VERSION "DNNBNNNYNNNNNNNNNNNNNNNNNNNNNNNNNNNNNNNNNN/4/%%%/4/'%**4NNN///"

NS_ :

BS_:

BU_: Vector__XXX SODX PC

BO_ 271 MB79_TARGET_DETECTION_4B: 8 SODX
 SG_ StdAzimuth_4 : 63|8@0+ (0.0009766,0) [0|14.31] "°"  PC
 SG_ PowerDB_4 : 7|8@0+ (1,0) [0|255] "db"  PC
 SG_ CoGRange_4 : 15|16@0- (0.01,0) [0|96] "m"  PC
 SG_ CoGDoppler_4 : 31|16@0- (0.01,0) [-140|14] "m/s"  PC
 SG_ Azimuth_4 : 47|16@0- (0.1,0) [-180|180] "°"  PC

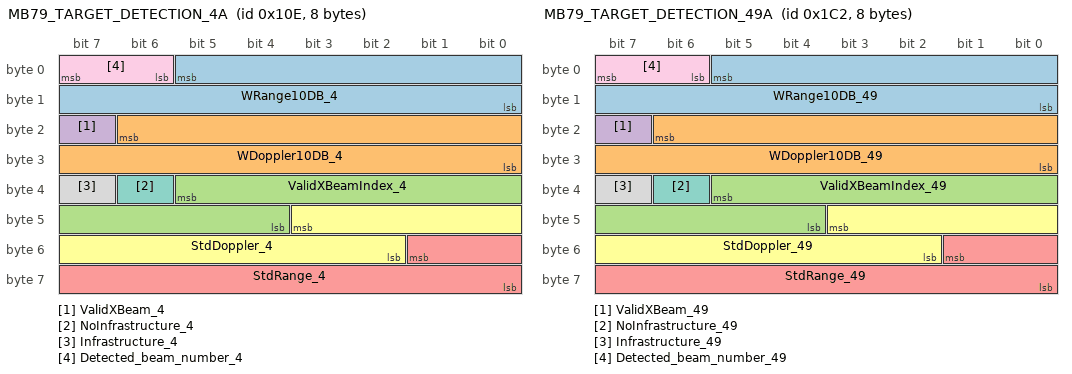
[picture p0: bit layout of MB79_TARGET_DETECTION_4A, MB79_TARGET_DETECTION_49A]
BO_ 270 MB79_TARGET_DETECTION_4A: 8 SODX
 SG_ WRange10DB_4 : 5|14@0+ (0.01,0) [0|96] "m"  PC
 SG_ WDoppler10DB_4 : 22|15@0+ (0.01,0) [0|280] "m/s"  PC
 SG_ ValidXBeamIndex_4 : 37|10@0+ (1,0) [0|0] "n/a"  PC
 SG_ ValidXBeam_4 : 23|1@0+ (1,0) [0|0] "n/a"  PC
 SG_ StdRange_4 : 49|10@0+ (0.01,0) [0|10] "m"  PC
 SG_ StdDoppler_4 : 43|10@0+ (0.01,0) [0|10] "m/s"  PC
 SG_ NoInfrastructure_4 : 38|1@0+ (1,0) [0|0] "n/a"  PC
 SG_ Infrastructure_4 : 39|1@0+ (1,0) [0|0] "n/a"  PC
 SG_ Detected_beam_number_4 : 7|2@0+ (1,0) [0|0] "n/a"  PC

BO_ 453 MB79_TARGET_DETECTION_49D: 8 SODX
 SG_ Complex4_Re_49 : 39|16@0- (1,0) [-32768|32767] "n/a"  PC
 SG_ Complex4_Im_49 : 55|16@0- (1,0) [-32768|32767] "n/a"  PC
 SG_ Complex3_Re_49 : 7|16@0- (1,0) [-32768|32767] "n/a"  PC
 SG_ Complex3_Im_49 : 23|16@0- (1,0) [-32768|32767] "n/a"  PC

BO_ 452 MB79_TARGET_DETECTION_49C: 8 SODX
 SG_ Complex2_Re_49 : 39|16@0- (1,0) [-32768|32767] "n/a"  PC
 SG_ Complex2_Im_49 : 55|16@0- (1,0) [-32768|32767] "n/a"  PC
 SG_ Complex1_Re_49 : 7|16@0- (1,0) [-32768|32767] "n/a"  PC
 SG_ Complex1_Im_49 : 23|16@0- (1,0) [-32768|32767] "n/a"  PC

BO_ 451 MB79_TARGET_DETECTION_49B: 8 SODX
 SG_ StdAzimuth_49 : 63|8@0+ (0.0009766,0) [0|14.31] "°"  PC
 SG_ PowerDB_49 : 7|8@0+ (1,0) [0|255] "db"  PC
 SG_ CoGRange_49 : 15|16@0- (0.01,0) [0|96] "m"  PC
 SG_ CoGDoppler_49 : 31|16@0- (0.01,0) [-140|14] "m/s"  PC
 SG_ Azimuth_49 : 47|16@0- (0.1,0) [-180|180] "°"  PC

BO_ 450 MB79_TARGET_DETECTION_49A: 8 SODX
 SG_ WRange10DB_49 : 5|14@0+ (0.01,0) [0|96] "m"  PC
 SG_ WDoppler10DB_49 : 22|15@0+ (0.01,0) [0|280] "m/s"  PC
 SG_ ValidXBeamIndex_49 : 37|10@0+ (1,0) [0|0] "n/a"  PC
 SG_ ValidXBeam_49 : 23|1@0+ (1,0) [0|0] "n/a"  PC
 SG_ StdRange_49 : 49|10@0+ (0.01,0) [0|10] "m"  PC
 SG_ StdDoppler_49 : 43|10@0+ (0.01,0) [0|10] "m/s"  PC
 SG_ NoInfrastructure_49 : 38|1@0+ (1,0) [0|0] "n/a"  PC
 SG_ Infrastructure_49 : 39|1@0+ (1,0) [0|0] "n/a"  PC
 SG_ Detected_beam_number_49 : 7|2@0+ (1,0) [0|0] "n/a"  PC

BO_ 449 MB79_TARGET_DETECTION_48D: 8 SODX
 SG_ Complex4_Re_48 : 39|16@0- (1,0) [-32768|32767] "n/a"  PC
 SG_ Complex4_Im_48 : 55|16@0- (1,0) [-32768|32767] "n/a"  PC
 SG_ Complex3_Re_48 : 7|16@0- (1,0) [-32768|32767] "n/a"  PC
 SG_ Complex3_Im_48 : 23|16@0- (1,0) [-32768|32767] "n/a"  PC

BO_ 448 MB79_TARGET_DETECTION_48C: 8 SODX
 SG_ Complex2_Re_48 : 39|16@0- (1,0) [-32768|32767] "n/a"  PC
 SG_ Complex2_Im_48 : 55|16@0- (1,0) [-32768|32767] "n/a"  PC
 SG_ Complex1_Re_48 : 7|16@0- (1,0) [-32768|32767] "n/a"  PC
 SG_ Complex1_Im_48 : 23|16@0- (1,0) [-32768|32767] "n/a"  PC

BO_ 447 MB79_TARGET_DETECTION_48B: 8 SODX
 SG_ StdAzimuth_48 : 63|8@0+ (0.0009766,0) [0|14.31] "°"  PC
 SG_ PowerDB_48 : 7|8@0+ (1,0) [0|255] "db"  PC
 SG_ CoGRange_48 : 15|16@0- (0.01,0) [0|96] "m"  PC
 SG_ CoGDoppler_48 : 31|16@0- (0.01,0) [-140|14] "m/s"  PC
 SG_ Azimuth_48 : 47|16@0- (0.1,0) [-180|180] "°"  PC

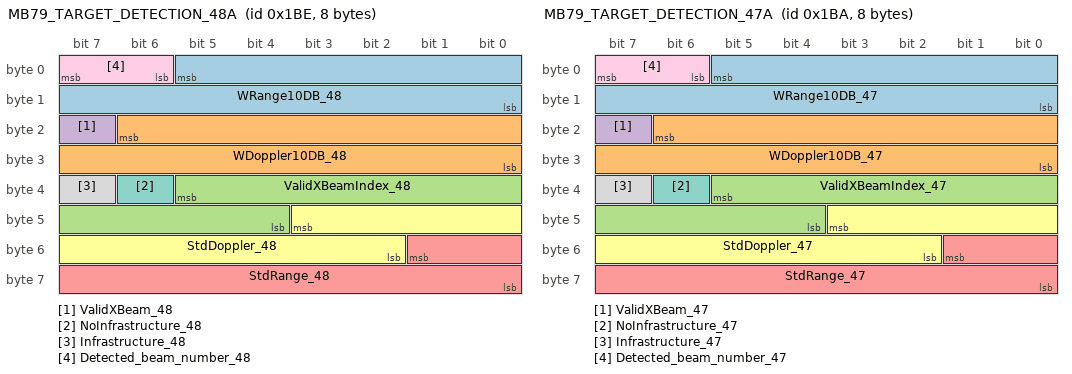
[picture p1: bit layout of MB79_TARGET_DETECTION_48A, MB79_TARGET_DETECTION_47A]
BO_ 446 MB79_TARGET_DETECTION_48A: 8 SODX
 SG_ WRange10DB_48 : 5|14@0+ (0.01,0) [0|96] "m"  PC
 SG_ WDoppler10DB_48 : 22|15@0+ (0.01,0) [0|280] "m/s"  PC
 SG_ ValidXBeamIndex_48 : 37|10@0+ (1,0) [0|0] "n/a"  PC
 SG_ ValidXBeam_48 : 23|1@0+ (1,0) [0|0] "n/a"  PC
 SG_ StdRange_48 : 49|10@0+ (0.01,0) [0|10] "m"  PC
 SG_ StdDoppler_48 : 43|10@0+ (0.01,0) [0|10] "m/s"  PC
 SG_ NoInfrastructure_48 : 38|1@0+ (1,0) [0|0] "n/a"  PC
 SG_ Infrastructure_48 : 39|1@0+ (1,0) [0|0] "n/a"  PC
 SG_ Detected_beam_number_48 : 7|2@0+ (1,0) [0|0] "n/a"  PC

BO_ 445 MB79_TARGET_DETECTION_47D: 8 SODX
 SG_ Complex4_Re_47 : 39|16@0- (1,0) [-32768|32767] "n/a"  PC
 SG_ Complex4_Im_47 : 55|16@0- (1,0) [-32768|32767] "n/a"  PC
 SG_ Complex3_Re_47 : 7|16@0- (1,0) [-32768|32767] "n/a"  PC
 SG_ Complex3_Im_47 : 23|16@0- (1,0) [-32768|32767] "n/a"  PC

BO_ 444 MB79_TARGET_DETECTION_47C: 8 SODX
 SG_ Complex2_Re_47 : 39|16@0- (1,0) [-32768|32767] "n/a"  PC
 SG_ Complex2_Im_47 : 55|16@0- (1,0) [-32768|32767] "n/a"  PC
 SG_ Complex1_Re_47 : 7|16@0- (1,0) [-32768|32767] "n/a"  PC
 SG_ Complex1_Im_47 : 23|16@0- (1,0) [-32768|32767] "n/a"  PC

BO_ 443 MB79_TARGET_DETECTION_47B: 8 SODX
 SG_ StdAzimuth_47 : 63|8@0+ (0.0009766,0) [0|14.31] "°"  PC
 SG_ PowerDB_47 : 7|8@0+ (1,0) [0|255] "db"  PC
 SG_ CoGRange_47 : 15|16@0- (0.01,0) [0|96] "m"  PC
 SG_ CoGDoppler_47 : 31|16@0- (0.01,0) [-140|14] "m/s"  PC
 SG_ Azimuth_47 : 47|16@0- (0.1,0) [-180|180] "°"  PC

BO_ 442 MB79_TARGET_DETECTION_47A: 8 SODX
 SG_ WRange10DB_47 : 5|14@0+ (0.01,0) [0|96] "m"  PC
 SG_ WDoppler10DB_47 : 22|15@0+ (0.01,0) [0|280] "m/s"  PC
 SG_ ValidXBeamIndex_47 : 37|10@0+ (1,0) [0|0] "n/a"  PC
 SG_ ValidXBeam_47 : 23|1@0+ (1,0) [0|0] "n/a"  PC
 SG_ StdRange_47 : 49|10@0+ (0.01,0) [0|10] "m"  PC
 SG_ StdDoppler_47 : 43|10@0+ (0.01,0) [0|10] "m/s"  PC
 SG_ NoInfrastructure_47 : 38|1@0+ (1,0) [0|0] "n/a"  PC
 SG_ Infrastructure_47 : 39|1@0+ (1,0) [0|0] "n/a"  PC
 SG_ Detected_beam_number_47 : 7|2@0+ (1,0) [0|0] "n/a"  PC

BO_ 441 MB79_TARGET_DETECTION_46D: 8 SODX
 SG_ Complex4_Re_46 : 39|16@0- (1,0) [-32768|32767] "n/a"  PC
 SG_ Complex4_Im_46 : 55|16@0- (1,0) [-32768|32767] "n/a"  PC
 SG_ Complex3_Re_46 : 7|16@0- (1,0) [-32768|32767] "n/a"  PC
 SG_ Complex3_Im_46 : 23|16@0- (1,0) [-32768|32767] "n/a"  PC

BO_ 440 MB79_TARGET_DETECTION_46C: 8 SODX
 SG_ Complex2_Re_46 : 39|16@0- (1,0) [-32768|32767] "n/a"  PC
 SG_ Complex2_Im_46 : 55|16@0- (1,0) [-32768|32767] "n/a"  PC
 SG_ Complex1_Re_46 : 7|16@0- (1,0) [-32768|32767] "n/a"  PC
 SG_ Complex1_Im_46 : 23|16@0- (1,0) [-32768|32767] "n/a"  PC

BO_ 439 MB79_TARGET_DETECTION_46B: 8 SODX
 SG_ StdAzimuth_46 : 63|8@0+ (0.0009766,0) [0|14.31] "°"  PC
 SG_ PowerDB_46 : 7|8@0+ (1,0) [0|255] "db"  PC
 SG_ CoGRange_46 : 15|16@0- (0.01,0) [0|96] "m"  PC
 SG_ CoGDoppler_46 : 31|16@0- (0.01,0) [-140|14] "m/s"  PC
 SG_ Azimuth_46 : 47|16@0- (0.1,0) [-180|180] "°"  PC

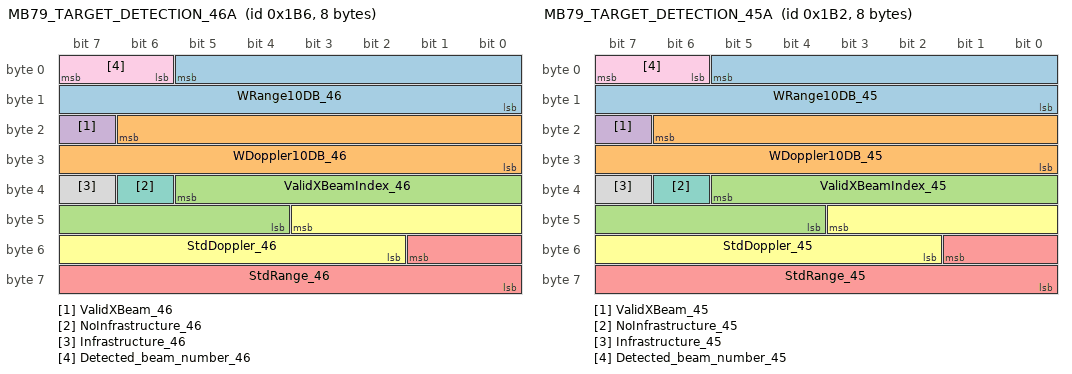
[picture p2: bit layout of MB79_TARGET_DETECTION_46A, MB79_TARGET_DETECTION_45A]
BO_ 438 MB79_TARGET_DETECTION_46A: 8 SODX
 SG_ WRange10DB_46 : 5|14@0+ (0.01,0) [0|96] "m"  PC
 SG_ WDoppler10DB_46 : 22|15@0+ (0.01,0) [0|280] "m/s"  PC
 SG_ ValidXBeamIndex_46 : 37|10@0+ (1,0) [0|0] "n/a"  PC
 SG_ ValidXBeam_46 : 23|1@0+ (1,0) [0|0] "n/a"  PC
 SG_ StdRange_46 : 49|10@0+ (0.01,0) [0|10] "m"  PC
 SG_ StdDoppler_46 : 43|10@0+ (0.01,0) [0|10] "m/s"  PC
 SG_ NoInfrastructure_46 : 38|1@0+ (1,0) [0|0] "n/a"  PC
 SG_ Infrastructure_46 : 39|1@0+ (1,0) [0|0] "n/a"  PC
 SG_ Detected_beam_number_46 : 7|2@0+ (1,0) [0|0] "n/a"  PC

BO_ 437 MB79_TARGET_DETECTION_45D: 8 SODX
 SG_ Complex4_Re_45 : 39|16@0- (1,0) [-32768|32767] "n/a"  PC
 SG_ Complex4_Im_45 : 55|16@0- (1,0) [-32768|32767] "n/a"  PC
 SG_ Complex3_Re_45 : 7|16@0- (1,0) [-32768|32767] "n/a"  PC
 SG_ Complex3_Im_45 : 23|16@0- (1,0) [-32768|32767] "n/a"  PC

BO_ 436 MB79_TARGET_DETECTION_45C: 8 SODX
 SG_ Complex2_Re_45 : 39|16@0- (1,0) [-32768|32767] "n/a"  PC
 SG_ Complex2_Im_45 : 55|16@0- (1,0) [-32768|32767] "n/a"  PC
 SG_ Complex1_Re_45 : 7|16@0- (1,0) [-32768|32767] "n/a"  PC
 SG_ Complex1_Im_45 : 23|16@0- (1,0) [-32768|32767] "n/a"  PC

BO_ 435 MB79_TARGET_DETECTION_45B: 8 SODX
 SG_ StdAzimuth_45 : 63|8@0+ (0.0009766,0) [0|14.31] "°"  PC
 SG_ PowerDB_45 : 7|8@0+ (1,0) [0|255] "db"  PC
 SG_ CoGRange_45 : 15|16@0- (0.01,0) [0|96] "m"  PC
 SG_ CoGDoppler_45 : 31|16@0- (0.01,0) [-140|14] "m/s"  PC
 SG_ Azimuth_45 : 47|16@0- (0.1,0) [-180|180] "°"  PC

BO_ 434 MB79_TARGET_DETECTION_45A: 8 SODX
 SG_ WRange10DB_45 : 5|14@0+ (0.01,0) [0|96] "m"  PC
 SG_ WDoppler10DB_45 : 22|15@0+ (0.01,0) [0|280] "m/s"  PC
 SG_ ValidXBeamIndex_45 : 37|10@0+ (1,0) [0|0] "n/a"  PC
 SG_ ValidXBeam_45 : 23|1@0+ (1,0) [0|0] "n/a"  PC
 SG_ StdRange_45 : 49|10@0+ (0.01,0) [0|10] "m"  PC
 SG_ StdDoppler_45 : 43|10@0+ (0.01,0) [0|10] "m/s"  PC
 SG_ NoInfrastructure_45 : 38|1@0+ (1,0) [0|0] "n/a"  PC
 SG_ Infrastructure_45 : 39|1@0+ (1,0) [0|0] "n/a"  PC
 SG_ Detected_beam_number_45 : 7|2@0+ (1,0) [0|0] "n/a"  PC

BO_ 433 MB79_TARGET_DETECTION_44D: 8 SODX
 SG_ Complex4_Re_44 : 39|16@0- (1,0) [-32768|32767] "n/a"  PC
 SG_ Complex4_Im_44 : 55|16@0- (1,0) [-32768|32767] "n/a"  PC
 SG_ Complex3_Re_44 : 7|16@0- (1,0) [-32768|32767] "n/a"  PC
 SG_ Complex3_Im_44 : 23|16@0- (1,0) [-32768|32767] "n/a"  PC

BO_ 432 MB79_TARGET_DETECTION_44C: 8 SODX
 SG_ Complex2_Re_44 : 39|16@0- (1,0) [-32768|32767] "n/a"  PC
 SG_ Complex2_Im_44 : 55|16@0- (1,0) [-32768|32767] "n/a"  PC
 SG_ Complex1_Re_44 : 7|16@0- (1,0) [-32768|32767] "n/a"  PC
 SG_ Complex1_Im_44 : 23|16@0- (1,0) [-32768|32767] "n/a"  PC

BO_ 431 MB79_TARGET_DETECTION_44B: 8 SODX
 SG_ StdAzimuth_44 : 63|8@0+ (0.0009766,0) [0|14.31] "°"  PC
 SG_ PowerDB_44 : 7|8@0+ (1,0) [0|255] "db"  PC
 SG_ CoGRange_44 : 15|16@0- (0.01,0) [0|96] "m"  PC
 SG_ CoGDoppler_44 : 31|16@0- (0.01,0) [-140|14] "m/s"  PC
 SG_ Azimuth_44 : 47|16@0- (0.1,0) [-180|180] "°"  PC

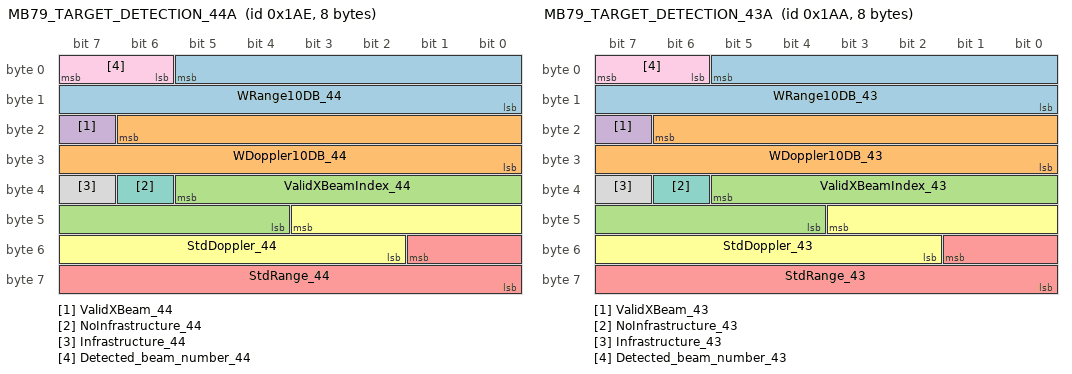
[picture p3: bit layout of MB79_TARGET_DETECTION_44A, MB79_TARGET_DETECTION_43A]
BO_ 430 MB79_TARGET_DETECTION_44A: 8 SODX
 SG_ WRange10DB_44 : 5|14@0+ (0.01,0) [0|96] "m"  PC
 SG_ WDoppler10DB_44 : 22|15@0+ (0.01,0) [0|280] "m/s"  PC
 SG_ ValidXBeamIndex_44 : 37|10@0+ (1,0) [0|0] "n/a"  PC
 SG_ ValidXBeam_44 : 23|1@0+ (1,0) [0|0] "n/a"  PC
 SG_ StdRange_44 : 49|10@0+ (0.01,0) [0|10] "m"  PC
 SG_ StdDoppler_44 : 43|10@0+ (0.01,0) [0|10] "m/s"  PC
 SG_ NoInfrastructure_44 : 38|1@0+ (1,0) [0|0] "n/a"  PC
 SG_ Infrastructure_44 : 39|1@0+ (1,0) [0|0] "n/a"  PC
 SG_ Detected_beam_number_44 : 7|2@0+ (1,0) [0|0] "n/a"  PC

BO_ 429 MB79_TARGET_DETECTION_43D: 8 SODX
 SG_ Complex4_Re_43 : 39|16@0- (1,0) [-32768|32767] "n/a"  PC
 SG_ Complex4_Im_43 : 55|16@0- (1,0) [-32768|32767] "n/a"  PC
 SG_ Complex3_Re_43 : 7|16@0- (1,0) [-32768|32767] "n/a"  PC
 SG_ Complex3_Im_43 : 23|16@0- (1,0) [-32768|32767] "n/a"  PC

BO_ 428 MB79_TARGET_DETECTION_43C: 8 SODX
 SG_ Complex2_Re_43 : 39|16@0- (1,0) [-32768|32767] "n/a"  PC
 SG_ Complex2_Im_43 : 55|16@0- (1,0) [-32768|32767] "n/a"  PC
 SG_ Complex1_Re_43 : 7|16@0- (1,0) [-32768|32767] "n/a"  PC
 SG_ Complex1_Im_43 : 23|16@0- (1,0) [-32768|32767] "n/a"  PC

BO_ 427 MB79_TARGET_DETECTION_43B: 8 SODX
 SG_ StdAzimuth_43 : 63|8@0+ (0.0009766,0) [0|14.31] "°"  PC
 SG_ PowerDB_43 : 7|8@0+ (1,0) [0|255] "db"  PC
 SG_ CoGRange_43 : 15|16@0- (0.01,0) [0|96] "m"  PC
 SG_ CoGDoppler_43 : 31|16@0- (0.01,0) [-140|14] "m/s"  PC
 SG_ Azimuth_43 : 47|16@0- (0.1,0) [-180|180] "°"  PC

BO_ 426 MB79_TARGET_DETECTION_43A: 8 SODX
 SG_ WRange10DB_43 : 5|14@0+ (0.01,0) [0|96] "m"  PC
 SG_ WDoppler10DB_43 : 22|15@0+ (0.01,0) [0|280] "m/s"  PC
 SG_ ValidXBeamIndex_43 : 37|10@0+ (1,0) [0|0] "n/a"  PC
 SG_ ValidXBeam_43 : 23|1@0+ (1,0) [0|0] "n/a"  PC
 SG_ StdRange_43 : 49|10@0+ (0.01,0) [0|10] "m"  PC
 SG_ StdDoppler_43 : 43|10@0+ (0.01,0) [0|10] "m/s"  PC
 SG_ NoInfrastructure_43 : 38|1@0+ (1,0) [0|0] "n/a"  PC
 SG_ Infrastructure_43 : 39|1@0+ (1,0) [0|0] "n/a"  PC
 SG_ Detected_beam_number_43 : 7|2@0+ (1,0) [0|0] "n/a"  PC

BO_ 425 MB79_TARGET_DETECTION_42D: 8 SODX
 SG_ Complex4_Re_42 : 39|16@0- (1,0) [-32768|32767] "n/a"  PC
 SG_ Complex4_Im_42 : 55|16@0- (1,0) [-32768|32767] "n/a"  PC
 SG_ Complex3_Re_42 : 7|16@0- (1,0) [-32768|32767] "n/a"  PC
 SG_ Complex3_Im_42 : 23|16@0- (1,0) [-32768|32767] "n/a"  PC

BO_ 424 MB79_TARGET_DETECTION_42C: 8 SODX
 SG_ Complex2_Re_42 : 39|16@0- (1,0) [-32768|32767] "n/a"  PC
 SG_ Complex2_Im_42 : 55|16@0- (1,0) [-32768|32767] "n/a"  PC
 SG_ Complex1_Re_42 : 7|16@0- (1,0) [-32768|32767] "n/a"  PC
 SG_ Complex1_Im_42 : 23|16@0- (1,0) [-32768|32767] "n/a"  PC

BO_ 423 MB79_TARGET_DETECTION_42B: 8 SODX
 SG_ StdAzimuth_42 : 63|8@0+ (0.0009766,0) [0|14.31] "°"  PC
 SG_ PowerDB_42 : 7|8@0+ (1,0) [0|255] "db"  PC
 SG_ CoGRange_42 : 15|16@0- (0.01,0) [0|96] "m"  PC
 SG_ CoGDoppler_42 : 31|16@0- (0.01,0) [-140|14] "m/s"  PC
 SG_ Azimuth_42 : 47|16@0- (0.1,0) [-180|180] "°"  PC

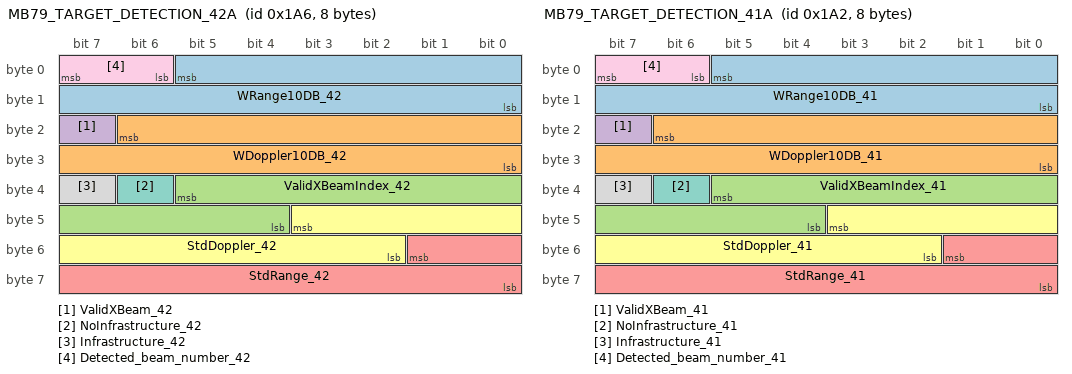
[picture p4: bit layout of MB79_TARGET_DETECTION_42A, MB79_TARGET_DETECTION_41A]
BO_ 422 MB79_TARGET_DETECTION_42A: 8 SODX
 SG_ WRange10DB_42 : 5|14@0+ (0.01,0) [0|96] "m"  PC
 SG_ WDoppler10DB_42 : 22|15@0+ (0.01,0) [0|280] "m/s"  PC
 SG_ ValidXBeamIndex_42 : 37|10@0+ (1,0) [0|0] "n/a"  PC
 SG_ ValidXBeam_42 : 23|1@0+ (1,0) [0|0] "n/a"  PC
 SG_ StdRange_42 : 49|10@0+ (0.01,0) [0|10] "m"  PC
 SG_ StdDoppler_42 : 43|10@0+ (0.01,0) [0|10] "m/s"  PC
 SG_ NoInfrastructure_42 : 38|1@0+ (1,0) [0|0] "n/a"  PC
 SG_ Infrastructure_42 : 39|1@0+ (1,0) [0|0] "n/a"  PC
 SG_ Detected_beam_number_42 : 7|2@0+ (1,0) [0|0] "n/a"  PC

BO_ 421 MB79_TARGET_DETECTION_41D: 8 SODX
 SG_ Complex4_Re_41 : 39|16@0- (1,0) [-32768|32767] "n/a"  PC
 SG_ Complex4_Im_41 : 55|16@0- (1,0) [-32768|32767] "n/a"  PC
 SG_ Complex3_Re_41 : 7|16@0- (1,0) [-32768|32767] "n/a"  PC
 SG_ Complex3_Im_41 : 23|16@0- (1,0) [-32768|32767] "n/a"  PC

BO_ 420 MB79_TARGET_DETECTION_41C: 8 SODX
 SG_ Complex2_Re_41 : 39|16@0- (1,0) [-32768|32767] "n/a"  PC
 SG_ Complex2_Im_41 : 55|16@0- (1,0) [-32768|32767] "n/a"  PC
 SG_ Complex1_Re_41 : 7|16@0- (1,0) [-32768|32767] "n/a"  PC
 SG_ Complex1_Im_41 : 23|16@0- (1,0) [-32768|32767] "n/a"  PC

BO_ 419 MB79_TARGET_DETECTION_41B: 8 SODX
 SG_ StdAzimuth_41 : 63|8@0+ (0.0009766,0) [0|14.31] "°"  PC
 SG_ PowerDB_41 : 7|8@0+ (1,0) [0|255] "db"  PC
 SG_ CoGRange_41 : 15|16@0- (0.01,0) [0|96] "m"  PC
 SG_ CoGDoppler_41 : 31|16@0- (0.01,0) [-140|14] "m/s"  PC
 SG_ Azimuth_41 : 47|16@0- (0.1,0) [-180|180] "°"  PC

BO_ 418 MB79_TARGET_DETECTION_41A: 8 SODX
 SG_ WRange10DB_41 : 5|14@0+ (0.01,0) [0|96] "m"  PC
 SG_ WDoppler10DB_41 : 22|15@0+ (0.01,0) [0|280] "m/s"  PC
 SG_ ValidXBeamIndex_41 : 37|10@0+ (1,0) [0|0] "n/a"  PC
 SG_ ValidXBeam_41 : 23|1@0+ (1,0) [0|0] "n/a"  PC
 SG_ StdRange_41 : 49|10@0+ (0.01,0) [0|10] "m"  PC
 SG_ StdDoppler_41 : 43|10@0+ (0.01,0) [0|10] "m/s"  PC
 SG_ NoInfrastructure_41 : 38|1@0+ (1,0) [0|0] "n/a"  PC
 SG_ Infrastructure_41 : 39|1@0+ (1,0) [0|0] "n/a"  PC
 SG_ Detected_beam_number_41 : 7|2@0+ (1,0) [0|0] "n/a"  PC

BO_ 417 MB79_TARGET_DETECTION_40D: 8 SODX
 SG_ Complex4_Re_40 : 39|16@0- (1,0) [-32768|32767] "n/a"  PC
 SG_ Complex4_Im_40 : 55|16@0- (1,0) [-32768|32767] "n/a"  PC
 SG_ Complex3_Re_40 : 7|16@0- (1,0) [-32768|32767] "n/a"  PC
 SG_ Complex3_Im_40 : 23|16@0- (1,0) [-32768|32767] "n/a"  PC

BO_ 416 MB79_TARGET_DETECTION_40C: 8 SODX
 SG_ Complex2_Re_40 : 39|16@0- (1,0) [-32768|32767] "n/a"  PC
 SG_ Complex2_Im_40 : 55|16@0- (1,0) [-32768|32767] "n/a"  PC
 SG_ Complex1_Re_40 : 7|16@0- (1,0) [-32768|32767] "n/a"  PC
 SG_ Complex1_Im_40 : 23|16@0- (1,0) [-32768|32767] "n/a"  PC

BO_ 415 MB79_TARGET_DETECTION_40B: 8 SODX
 SG_ StdAzimuth_40 : 63|8@0+ (0.0009766,0) [0|14.31] "°"  PC
 SG_ PowerDB_40 : 7|8@0+ (1,0) [0|255] "db"  PC
 SG_ CoGRange_40 : 15|16@0- (0.01,0) [0|96] "m"  PC
 SG_ CoGDoppler_40 : 31|16@0- (0.01,0) [-140|14] "m/s"  PC
 SG_ Azimuth_40 : 47|16@0- (0.1,0) [-180|180] "°"  PC

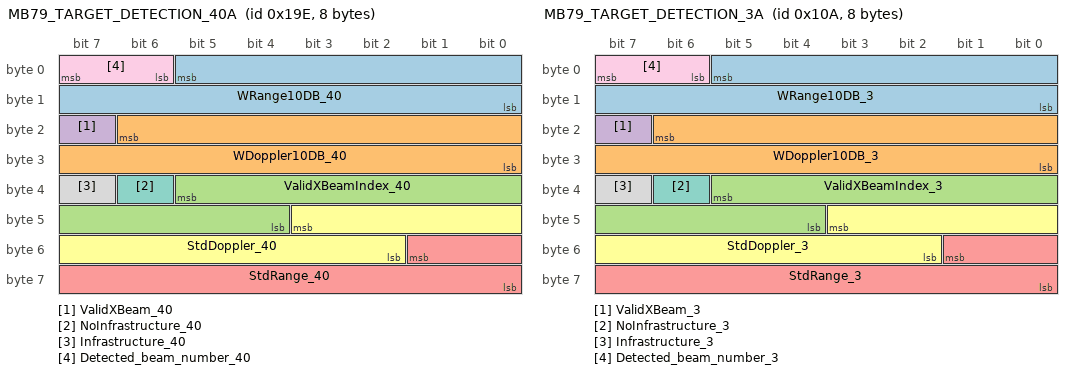
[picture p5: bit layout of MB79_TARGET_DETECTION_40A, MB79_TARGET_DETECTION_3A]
BO_ 414 MB79_TARGET_DETECTION_40A: 8 SODX
 SG_ WRange10DB_40 : 5|14@0+ (0.01,0) [0|96] "m"  PC
 SG_ WDoppler10DB_40 : 22|15@0+ (0.01,0) [0|280] "m/s"  PC
 SG_ ValidXBeamIndex_40 : 37|10@0+ (1,0) [0|0] "n/a"  PC
 SG_ ValidXBeam_40 : 23|1@0+ (1,0) [0|0] "n/a"  PC
 SG_ StdRange_40 : 49|10@0+ (0.01,0) [0|10] "m"  PC
 SG_ StdDoppler_40 : 43|10@0+ (0.01,0) [0|10] "m/s"  PC
 SG_ NoInfrastructure_40 : 38|1@0+ (1,0) [0|0] "n/a"  PC
 SG_ Infrastructure_40 : 39|1@0+ (1,0) [0|0] "n/a"  PC
 SG_ Detected_beam_number_40 : 7|2@0+ (1,0) [0|0] "n/a"  PC

BO_ 269 MB79_TARGET_DETECTION_3D: 8 SODX
 SG_ Complex4_Re_3 : 39|16@0- (1,0) [-32768|32767] "n/a"  PC
 SG_ Complex4_Im_3 : 55|16@0- (1,0) [-32768|32767] "n/a"  PC
 SG_ Complex3_Re_3 : 7|16@0- (1,0) [-32768|32767] "n/a"  PC
 SG_ Complex3_Im_3 : 23|16@0- (1,0) [-32768|32767] "n/a"  PC

BO_ 268 MB79_TARGET_DETECTION_3C: 8 SODX
 SG_ Complex2_Re_3 : 39|16@0- (1,0) [-32768|32767] "n/a"  PC
 SG_ Complex2_Im_3 : 55|16@0- (1,0) [-32768|32767] "n/a"  PC
 SG_ Complex1_Re_3 : 7|16@0- (1,0) [-32768|32767] "n/a"  PC
 SG_ Complex1_Im_3 : 23|16@0- (1,0) [-32768|32767] "n/a"  PC

BO_ 267 MB79_TARGET_DETECTION_3B: 8 SODX
 SG_ StdAzimuth_3 : 63|8@0+ (0.0009766,0) [0|14.31] "°"  PC
 SG_ PowerDB_3 : 7|8@0+ (1,0) [0|255] "db"  PC
 SG_ CoGRange_3 : 15|16@0- (0.01,0) [0|96] "m"  PC
 SG_ CoGDoppler_3 : 31|16@0- (0.01,0) [-140|14] "m/s"  PC
 SG_ Azimuth_3 : 47|16@0- (0.1,0) [-180|180] "°"  PC

BO_ 266 MB79_TARGET_DETECTION_3A: 8 SODX
 SG_ WRange10DB_3 : 5|14@0+ (0.01,0) [0|96] "m"  PC
 SG_ WDoppler10DB_3 : 22|15@0+ (0.01,0) [0|280] "m/s"  PC
 SG_ ValidXBeamIndex_3 : 37|10@0+ (1,0) [0|0] "n/a"  PC
 SG_ ValidXBeam_3 : 23|1@0+ (1,0) [0|0] "n/a"  PC
 SG_ StdRange_3 : 49|10@0+ (0.01,0) [0|10] "m"  PC
 SG_ StdDoppler_3 : 43|10@0+ (0.01,0) [0|10] "m/s"  PC
 SG_ NoInfrastructure_3 : 38|1@0+ (1,0) [0|0] "n/a"  PC
 SG_ Infrastructure_3 : 39|1@0+ (1,0) [0|0] "n/a"  PC
 SG_ Detected_beam_number_3 : 7|2@0+ (1,0) [0|0] "n/a"  PC

BO_ 413 MB79_TARGET_DETECTION_39D: 8 SODX
 SG_ Complex4_Re_39 : 39|16@0- (1,0) [-32768|32767] "n/a"  PC
 SG_ Complex4_Im_39 : 55|16@0- (1,0) [-32768|32767] "n/a"  PC
 SG_ Complex3_Re_39 : 7|16@0- (1,0) [-32768|32767] "n/a"  PC
 SG_ Complex3_Im_39 : 23|16@0- (1,0) [-32768|32767] "n/a"  PC

BO_ 412 MB79_TARGET_DETECTION_39C: 8 SODX
 SG_ Complex2_Re_39 : 39|16@0- (1,0) [-32768|32767] "n/a"  PC
 SG_ Complex2_Im_39 : 55|16@0- (1,0) [-32768|32767] "n/a"  PC
 SG_ Complex1_Re_39 : 7|16@0- (1,0) [-32768|32767] "n/a"  PC
 SG_ Complex1_Im_39 : 23|16@0- (1,0) [-32768|32767] "n/a"  PC

BO_ 411 MB79_TARGET_DETECTION_39B: 8 SODX
 SG_ StdAzimuth_39 : 63|8@0+ (0.0009766,0) [0|14.31] "°"  PC
 SG_ PowerDB_39 : 7|8@0+ (1,0) [0|255] "db"  PC
 SG_ CoGRange_39 : 15|16@0- (0.01,0) [0|96] "m"  PC
 SG_ CoGDoppler_39 : 31|16@0- (0.01,0) [-140|14] "m/s"  PC
 SG_ Azimuth_39 : 47|16@0- (0.1,0) [-180|180] "°"  PC

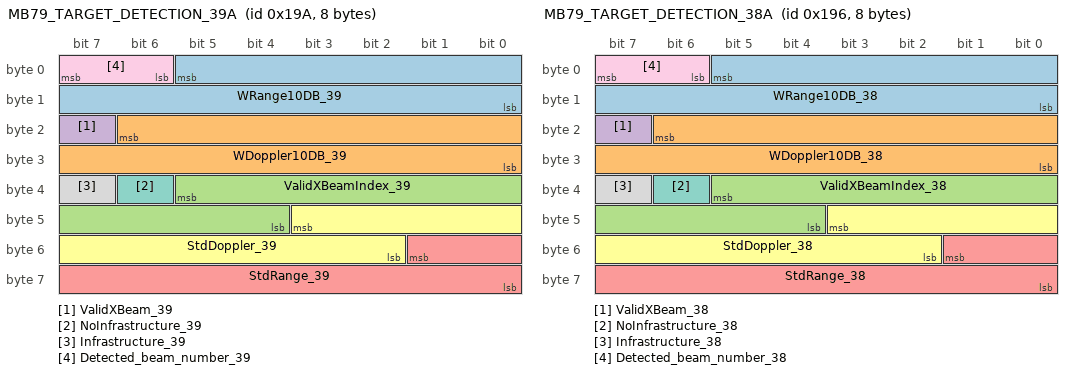
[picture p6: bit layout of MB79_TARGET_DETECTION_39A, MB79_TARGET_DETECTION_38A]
BO_ 410 MB79_TARGET_DETECTION_39A: 8 SODX
 SG_ WRange10DB_39 : 5|14@0+ (0.01,0) [0|96] "m"  PC
 SG_ WDoppler10DB_39 : 22|15@0+ (0.01,0) [0|280] "m/s"  PC
 SG_ ValidXBeamIndex_39 : 37|10@0+ (1,0) [0|0] "n/a"  PC
 SG_ ValidXBeam_39 : 23|1@0+ (1,0) [0|0] "n/a"  PC
 SG_ StdRange_39 : 49|10@0+ (0.01,0) [0|10] "m"  PC
 SG_ StdDoppler_39 : 43|10@0+ (0.01,0) [0|10] "m/s"  PC
 SG_ NoInfrastructure_39 : 38|1@0+ (1,0) [0|0] "n/a"  PC
 SG_ Infrastructure_39 : 39|1@0+ (1,0) [0|0] "n/a"  PC
 SG_ Detected_beam_number_39 : 7|2@0+ (1,0) [0|0] "n/a"  PC

BO_ 409 MB79_TARGET_DETECTION_38D: 8 SODX
 SG_ Complex4_Re_38 : 39|16@0- (1,0) [-32768|32767] "n/a"  PC
 SG_ Complex4_Im_38 : 55|16@0- (1,0) [-32768|32767] "n/a"  PC
 SG_ Complex3_Re_38 : 7|16@0- (1,0) [-32768|32767] "n/a"  PC
 SG_ Complex3_Im_38 : 23|16@0- (1,0) [-32768|32767] "n/a"  PC

BO_ 408 MB79_TARGET_DETECTION_38C: 8 SODX
 SG_ Complex2_Re_38 : 39|16@0- (1,0) [-32768|32767] "n/a"  PC
 SG_ Complex2_Im_38 : 55|16@0- (1,0) [-32768|32767] "n/a"  PC
 SG_ Complex1_Re_38 : 7|16@0- (1,0) [-32768|32767] "n/a"  PC
 SG_ Complex1_Im_38 : 23|16@0- (1,0) [-32768|32767] "n/a"  PC

BO_ 407 MB79_TARGET_DETECTION_38B: 8 SODX
 SG_ StdAzimuth_38 : 63|8@0+ (0.0009766,0) [0|14.31] "°"  PC
 SG_ PowerDB_38 : 7|8@0+ (1,0) [0|255] "db"  PC
 SG_ CoGRange_38 : 15|16@0- (0.01,0) [0|96] "m"  PC
 SG_ CoGDoppler_38 : 31|16@0- (0.01,0) [-140|14] "m/s"  PC
 SG_ Azimuth_38 : 47|16@0- (0.1,0) [-180|180] "°"  PC

BO_ 406 MB79_TARGET_DETECTION_38A: 8 SODX
 SG_ WRange10DB_38 : 5|14@0+ (0.01,0) [0|96] "m"  PC
 SG_ WDoppler10DB_38 : 22|15@0+ (0.01,0) [0|280] "m/s"  PC
 SG_ ValidXBeamIndex_38 : 37|10@0+ (1,0) [0|0] "n/a"  PC
 SG_ ValidXBeam_38 : 23|1@0+ (1,0) [0|0] "n/a"  PC
 SG_ StdRange_38 : 49|10@0+ (0.01,0) [0|10] "m"  PC
 SG_ StdDoppler_38 : 43|10@0+ (0.01,0) [0|10] "m/s"  PC
 SG_ NoInfrastructure_38 : 38|1@0+ (1,0) [0|0] "n/a"  PC
 SG_ Infrastructure_38 : 39|1@0+ (1,0) [0|0] "n/a"  PC
 SG_ Detected_beam_number_38 : 7|2@0+ (1,0) [0|0] "n/a"  PC

BO_ 405 MB79_TARGET_DETECTION_37D: 8 SODX
 SG_ Complex4_Re_37 : 39|16@0- (1,0) [-32768|32767] "n/a"  PC
 SG_ Complex4_Im_37 : 55|16@0- (1,0) [-32768|32767] "n/a"  PC
 SG_ Complex3_Re_37 : 7|16@0- (1,0) [-32768|32767] "n/a"  PC
 SG_ Complex3_Im_37 : 23|16@0- (1,0) [-32768|32767] "n/a"  PC

BO_ 404 MB79_TARGET_DETECTION_37C: 8 SODX
 SG_ Complex2_Re_37 : 39|16@0- (1,0) [-32768|32767] "n/a"  PC
 SG_ Complex2_Im_37 : 55|16@0- (1,0) [-32768|32767] "n/a"  PC
 SG_ Complex1_Re_37 : 7|16@0- (1,0) [-32768|32767] "n/a"  PC
 SG_ Complex1_Im_37 : 23|16@0- (1,0) [-32768|32767] "n/a"  PC

BO_ 403 MB79_TARGET_DETECTION_37B: 8 SODX
 SG_ StdAzimuth_37 : 63|8@0+ (0.0009766,0) [0|14.31] "°"  PC
 SG_ PowerDB_37 : 7|8@0+ (1,0) [0|255] "db"  PC
 SG_ CoGRange_37 : 15|16@0- (0.01,0) [0|96] "m"  PC
 SG_ CoGDoppler_37 : 31|16@0- (0.01,0) [-140|14] "m/s"  PC
 SG_ Azimuth_37 : 47|16@0- (0.1,0) [-180|180] "°"  PC

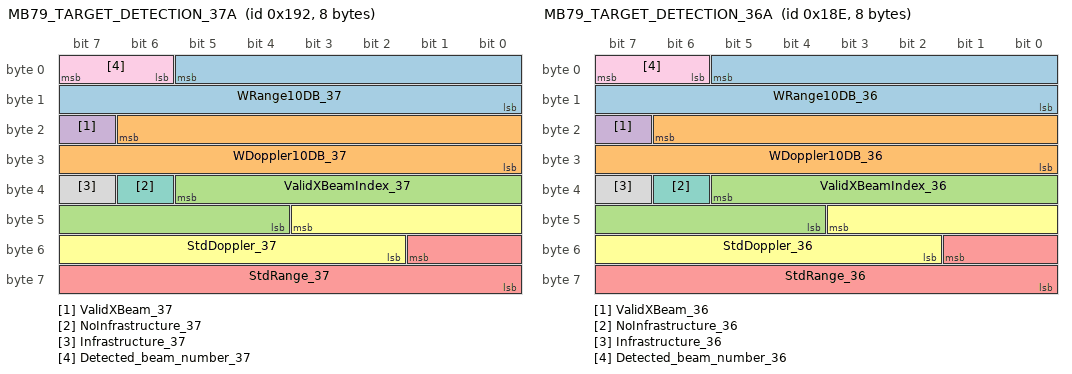
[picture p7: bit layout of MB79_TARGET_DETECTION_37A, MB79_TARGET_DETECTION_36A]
BO_ 402 MB79_TARGET_DETECTION_37A: 8 SODX
 SG_ WRange10DB_37 : 5|14@0+ (0.01,0) [0|96] "m"  PC
 SG_ WDoppler10DB_37 : 22|15@0+ (0.01,0) [0|280] "m/s"  PC
 SG_ ValidXBeamIndex_37 : 37|10@0+ (1,0) [0|0] "n/a"  PC
 SG_ ValidXBeam_37 : 23|1@0+ (1,0) [0|0] "n/a"  PC
 SG_ StdRange_37 : 49|10@0+ (0.01,0) [0|10] "m"  PC
 SG_ StdDoppler_37 : 43|10@0+ (0.01,0) [0|10] "m/s"  PC
 SG_ NoInfrastructure_37 : 38|1@0+ (1,0) [0|0] "n/a"  PC
 SG_ Infrastructure_37 : 39|1@0+ (1,0) [0|0] "n/a"  PC
 SG_ Detected_beam_number_37 : 7|2@0+ (1,0) [0|0] "n/a"  PC

BO_ 401 MB79_TARGET_DETECTION_36D: 8 SODX
 SG_ Complex4_Re_36 : 39|16@0- (1,0) [-32768|32767] "n/a"  PC
 SG_ Complex4_Im_36 : 55|16@0- (1,0) [-32768|32767] "n/a"  PC
 SG_ Complex3_Re_36 : 7|16@0- (1,0) [-32768|32767] "n/a"  PC
 SG_ Complex3_Im_36 : 23|16@0- (1,0) [-32768|32767] "n/a"  PC

BO_ 400 MB79_TARGET_DETECTION_36C: 8 SODX
 SG_ Complex2_Re_36 : 39|16@0- (1,0) [-32768|32767] "n/a"  PC
 SG_ Complex2_Im_36 : 55|16@0- (1,0) [-32768|32767] "n/a"  PC
 SG_ Complex1_Re_36 : 7|16@0- (1,0) [-32768|32767] "n/a"  PC
 SG_ Complex1_Im_36 : 23|16@0- (1,0) [-32768|32767] "n/a"  PC

BO_ 399 MB79_TARGET_DETECTION_36B: 8 SODX
 SG_ StdAzimuth_36 : 63|8@0+ (0.0009766,0) [0|14.31] "°"  PC
 SG_ PowerDB_36 : 7|8@0+ (1,0) [0|255] "db"  PC
 SG_ CoGRange_36 : 15|16@0- (0.01,0) [0|96] "m"  PC
 SG_ CoGDoppler_36 : 31|16@0- (0.01,0) [-140|14] "m/s"  PC
 SG_ Azimuth_36 : 47|16@0- (0.1,0) [-180|180] "°"  PC

BO_ 398 MB79_TARGET_DETECTION_36A: 8 SODX
 SG_ WRange10DB_36 : 5|14@0+ (0.01,0) [0|96] "m"  PC
 SG_ WDoppler10DB_36 : 22|15@0+ (0.01,0) [0|280] "m/s"  PC
 SG_ ValidXBeamIndex_36 : 37|10@0+ (1,0) [0|0] "n/a"  PC
 SG_ ValidXBeam_36 : 23|1@0+ (1,0) [0|0] "n/a"  PC
 SG_ StdRange_36 : 49|10@0+ (0.01,0) [0|10] "m"  PC
 SG_ StdDoppler_36 : 43|10@0+ (0.01,0) [0|10] "m/s"  PC
 SG_ NoInfrastructure_36 : 38|1@0+ (1,0) [0|0] "n/a"  PC
 SG_ Infrastructure_36 : 39|1@0+ (1,0) [0|0] "n/a"  PC
 SG_ Detected_beam_number_36 : 7|2@0+ (1,0) [0|0] "n/a"  PC

BO_ 397 MB79_TARGET_DETECTION_35D: 8 SODX
 SG_ Complex4_Re_35 : 39|16@0- (1,0) [-32768|32767] "n/a"  PC
 SG_ Complex4_Im_35 : 55|16@0- (1,0) [-32768|32767] "n/a"  PC
 SG_ Complex3_Re_35 : 7|16@0- (1,0) [-32768|32767] "n/a"  PC
 SG_ Complex3_Im_35 : 23|16@0- (1,0) [-32768|32767] "n/a"  PC

BO_ 396 MB79_TARGET_DETECTION_35C: 8 SODX
 SG_ Complex2_Re_35 : 39|16@0- (1,0) [-32768|32767] "n/a"  PC
 SG_ Complex2_Im_35 : 55|16@0- (1,0) [-32768|32767] "n/a"  PC
 SG_ Complex1_Re_35 : 7|16@0- (1,0) [-32768|32767] "n/a"  PC
 SG_ Complex1_Im_35 : 23|16@0- (1,0) [-32768|32767] "n/a"  PC

BO_ 395 MB79_TARGET_DETECTION_35B: 8 SODX
 SG_ StdAzimuth_35 : 63|8@0+ (0.0009766,0) [0|14.31] "°"  PC
 SG_ PowerDB_35 : 7|8@0+ (1,0) [0|255] "db"  PC
 SG_ CoGRange_35 : 15|16@0- (0.01,0) [0|96] "m"  PC
 SG_ CoGDoppler_35 : 31|16@0- (0.01,0) [-140|14] "m/s"  PC
 SG_ Azimuth_35 : 47|16@0- (0.1,0) [-180|180] "°"  PC

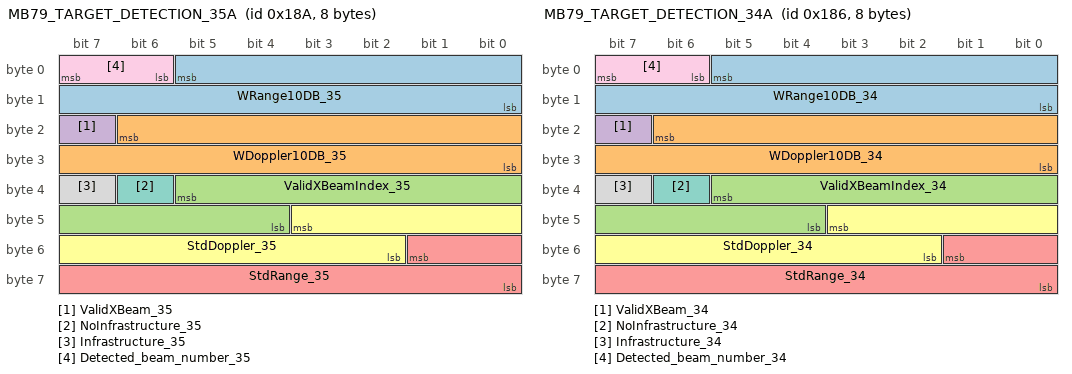
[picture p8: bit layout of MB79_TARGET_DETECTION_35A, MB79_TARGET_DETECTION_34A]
BO_ 394 MB79_TARGET_DETECTION_35A: 8 SODX
 SG_ WRange10DB_35 : 5|14@0+ (0.01,0) [0|96] "m"  PC
 SG_ WDoppler10DB_35 : 22|15@0+ (0.01,0) [0|280] "m/s"  PC
 SG_ ValidXBeamIndex_35 : 37|10@0+ (1,0) [0|0] "n/a"  PC
 SG_ ValidXBeam_35 : 23|1@0+ (1,0) [0|0] "n/a"  PC
 SG_ StdRange_35 : 49|10@0+ (0.01,0) [0|10] "m"  PC
 SG_ StdDoppler_35 : 43|10@0+ (0.01,0) [0|10] "m/s"  PC
 SG_ NoInfrastructure_35 : 38|1@0+ (1,0) [0|0] "n/a"  PC
 SG_ Infrastructure_35 : 39|1@0+ (1,0) [0|0] "n/a"  PC
 SG_ Detected_beam_number_35 : 7|2@0+ (1,0) [0|0] "n/a"  PC

BO_ 393 MB79_TARGET_DETECTION_34D: 8 SODX
 SG_ Complex4_Re_34 : 39|16@0- (1,0) [-32768|32767] "n/a"  PC
 SG_ Complex4_Im_34 : 55|16@0- (1,0) [-32768|32767] "n/a"  PC
 SG_ Complex3_Re_34 : 7|16@0- (1,0) [-32768|32767] "n/a"  PC
 SG_ Complex3_Im_34 : 23|16@0- (1,0) [-32768|32767] "n/a"  PC

BO_ 392 MB79_TARGET_DETECTION_34C: 8 SODX
 SG_ Complex2_Re_34 : 39|16@0- (1,0) [-32768|32767] "n/a"  PC
 SG_ Complex2_Im_34 : 55|16@0- (1,0) [-32768|32767] "n/a"  PC
 SG_ Complex1_Re_34 : 7|16@0- (1,0) [-32768|32767] "n/a"  PC
 SG_ Complex1_Im_34 : 23|16@0- (1,0) [-32768|32767] "n/a"  PC

BO_ 391 MB79_TARGET_DETECTION_34B: 8 SODX
 SG_ StdAzimuth_34 : 63|8@0+ (0.0009766,0) [0|14.31] "°"  PC
 SG_ PowerDB_34 : 7|8@0+ (1,0) [0|255] "db"  PC
 SG_ CoGRange_34 : 15|16@0- (0.01,0) [0|96] "m"  PC
 SG_ CoGDoppler_34 : 31|16@0- (0.01,0) [-140|14] "m/s"  PC
 SG_ Azimuth_34 : 47|16@0- (0.1,0) [-180|180] "°"  PC

BO_ 390 MB79_TARGET_DETECTION_34A: 8 SODX
 SG_ WRange10DB_34 : 5|14@0+ (0.01,0) [0|96] "m"  PC
 SG_ WDoppler10DB_34 : 22|15@0+ (0.01,0) [0|280] "m/s"  PC
 SG_ ValidXBeamIndex_34 : 37|10@0+ (1,0) [0|0] "n/a"  PC
 SG_ ValidXBeam_34 : 23|1@0+ (1,0) [0|0] "n/a"  PC
 SG_ StdRange_34 : 49|10@0+ (0.01,0) [0|10] "m"  PC
 SG_ StdDoppler_34 : 43|10@0+ (0.01,0) [0|10] "m/s"  PC
 SG_ NoInfrastructure_34 : 38|1@0+ (1,0) [0|0] "n/a"  PC
 SG_ Infrastructure_34 : 39|1@0+ (1,0) [0|0] "n/a"  PC
 SG_ Detected_beam_number_34 : 7|2@0+ (1,0) [0|0] "n/a"  PC

BO_ 389 MB79_TARGET_DETECTION_33D: 8 SODX
 SG_ Complex4_Re_33 : 39|16@0- (1,0) [-32768|32767] "n/a"  PC
 SG_ Complex4_Im_33 : 55|16@0- (1,0) [-32768|32767] "n/a"  PC
 SG_ Complex3_Re_33 : 7|16@0- (1,0) [-32768|32767] "n/a"  PC
 SG_ Complex3_Im_33 : 23|16@0- (1,0) [-32768|32767] "n/a"  PC

BO_ 388 MB79_TARGET_DETECTION_33C: 8 SODX
 SG_ Complex2_Re_33 : 39|16@0- (1,0) [-32768|32767] "n/a"  PC
 SG_ Complex2_Im_33 : 55|16@0- (1,0) [-32768|32767] "n/a"  PC
 SG_ Complex1_Re_33 : 7|16@0- (1,0) [-32768|32767] "n/a"  PC
 SG_ Complex1_Im_33 : 23|16@0- (1,0) [-32768|32767] "n/a"  PC

BO_ 387 MB79_TARGET_DETECTION_33B: 8 SODX
 SG_ StdAzimuth_33 : 63|8@0+ (0.0009766,0) [0|14.31] "°"  PC
 SG_ PowerDB_33 : 7|8@0+ (1,0) [0|255] "db"  PC
 SG_ CoGRange_33 : 15|16@0- (0.01,0) [0|96] "m"  PC
 SG_ CoGDoppler_33 : 31|16@0- (0.01,0) [-140|14] "m/s"  PC
 SG_ Azimuth_33 : 47|16@0- (0.1,0) [-180|180] "°"  PC

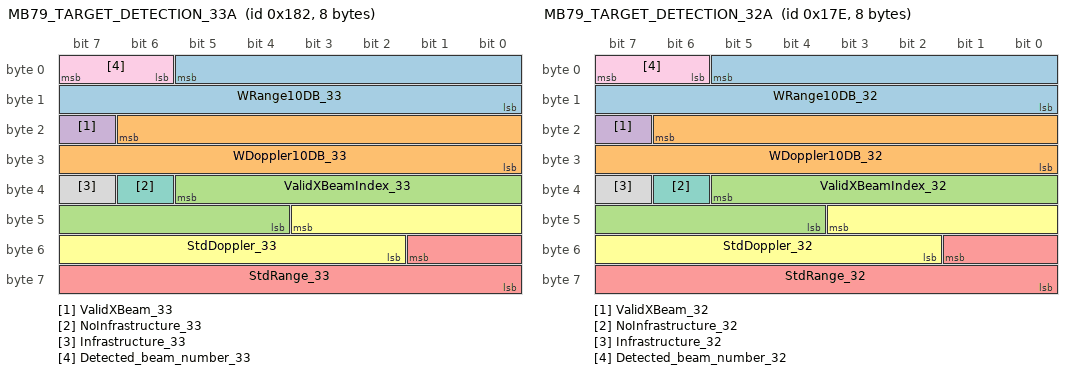
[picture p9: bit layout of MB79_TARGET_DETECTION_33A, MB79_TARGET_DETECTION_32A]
BO_ 386 MB79_TARGET_DETECTION_33A: 8 SODX
 SG_ WRange10DB_33 : 5|14@0+ (0.01,0) [0|96] "m"  PC
 SG_ WDoppler10DB_33 : 22|15@0+ (0.01,0) [0|280] "m/s"  PC
 SG_ ValidXBeamIndex_33 : 37|10@0+ (1,0) [0|0] "n/a"  PC
 SG_ ValidXBeam_33 : 23|1@0+ (1,0) [0|0] "n/a"  PC
 SG_ StdRange_33 : 49|10@0+ (0.01,0) [0|10] "m"  PC
 SG_ StdDoppler_33 : 43|10@0+ (0.01,0) [0|10] "m/s"  PC
 SG_ NoInfrastructure_33 : 38|1@0+ (1,0) [0|0] "n/a"  PC
 SG_ Infrastructure_33 : 39|1@0+ (1,0) [0|0] "n/a"  PC
 SG_ Detected_beam_number_33 : 7|2@0+ (1,0) [0|0] "n/a"  PC

BO_ 385 MB79_TARGET_DETECTION_32D: 8 SODX
 SG_ Complex4_Re_32 : 39|16@0- (1,0) [-32768|32767] "n/a"  PC
 SG_ Complex4_Im_32 : 55|16@0- (1,0) [-32768|32767] "n/a"  PC
 SG_ Complex3_Re_32 : 7|16@0- (1,0) [-32768|32767] "n/a"  PC
 SG_ Complex3_Im_32 : 23|16@0- (1,0) [-32768|32767] "n/a"  PC

BO_ 384 MB79_TARGET_DETECTION_32C: 8 SODX
 SG_ Complex2_Re_32 : 39|16@0- (1,0) [-32768|32767] "n/a"  PC
 SG_ Complex2_Im_32 : 55|16@0- (1,0) [-32768|32767] "n/a"  PC
 SG_ Complex1_Re_32 : 7|16@0- (1,0) [-32768|32767] "n/a"  PC
 SG_ Complex1_Im_32 : 23|16@0- (1,0) [-32768|32767] "n/a"  PC

BO_ 383 MB79_TARGET_DETECTION_32B: 8 SODX
 SG_ StdAzimuth_32 : 63|8@0+ (0.0009766,0) [0|14.31] "°"  PC
 SG_ PowerDB_32 : 7|8@0+ (1,0) [0|255] "db"  PC
 SG_ CoGRange_32 : 15|16@0- (0.01,0) [0|96] "m"  PC
 SG_ CoGDoppler_32 : 31|16@0- (0.01,0) [-140|14] "m/s"  PC
 SG_ Azimuth_32 : 47|16@0- (0.1,0) [-180|180] "°"  PC

BO_ 382 MB79_TARGET_DETECTION_32A: 8 SODX
 SG_ WRange10DB_32 : 5|14@0+ (0.01,0) [0|96] "m"  PC
 SG_ WDoppler10DB_32 : 22|15@0+ (0.01,0) [0|280] "m/s"  PC
 SG_ ValidXBeamIndex_32 : 37|10@0+ (1,0) [0|0] "n/a"  PC
 SG_ ValidXBeam_32 : 23|1@0+ (1,0) [0|0] "n/a"  PC
 SG_ StdRange_32 : 49|10@0+ (0.01,0) [0|10] "m"  PC
 SG_ StdDoppler_32 : 43|10@0+ (0.01,0) [0|10] "m/s"  PC
 SG_ NoInfrastructure_32 : 38|1@0+ (1,0) [0|0] "n/a"  PC
 SG_ Infrastructure_32 : 39|1@0+ (1,0) [0|0] "n/a"  PC
 SG_ Detected_beam_number_32 : 7|2@0+ (1,0) [0|0] "n/a"  PC

BO_ 381 MB79_TARGET_DETECTION_31D: 8 SODX
 SG_ Complex4_Re_31 : 39|16@0- (1,0) [-32768|32767] "n/a"  PC
 SG_ Complex4_Im_31 : 55|16@0- (1,0) [-32768|32767] "n/a"  PC
 SG_ Complex3_Re_31 : 7|16@0- (1,0) [-32768|32767] "n/a"  PC
 SG_ Complex3_Im_31 : 23|16@0- (1,0) [-32768|32767] "n/a"  PC

BO_ 380 MB79_TARGET_DETECTION_31C: 8 SODX
 SG_ Complex2_Re_31 : 39|16@0- (1,0) [-32768|32767] "n/a"  PC
 SG_ Complex2_Im_31 : 55|16@0- (1,0) [-32768|32767] "n/a"  PC
 SG_ Complex1_Re_31 : 7|16@0- (1,0) [-32768|32767] "n/a"  PC
 SG_ Complex1_Im_31 : 23|16@0- (1,0) [-32768|32767] "n/a"  PC

BO_ 379 MB79_TARGET_DETECTION_31B: 8 SODX
 SG_ StdAzimuth_31 : 63|8@0+ (0.0009766,0) [0|14.31] "°"  PC
 SG_ PowerDB_31 : 7|8@0+ (1,0) [0|255] "db"  PC
 SG_ CoGRange_31 : 15|16@0- (0.01,0) [0|96] "m"  PC
 SG_ CoGDoppler_31 : 31|16@0- (0.01,0) [-140|14] "m/s"  PC
 SG_ Azimuth_31 : 47|16@0- (0.1,0) [-180|180] "°"  PC

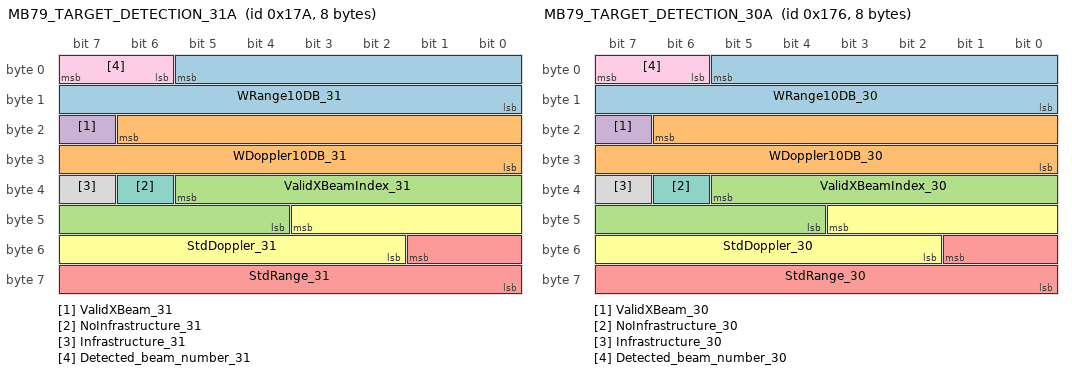
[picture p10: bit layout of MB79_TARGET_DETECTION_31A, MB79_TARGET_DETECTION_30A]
BO_ 378 MB79_TARGET_DETECTION_31A: 8 SODX
 SG_ WRange10DB_31 : 5|14@0+ (0.01,0) [0|96] "m"  PC
 SG_ WDoppler10DB_31 : 22|15@0+ (0.01,0) [0|280] "m/s"  PC
 SG_ ValidXBeamIndex_31 : 37|10@0+ (1,0) [0|0] "n/a"  PC
 SG_ ValidXBeam_31 : 23|1@0+ (1,0) [0|0] "n/a"  PC
 SG_ StdRange_31 : 49|10@0+ (0.01,0) [0|10] "m"  PC
 SG_ StdDoppler_31 : 43|10@0+ (0.01,0) [0|10] "m/s"  PC
 SG_ NoInfrastructure_31 : 38|1@0+ (1,0) [0|0] "n/a"  PC
 SG_ Infrastructure_31 : 39|1@0+ (1,0) [0|0] "n/a"  PC
 SG_ Detected_beam_number_31 : 7|2@0+ (1,0) [0|0] "n/a"  PC

BO_ 377 MB79_TARGET_DETECTION_30D: 8 SODX
 SG_ Complex4_Re_30 : 39|16@0- (1,0) [-32768|32767] "n/a"  PC
 SG_ Complex4_Im_30 : 55|16@0- (1,0) [-32768|32767] "n/a"  PC
 SG_ Complex3_Re_30 : 7|16@0- (1,0) [-32768|32767] "n/a"  PC
 SG_ Complex3_Im_30 : 23|16@0- (1,0) [-32768|32767] "n/a"  PC

BO_ 376 MB79_TARGET_DETECTION_30C: 8 SODX
 SG_ Complex2_Re_30 : 39|16@0- (1,0) [-32768|32767] "n/a"  PC
 SG_ Complex2_Im_30 : 55|16@0- (1,0) [-32768|32767] "n/a"  PC
 SG_ Complex1_Re_30 : 7|16@0- (1,0) [-32768|32767] "n/a"  PC
 SG_ Complex1_Im_30 : 23|16@0- (1,0) [-32768|32767] "n/a"  PC

BO_ 375 MB79_TARGET_DETECTION_30B: 8 SODX
 SG_ StdAzimuth_30 : 63|8@0+ (0.0009766,0) [0|14.31] "°"  PC
 SG_ PowerDB_30 : 7|8@0+ (1,0) [0|255] "db"  PC
 SG_ CoGRange_30 : 15|16@0- (0.01,0) [0|96] "m"  PC
 SG_ CoGDoppler_30 : 31|16@0- (0.01,0) [-140|14] "m/s"  PC
 SG_ Azimuth_30 : 47|16@0- (0.1,0) [-180|180] "°"  PC

BO_ 374 MB79_TARGET_DETECTION_30A: 8 SODX
 SG_ WRange10DB_30 : 5|14@0+ (0.01,0) [0|96] "m"  PC
 SG_ WDoppler10DB_30 : 22|15@0+ (0.01,0) [0|280] "m/s"  PC
 SG_ ValidXBeamIndex_30 : 37|10@0+ (1,0) [0|0] "n/a"  PC
 SG_ ValidXBeam_30 : 23|1@0+ (1,0) [0|0] "n/a"  PC
 SG_ StdRange_30 : 49|10@0+ (0.01,0) [0|10] "m"  PC
 SG_ StdDoppler_30 : 43|10@0+ (0.01,0) [0|10] "m/s"  PC
 SG_ NoInfrastructure_30 : 38|1@0+ (1,0) [0|0] "n/a"  PC
 SG_ Infrastructure_30 : 39|1@0+ (1,0) [0|0] "n/a"  PC
 SG_ Detected_beam_number_30 : 7|2@0+ (1,0) [0|0] "n/a"  PC

BO_ 265 MB79_TARGET_DETECTION_2D: 8 SODX
 SG_ Complex4_Re_2 : 39|16@0- (1,0) [-32768|32767] "n/a"  PC
 SG_ Complex4_Im_2 : 55|16@0- (1,0) [-32768|32767] "n/a"  PC
 SG_ Complex3_Re_2 : 7|16@0- (1,0) [-32768|32767] "n/a"  PC
 SG_ Complex3_Im_2 : 23|16@0- (1,0) [-32768|32767] "n/a"  PC

BO_ 264 MB79_TARGET_DETECTION_2C: 8 SODX
 SG_ Complex2_Re_2 : 39|16@0- (1,0) [-32768|32767] "n/a"  PC
 SG_ Complex2_Im_2 : 55|16@0- (1,0) [-32768|32767] "n/a"  PC
 SG_ Complex1_Re_2 : 7|16@0- (1,0) [-32768|32767] "n/a"  PC
 SG_ Complex1_Im_2 : 23|16@0- (1,0) [-32768|32767] "n/a"  PC

BO_ 263 MB79_TARGET_DETECTION_2B: 8 SODX
 SG_ StdAzimuth_2 : 63|8@0+ (0.0009766,0) [0|14.31] "°"  PC
 SG_ PowerDB_2 : 7|8@0+ (1,0) [0|255] "db"  PC
 SG_ CoGRange_2 : 15|16@0- (0.01,0) [0|96] "m"  PC
 SG_ CoGDoppler_2 : 31|16@0- (0.01,0) [-140|14] "m/s"  PC
 SG_ Azimuth_2 : 47|16@0- (0.1,0) [-180|180] "°"  PC

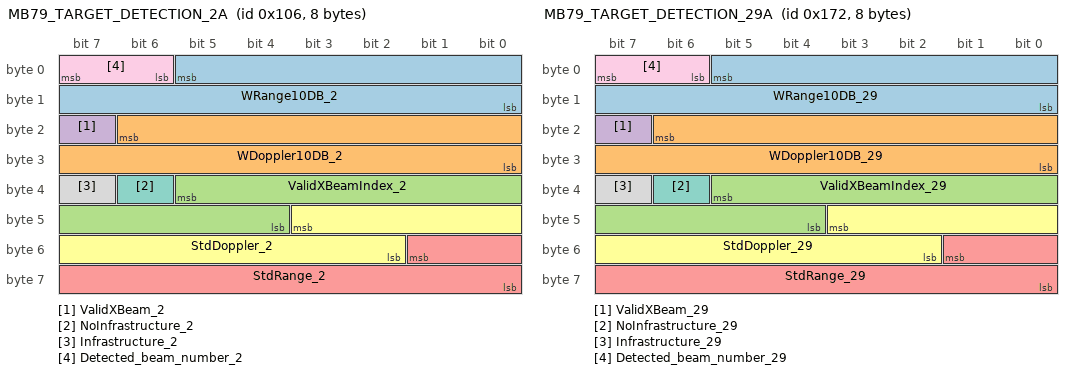
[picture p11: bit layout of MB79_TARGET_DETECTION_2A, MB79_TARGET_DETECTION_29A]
BO_ 262 MB79_TARGET_DETECTION_2A: 8 SODX
 SG_ WRange10DB_2 : 5|14@0+ (0.01,0) [0|96] "m"  PC
 SG_ WDoppler10DB_2 : 22|15@0+ (0.01,0) [0|280] "m/s"  PC
 SG_ ValidXBeamIndex_2 : 37|10@0+ (1,0) [0|0] "n/a"  PC
 SG_ ValidXBeam_2 : 23|1@0+ (1,0) [0|0] "n/a"  PC
 SG_ StdRange_2 : 49|10@0+ (0.01,0) [0|10] "m"  PC
 SG_ StdDoppler_2 : 43|10@0+ (0.01,0) [0|10] "m/s"  PC
 SG_ NoInfrastructure_2 : 38|1@0+ (1,0) [0|0] "n/a"  PC
 SG_ Infrastructure_2 : 39|1@0+ (1,0) [0|0] "n/a"  PC
 SG_ Detected_beam_number_2 : 7|2@0+ (1,0) [0|0] "n/a"  PC

BO_ 373 MB79_TARGET_DETECTION_29D: 8 SODX
 SG_ Complex4_Re_29 : 39|16@0- (1,0) [-32768|32767] "n/a"  PC
 SG_ Complex4_Im_29 : 55|16@0- (1,0) [-32768|32767] "n/a"  PC
 SG_ Complex3_Re_29 : 7|16@0- (1,0) [-32768|32767] "n/a"  PC
 SG_ Complex3_Im_29 : 23|16@0- (1,0) [-32768|32767] "n/a"  PC

BO_ 372 MB79_TARGET_DETECTION_29C: 8 SODX
 SG_ Complex2_Re_29 : 39|16@0- (1,0) [-32768|32767] "n/a"  PC
 SG_ Complex2_Im_29 : 55|16@0- (1,0) [-32768|32767] "n/a"  PC
 SG_ Complex1_Re_29 : 7|16@0- (1,0) [-32768|32767] "n/a"  PC
 SG_ Complex1_Im_29 : 23|16@0- (1,0) [-32768|32767] "n/a"  PC

BO_ 371 MB79_TARGET_DETECTION_29B: 8 SODX
 SG_ StdAzimuth_29 : 63|8@0+ (0.0009766,0) [0|14.31] "°"  PC
 SG_ PowerDB_29 : 7|8@0+ (1,0) [0|255] "db"  PC
 SG_ CoGRange_29 : 15|16@0- (0.01,0) [0|96] "m"  PC
 SG_ CoGDoppler_29 : 31|16@0- (0.01,0) [-140|14] "m/s"  PC
 SG_ Azimuth_29 : 47|16@0- (0.1,0) [-180|180] "°"  PC

BO_ 370 MB79_TARGET_DETECTION_29A: 8 SODX
 SG_ WRange10DB_29 : 5|14@0+ (0.01,0) [0|96] "m"  PC
 SG_ WDoppler10DB_29 : 22|15@0+ (0.01,0) [0|280] "m/s"  PC
 SG_ ValidXBeamIndex_29 : 37|10@0+ (1,0) [0|0] "n/a"  PC
 SG_ ValidXBeam_29 : 23|1@0+ (1,0) [0|0] "n/a"  PC
 SG_ StdRange_29 : 49|10@0+ (0.01,0) [0|10] "m"  PC
 SG_ StdDoppler_29 : 43|10@0+ (0.01,0) [0|10] "m/s"  PC
 SG_ NoInfrastructure_29 : 38|1@0+ (1,0) [0|0] "n/a"  PC
 SG_ Infrastructure_29 : 39|1@0+ (1,0) [0|0] "n/a"  PC
 SG_ Detected_beam_number_29 : 7|2@0+ (1,0) [0|0] "n/a"  PC

BO_ 369 MB79_TARGET_DETECTION_28D: 8 SODX
 SG_ Complex4_Re_28 : 39|16@0- (1,0) [-32768|32767] "n/a"  PC
 SG_ Complex4_Im_28 : 55|16@0- (1,0) [-32768|32767] "n/a"  PC
 SG_ Complex3_Re_28 : 7|16@0- (1,0) [-32768|32767] "n/a"  PC
 SG_ Complex3_Im_28 : 23|16@0- (1,0) [-32768|32767] "n/a"  PC

BO_ 368 MB79_TARGET_DETECTION_28C: 8 SODX
 SG_ Complex2_Re_28 : 39|16@0- (1,0) [-32768|32767] "n/a"  PC
 SG_ Complex2_Im_28 : 55|16@0- (1,0) [-32768|32767] "n/a"  PC
 SG_ Complex1_Re_28 : 7|16@0- (1,0) [-32768|32767] "n/a"  PC
 SG_ Complex1_Im_28 : 23|16@0- (1,0) [-32768|32767] "n/a"  PC

BO_ 367 MB79_TARGET_DETECTION_28B: 8 SODX
 SG_ StdAzimuth_28 : 63|8@0+ (0.0009766,0) [0|14.31] "°"  PC
 SG_ PowerDB_28 : 7|8@0+ (1,0) [0|255] "db"  PC
 SG_ CoGRange_28 : 15|16@0- (0.01,0) [0|96] "m"  PC
 SG_ CoGDoppler_28 : 31|16@0- (0.01,0) [-140|14] "m/s"  PC
 SG_ Azimuth_28 : 47|16@0- (0.1,0) [-180|180] "°"  PC

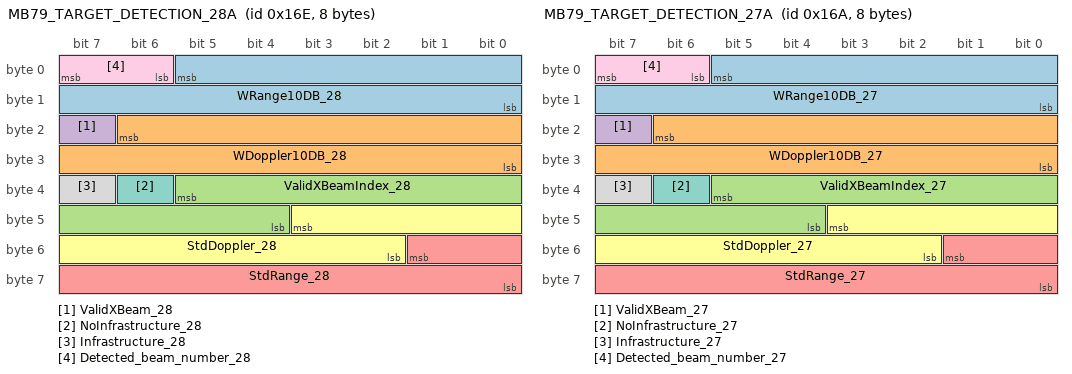
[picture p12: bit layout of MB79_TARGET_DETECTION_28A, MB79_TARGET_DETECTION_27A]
BO_ 366 MB79_TARGET_DETECTION_28A: 8 SODX
 SG_ WRange10DB_28 : 5|14@0+ (0.01,0) [0|96] "m"  PC
 SG_ WDoppler10DB_28 : 22|15@0+ (0.01,0) [0|280] "m/s"  PC
 SG_ ValidXBeamIndex_28 : 37|10@0+ (1,0) [0|0] "n/a"  PC
 SG_ ValidXBeam_28 : 23|1@0+ (1,0) [0|0] "n/a"  PC
 SG_ StdRange_28 : 49|10@0+ (0.01,0) [0|10] "m"  PC
 SG_ StdDoppler_28 : 43|10@0+ (0.01,0) [0|10] "m/s"  PC
 SG_ NoInfrastructure_28 : 38|1@0+ (1,0) [0|0] "n/a"  PC
 SG_ Infrastructure_28 : 39|1@0+ (1,0) [0|0] "n/a"  PC
 SG_ Detected_beam_number_28 : 7|2@0+ (1,0) [0|0] "n/a"  PC

BO_ 365 MB79_TARGET_DETECTION_27D: 8 SODX
 SG_ Complex4_Re_27 : 39|16@0- (1,0) [-32768|32767] "n/a"  PC
 SG_ Complex4_Im_27 : 55|16@0- (1,0) [-32768|32767] "n/a"  PC
 SG_ Complex3_Re_27 : 7|16@0- (1,0) [-32768|32767] "n/a"  PC
 SG_ Complex3_Im_27 : 23|16@0- (1,0) [-32768|32767] "n/a"  PC

BO_ 364 MB79_TARGET_DETECTION_27C: 8 SODX
 SG_ Complex2_Re_27 : 39|16@0- (1,0) [-32768|32767] "n/a"  PC
 SG_ Complex2_Im_27 : 55|16@0- (1,0) [-32768|32767] "n/a"  PC
 SG_ Complex1_Re_27 : 7|16@0- (1,0) [-32768|32767] "n/a"  PC
 SG_ Complex1_Im_27 : 23|16@0- (1,0) [-32768|32767] "n/a"  PC

BO_ 363 MB79_TARGET_DETECTION_27B: 8 SODX
 SG_ StdAzimuth_27 : 63|8@0+ (0.0009766,0) [0|14.31] "°"  PC
 SG_ PowerDB_27 : 7|8@0+ (1,0) [0|255] "db"  PC
 SG_ CoGRange_27 : 15|16@0- (0.01,0) [0|96] "m"  PC
 SG_ CoGDoppler_27 : 31|16@0- (0.01,0) [-140|14] "m/s"  PC
 SG_ Azimuth_27 : 47|16@0- (0.1,0) [-180|180] "°"  PC

BO_ 362 MB79_TARGET_DETECTION_27A: 8 SODX
 SG_ WRange10DB_27 : 5|14@0+ (0.01,0) [0|96] "m"  PC
 SG_ WDoppler10DB_27 : 22|15@0+ (0.01,0) [0|280] "m/s"  PC
 SG_ ValidXBeamIndex_27 : 37|10@0+ (1,0) [0|0] "n/a"  PC
 SG_ ValidXBeam_27 : 23|1@0+ (1,0) [0|0] "n/a"  PC
 SG_ StdRange_27 : 49|10@0+ (0.01,0) [0|10] "m"  PC
 SG_ StdDoppler_27 : 43|10@0+ (0.01,0) [0|10] "m/s"  PC
 SG_ NoInfrastructure_27 : 38|1@0+ (1,0) [0|0] "n/a"  PC
 SG_ Infrastructure_27 : 39|1@0+ (1,0) [0|0] "n/a"  PC
 SG_ Detected_beam_number_27 : 7|2@0+ (1,0) [0|0] "n/a"  PC

BO_ 361 MB79_TARGET_DETECTION_26D: 8 SODX
 SG_ Complex4_Re_26 : 39|16@0- (1,0) [-32768|32767] "n/a"  PC
 SG_ Complex4_Im_26 : 55|16@0- (1,0) [-32768|32767] "n/a"  PC
 SG_ Complex3_Re_26 : 7|16@0- (1,0) [-32768|32767] "n/a"  PC
 SG_ Complex3_Im_26 : 23|16@0- (1,0) [-32768|32767] "n/a"  PC

BO_ 360 MB79_TARGET_DETECTION_26C: 8 SODX
 SG_ Complex2_Re_26 : 39|16@0- (1,0) [-32768|32767] "n/a"  PC
 SG_ Complex2_Im_26 : 55|16@0- (1,0) [-32768|32767] "n/a"  PC
 SG_ Complex1_Re_26 : 7|16@0- (1,0) [-32768|32767] "n/a"  PC
 SG_ Complex1_Im_26 : 23|16@0- (1,0) [-32768|32767] "n/a"  PC

BO_ 359 MB79_TARGET_DETECTION_26B: 8 SODX
 SG_ StdAzimuth_26 : 63|8@0+ (0.0009766,0) [0|14.31] "°"  PC
 SG_ PowerDB_26 : 7|8@0+ (1,0) [0|255] "db"  PC
 SG_ CoGRange_26 : 15|16@0- (0.01,0) [0|96] "m"  PC
 SG_ CoGDoppler_26 : 31|16@0- (0.01,0) [-140|14] "m/s"  PC
 SG_ Azimuth_26 : 47|16@0- (0.1,0) [-180|180] "°"  PC

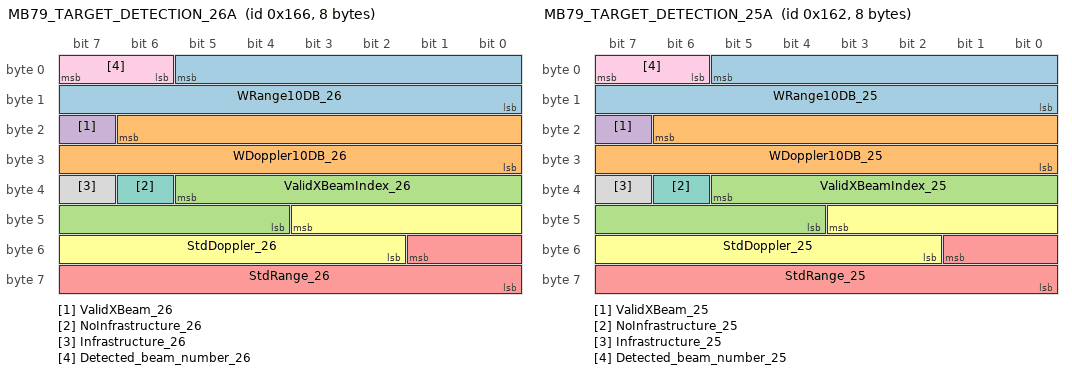
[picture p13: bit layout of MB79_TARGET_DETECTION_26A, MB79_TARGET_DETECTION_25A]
BO_ 358 MB79_TARGET_DETECTION_26A: 8 SODX
 SG_ WRange10DB_26 : 5|14@0+ (0.01,0) [0|96] "m"  PC
 SG_ WDoppler10DB_26 : 22|15@0+ (0.01,0) [0|280] "m/s"  PC
 SG_ ValidXBeamIndex_26 : 37|10@0+ (1,0) [0|0] "n/a"  PC
 SG_ ValidXBeam_26 : 23|1@0+ (1,0) [0|0] "n/a"  PC
 SG_ StdRange_26 : 49|10@0+ (0.01,0) [0|10] "m"  PC
 SG_ StdDoppler_26 : 43|10@0+ (0.01,0) [0|10] "m/s"  PC
 SG_ NoInfrastructure_26 : 38|1@0+ (1,0) [0|0] "n/a"  PC
 SG_ Infrastructure_26 : 39|1@0+ (1,0) [0|0] "n/a"  PC
 SG_ Detected_beam_number_26 : 7|2@0+ (1,0) [0|0] "n/a"  PC

BO_ 357 MB79_TARGET_DETECTION_25D: 8 SODX
 SG_ Complex4_Re_25 : 39|16@0- (1,0) [-32768|32767] "n/a"  PC
 SG_ Complex4_Im_25 : 55|16@0- (1,0) [-32768|32767] "n/a"  PC
 SG_ Complex3_Re_25 : 7|16@0- (1,0) [-32768|32767] "n/a"  PC
 SG_ Complex3_Im_25 : 23|16@0- (1,0) [-32768|32767] "n/a"  PC

BO_ 356 MB79_TARGET_DETECTION_25C: 8 SODX
 SG_ Complex2_Re_25 : 39|16@0- (1,0) [-32768|32767] "n/a"  PC
 SG_ Complex2_Im_25 : 55|16@0- (1,0) [-32768|32767] "n/a"  PC
 SG_ Complex1_Re_25 : 7|16@0- (1,0) [-32768|32767] "n/a"  PC
 SG_ Complex1_Im_25 : 23|16@0- (1,0) [-32768|32767] "n/a"  PC

BO_ 355 MB79_TARGET_DETECTION_25B: 8 SODX
 SG_ StdAzimuth_25 : 63|8@0+ (0.0009766,0) [0|14.31] "°"  PC
 SG_ PowerDB_25 : 7|8@0+ (1,0) [0|255] "db"  PC
 SG_ CoGRange_25 : 15|16@0- (0.01,0) [0|96] "m"  PC
 SG_ CoGDoppler_25 : 31|16@0- (0.01,0) [-140|14] "m/s"  PC
 SG_ Azimuth_25 : 47|16@0- (0.1,0) [-180|180] "°"  PC

BO_ 354 MB79_TARGET_DETECTION_25A: 8 SODX
 SG_ WRange10DB_25 : 5|14@0+ (0.01,0) [0|96] "m"  PC
 SG_ WDoppler10DB_25 : 22|15@0+ (0.01,0) [0|280] "m/s"  PC
 SG_ ValidXBeamIndex_25 : 37|10@0+ (1,0) [0|0] "n/a"  PC
 SG_ ValidXBeam_25 : 23|1@0+ (1,0) [0|0] "n/a"  PC
 SG_ StdRange_25 : 49|10@0+ (0.01,0) [0|10] "m"  PC
 SG_ StdDoppler_25 : 43|10@0+ (0.01,0) [0|10] "m/s"  PC
 SG_ NoInfrastructure_25 : 38|1@0+ (1,0) [0|0] "n/a"  PC
 SG_ Infrastructure_25 : 39|1@0+ (1,0) [0|0] "n/a"  PC
 SG_ Detected_beam_number_25 : 7|2@0+ (1,0) [0|0] "n/a"  PC

BO_ 353 MB79_TARGET_DETECTION_24D: 8 SODX
 SG_ Complex4_Re_24 : 39|16@0- (1,0) [-32768|32767] "n/a"  PC
 SG_ Complex4_Im_24 : 55|16@0- (1,0) [-32768|32767] "n/a"  PC
 SG_ Complex3_Re_24 : 7|16@0- (1,0) [-32768|32767] "n/a"  PC
 SG_ Complex3_Im_24 : 23|16@0- (1,0) [-32768|32767] "n/a"  PC

BO_ 352 MB79_TARGET_DETECTION_24C: 8 SODX
 SG_ Complex2_Re_24 : 39|16@0- (1,0) [-32768|32767] "n/a"  PC
 SG_ Complex2_Im_24 : 55|16@0- (1,0) [-32768|32767] "n/a"  PC
 SG_ Complex1_Re_24 : 7|16@0- (1,0) [-32768|32767] "n/a"  PC
 SG_ Complex1_Im_24 : 23|16@0- (1,0) [-32768|32767] "n/a"  PC

BO_ 351 MB79_TARGET_DETECTION_24B: 8 SODX
 SG_ StdAzimuth_24 : 63|8@0+ (0.0009766,0) [0|14.31] "°"  PC
 SG_ PowerDB_24 : 7|8@0+ (1,0) [0|255] "db"  PC
 SG_ CoGRange_24 : 15|16@0- (0.01,0) [0|96] "m"  PC
 SG_ CoGDoppler_24 : 31|16@0- (0.01,0) [-140|14] "m/s"  PC
 SG_ Azimuth_24 : 47|16@0- (0.1,0) [-180|180] "°"  PC

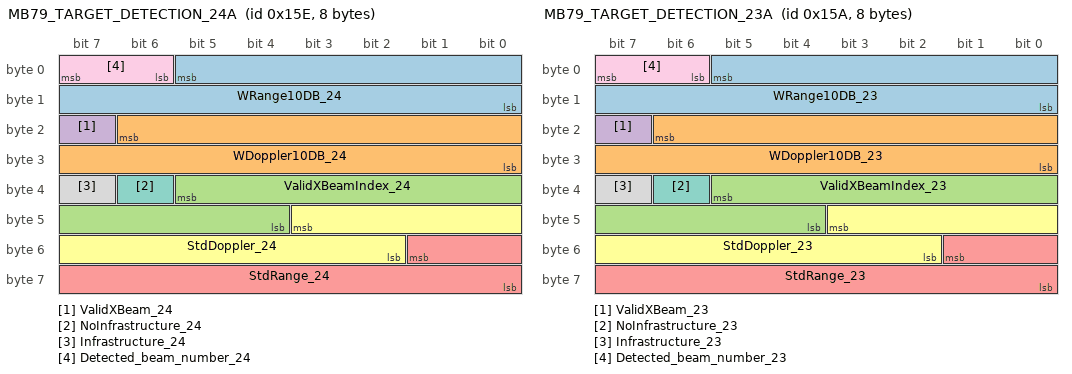
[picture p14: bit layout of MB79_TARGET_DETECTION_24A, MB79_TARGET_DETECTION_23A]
BO_ 350 MB79_TARGET_DETECTION_24A: 8 SODX
 SG_ WRange10DB_24 : 5|14@0+ (0.01,0) [0|96] "m"  PC
 SG_ WDoppler10DB_24 : 22|15@0+ (0.01,0) [0|280] "m/s"  PC
 SG_ ValidXBeamIndex_24 : 37|10@0+ (1,0) [0|0] "n/a"  PC
 SG_ ValidXBeam_24 : 23|1@0+ (1,0) [0|0] "n/a"  PC
 SG_ StdRange_24 : 49|10@0+ (0.01,0) [0|10] "m"  PC
 SG_ StdDoppler_24 : 43|10@0+ (0.01,0) [0|10] "m/s"  PC
 SG_ NoInfrastructure_24 : 38|1@0+ (1,0) [0|0] "n/a"  PC
 SG_ Infrastructure_24 : 39|1@0+ (1,0) [0|0] "n/a"  PC
 SG_ Detected_beam_number_24 : 7|2@0+ (1,0) [0|0] "n/a"  PC

BO_ 349 MB79_TARGET_DETECTION_23D: 8 SODX
 SG_ Complex4_Re_23 : 39|16@0- (1,0) [-32768|32767] "n/a"  PC
 SG_ Complex4_Im_23 : 55|16@0- (1,0) [-32768|32767] "n/a"  PC
 SG_ Complex3_Re_23 : 7|16@0- (1,0) [-32768|32767] "n/a"  PC
 SG_ Complex3_Im_23 : 23|16@0- (1,0) [-32768|32767] "n/a"  PC

BO_ 348 MB79_TARGET_DETECTION_23C: 8 SODX
 SG_ Complex2_Re_23 : 39|16@0- (1,0) [-32768|32767] "n/a"  PC
 SG_ Complex2_Im_23 : 55|16@0- (1,0) [-32768|32767] "n/a"  PC
 SG_ Complex1_Re_23 : 7|16@0- (1,0) [-32768|32767] "n/a"  PC
 SG_ Complex1_Im_23 : 23|16@0- (1,0) [-32768|32767] "n/a"  PC

BO_ 347 MB79_TARGET_DETECTION_23B: 8 SODX
 SG_ StdAzimuth_23 : 63|8@0+ (0.0009766,0) [0|14.31] "°"  PC
 SG_ PowerDB_23 : 7|8@0+ (1,0) [0|255] "db"  PC
 SG_ CoGRange_23 : 15|16@0- (0.01,0) [0|96] "m"  PC
 SG_ CoGDoppler_23 : 31|16@0- (0.01,0) [-140|14] "m/s"  PC
 SG_ Azimuth_23 : 47|16@0- (0.1,0) [-180|180] "°"  PC

BO_ 346 MB79_TARGET_DETECTION_23A: 8 SODX
 SG_ WRange10DB_23 : 5|14@0+ (0.01,0) [0|96] "m"  PC
 SG_ WDoppler10DB_23 : 22|15@0+ (0.01,0) [0|280] "m/s"  PC
 SG_ ValidXBeamIndex_23 : 37|10@0+ (1,0) [0|0] "n/a"  PC
 SG_ ValidXBeam_23 : 23|1@0+ (1,0) [0|0] "n/a"  PC
 SG_ StdRange_23 : 49|10@0+ (0.01,0) [0|10] "m"  PC
 SG_ StdDoppler_23 : 43|10@0+ (0.01,0) [0|10] "m/s"  PC
 SG_ NoInfrastructure_23 : 38|1@0+ (1,0) [0|0] "n/a"  PC
 SG_ Infrastructure_23 : 39|1@0+ (1,0) [0|0] "n/a"  PC
 SG_ Detected_beam_number_23 : 7|2@0+ (1,0) [0|0] "n/a"  PC

BO_ 345 MB79_TARGET_DETECTION_22D: 8 SODX
 SG_ Complex4_Re_22 : 39|16@0- (1,0) [-32768|32767] "n/a"  PC
 SG_ Complex4_Im_22 : 55|16@0- (1,0) [-32768|32767] "n/a"  PC
 SG_ Complex3_Re_22 : 7|16@0- (1,0) [-32768|32767] "n/a"  PC
 SG_ Complex3_Im_22 : 23|16@0- (1,0) [-32768|32767] "n/a"  PC

BO_ 344 MB79_TARGET_DETECTION_22C: 8 SODX
 SG_ Complex2_Re_22 : 39|16@0- (1,0) [-32768|32767] "n/a"  PC
 SG_ Complex2_Im_22 : 55|16@0- (1,0) [-32768|32767] "n/a"  PC
 SG_ Complex1_Re_22 : 7|16@0- (1,0) [-32768|32767] "n/a"  PC
 SG_ Complex1_Im_22 : 23|16@0- (1,0) [-32768|32767] "n/a"  PC

BO_ 343 MB79_TARGET_DETECTION_22B: 8 SODX
 SG_ StdAzimuth_22 : 63|8@0+ (0.0009766,0) [0|14.31] "°"  PC
 SG_ PowerDB_22 : 7|8@0+ (1,0) [0|255] "db"  PC
 SG_ CoGRange_22 : 15|16@0- (0.01,0) [0|96] "m"  PC
 SG_ CoGDoppler_22 : 31|16@0- (0.01,0) [-140|14] "m/s"  PC
 SG_ Azimuth_22 : 47|16@0- (0.1,0) [-180|180] "°"  PC

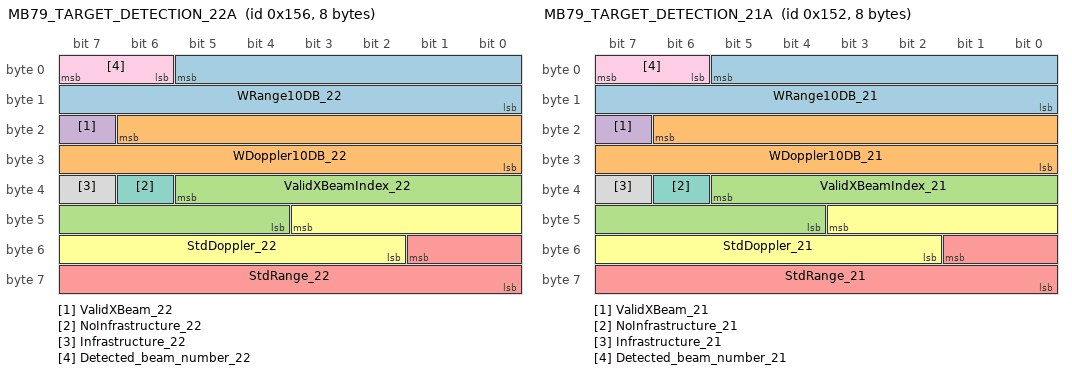
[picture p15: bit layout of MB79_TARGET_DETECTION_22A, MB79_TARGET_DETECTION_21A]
BO_ 342 MB79_TARGET_DETECTION_22A: 8 SODX
 SG_ WRange10DB_22 : 5|14@0+ (0.01,0) [0|96] "m"  PC
 SG_ WDoppler10DB_22 : 22|15@0+ (0.01,0) [0|280] "m/s"  PC
 SG_ ValidXBeamIndex_22 : 37|10@0+ (1,0) [0|0] "n/a"  PC
 SG_ ValidXBeam_22 : 23|1@0+ (1,0) [0|0] "n/a"  PC
 SG_ StdRange_22 : 49|10@0+ (0.01,0) [0|10] "m"  PC
 SG_ StdDoppler_22 : 43|10@0+ (0.01,0) [0|10] "m/s"  PC
 SG_ NoInfrastructure_22 : 38|1@0+ (1,0) [0|0] "n/a"  PC
 SG_ Infrastructure_22 : 39|1@0+ (1,0) [0|0] "n/a"  PC
 SG_ Detected_beam_number_22 : 7|2@0+ (1,0) [0|0] "n/a"  PC

BO_ 341 MB79_TARGET_DETECTION_21D: 8 SODX
 SG_ Complex4_Re_21 : 39|16@0- (1,0) [-32768|32767] "n/a"  PC
 SG_ Complex4_Im_21 : 55|16@0- (1,0) [-32768|32767] "n/a"  PC
 SG_ Complex3_Re_21 : 7|16@0- (1,0) [-32768|32767] "n/a"  PC
 SG_ Complex3_Im_21 : 23|16@0- (1,0) [-32768|32767] "n/a"  PC

BO_ 340 MB79_TARGET_DETECTION_21C: 8 SODX
 SG_ Complex2_Re_21 : 39|16@0- (1,0) [-32768|32767] "n/a"  PC
 SG_ Complex2_Im_21 : 55|16@0- (1,0) [-32768|32767] "n/a"  PC
 SG_ Complex1_Re_21 : 7|16@0- (1,0) [-32768|32767] "n/a"  PC
 SG_ Complex1_Im_21 : 23|16@0- (1,0) [-32768|32767] "n/a"  PC

BO_ 339 MB79_TARGET_DETECTION_21B: 8 SODX
 SG_ StdAzimuth_21 : 63|8@0+ (0.0009766,0) [0|14.31] "°"  PC
 SG_ PowerDB_21 : 7|8@0+ (1,0) [0|255] "db"  PC
 SG_ CoGRange_21 : 15|16@0- (0.01,0) [0|96] "m"  PC
 SG_ CoGDoppler_21 : 31|16@0- (0.01,0) [-140|14] "m/s"  PC
 SG_ Azimuth_21 : 47|16@0- (0.1,0) [-180|180] "°"  PC

BO_ 338 MB79_TARGET_DETECTION_21A: 8 SODX
 SG_ WRange10DB_21 : 5|14@0+ (0.01,0) [0|96] "m"  PC
 SG_ WDoppler10DB_21 : 22|15@0+ (0.01,0) [0|280] "m/s"  PC
 SG_ ValidXBeamIndex_21 : 37|10@0+ (1,0) [0|0] "n/a"  PC
 SG_ ValidXBeam_21 : 23|1@0+ (1,0) [0|0] "n/a"  PC
 SG_ StdRange_21 : 49|10@0+ (0.01,0) [0|10] "m"  PC
 SG_ StdDoppler_21 : 43|10@0+ (0.01,0) [0|10] "m/s"  PC
 SG_ NoInfrastructure_21 : 38|1@0+ (1,0) [0|0] "n/a"  PC
 SG_ Infrastructure_21 : 39|1@0+ (1,0) [0|0] "n/a"  PC
 SG_ Detected_beam_number_21 : 7|2@0+ (1,0) [0|0] "n/a"  PC

BO_ 337 MB79_TARGET_DETECTION_20D: 8 SODX
 SG_ Complex4_Re_20 : 39|16@0- (1,0) [-32768|32767] "n/a"  PC
 SG_ Complex4_Im_20 : 55|16@0- (1,0) [-32768|32767] "n/a"  PC
 SG_ Complex3_Re_20 : 7|16@0- (1,0) [-32768|32767] "n/a"  PC
 SG_ Complex3_Im_20 : 23|16@0- (1,0) [-32768|32767] "n/a"  PC

BO_ 336 MB79_TARGET_DETECTION_20C: 8 SODX
 SG_ Complex2_Re_20 : 39|16@0- (1,0) [-32768|32767] "n/a"  PC
 SG_ Complex2_Im_20 : 55|16@0- (1,0) [-32768|32767] "n/a"  PC
 SG_ Complex1_Re_20 : 7|16@0- (1,0) [-32768|32767] "n/a"  PC
 SG_ Complex1_Im_20 : 23|16@0- (1,0) [-32768|32767] "n/a"  PC

BO_ 335 MB79_TARGET_DETECTION_20B: 8 SODX
 SG_ StdAzimuth_20 : 63|8@0+ (0.0009766,0) [0|14.31] "°"  PC
 SG_ PowerDB_20 : 7|8@0+ (1,0) [0|255] "db"  PC
 SG_ CoGRange_20 : 15|16@0- (0.01,0) [0|96] "m"  PC
 SG_ CoGDoppler_20 : 31|16@0- (0.01,0) [-140|14] "m/s"  PC
 SG_ Azimuth_20 : 47|16@0- (0.1,0) [-180|180] "°"  PC

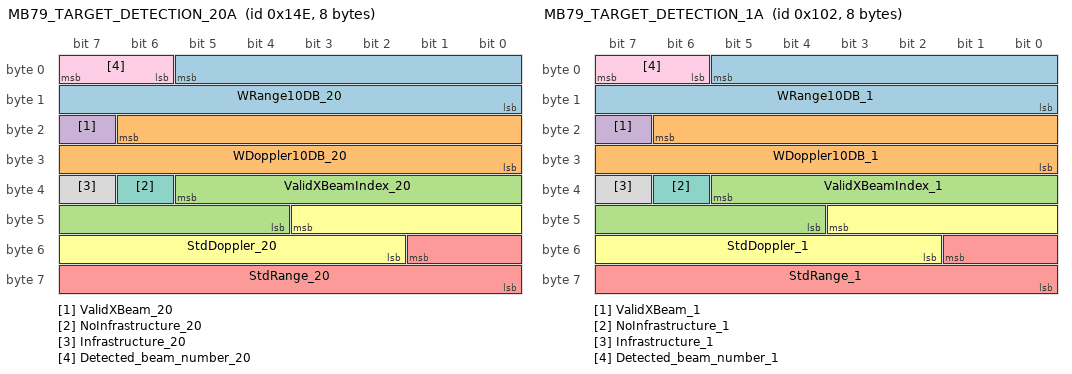
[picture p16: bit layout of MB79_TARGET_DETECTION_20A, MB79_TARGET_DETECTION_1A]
BO_ 334 MB79_TARGET_DETECTION_20A: 8 SODX
 SG_ WRange10DB_20 : 5|14@0+ (0.01,0) [0|96] "m"  PC
 SG_ WDoppler10DB_20 : 22|15@0+ (0.01,0) [0|280] "m/s"  PC
 SG_ ValidXBeamIndex_20 : 37|10@0+ (1,0) [0|0] "n/a"  PC
 SG_ ValidXBeam_20 : 23|1@0+ (1,0) [0|0] "n/a"  PC
 SG_ StdRange_20 : 49|10@0+ (0.01,0) [0|10] "m"  PC
 SG_ StdDoppler_20 : 43|10@0+ (0.01,0) [0|10] "m/s"  PC
 SG_ NoInfrastructure_20 : 38|1@0+ (1,0) [0|0] "n/a"  PC
 SG_ Infrastructure_20 : 39|1@0+ (1,0) [0|0] "n/a"  PC
 SG_ Detected_beam_number_20 : 7|2@0+ (1,0) [0|0] "n/a"  PC

BO_ 261 MB79_TARGET_DETECTION_1D: 8 SODX
 SG_ Complex4_Re_1 : 39|16@0- (1,0) [-32768|32767] "n/a"  PC
 SG_ Complex4_Im_1 : 55|16@0- (1,0) [-32768|32767] "n/a"  PC
 SG_ Complex3_Re_1 : 7|16@0- (1,0) [-32768|32767] "n/a"  PC
 SG_ Complex3_Im_1 : 23|16@0- (1,0) [-32768|32767] "n/a"  PC

BO_ 260 MB79_TARGET_DETECTION_1C: 8 SODX
 SG_ Complex2_Re_1 : 39|16@0- (1,0) [-32768|32767] "n/a"  PC
 SG_ Complex2_Im_1 : 55|16@0- (1,0) [-32768|32767] "n/a"  PC
 SG_ Complex1_Re_1 : 7|16@0- (1,0) [-32768|32767] "n/a"  PC
 SG_ Complex1_Im_1 : 23|16@0- (1,0) [-32768|32767] "n/a"  PC

BO_ 259 MB79_TARGET_DETECTION_1B: 8 SODX
 SG_ StdAzimuth_1 : 63|8@0+ (0.0009766,0) [0|14.31] "°"  PC
 SG_ PowerDB_1 : 7|8@0+ (1,0) [0|255] "db"  PC
 SG_ CoGRange_1 : 15|16@0- (0.01,0) [0|96] "m"  PC
 SG_ CoGDoppler_1 : 31|16@0- (0.01,0) [-140|14] "m/s"  PC
 SG_ Azimuth_1 : 47|16@0- (0.1,0) [-180|180] "°"  PC

BO_ 258 MB79_TARGET_DETECTION_1A: 8 SODX
 SG_ WRange10DB_1 : 5|14@0+ (0.01,0) [0|96] "m"  PC
 SG_ WDoppler10DB_1 : 22|15@0+ (0.01,0) [0|280] "m/s"  PC
 SG_ ValidXBeamIndex_1 : 37|10@0+ (1,0) [0|0] "n/a"  PC
 SG_ ValidXBeam_1 : 23|1@0+ (1,0) [0|0] "n/a"  PC
 SG_ StdRange_1 : 49|10@0+ (0.01,0) [0|10] "m"  PC
 SG_ StdDoppler_1 : 43|10@0+ (0.01,0) [0|10] "m/s"  PC
 SG_ NoInfrastructure_1 : 38|1@0+ (1,0) [0|0] "n/a"  PC
 SG_ Infrastructure_1 : 39|1@0+ (1,0) [0|0] "n/a"  PC
 SG_ Detected_beam_number_1 : 7|2@0+ (1,0) [0|0] "n/a"  PC

BO_ 333 MB79_TARGET_DETECTION_19D: 8 SODX
 SG_ Complex4_Re_19 : 39|16@0- (1,0) [-32768|32767] "n/a"  PC
 SG_ Complex4_Im_19 : 55|16@0- (1,0) [-32768|32767] "n/a"  PC
 SG_ Complex3_Re_19 : 7|16@0- (1,0) [-32768|32767] "n/a"  PC
 SG_ Complex3_Im_19 : 23|16@0- (1,0) [-32768|32767] "n/a"  PC

BO_ 332 MB79_TARGET_DETECTION_19C: 8 SODX
 SG_ Complex2_Re_19 : 39|16@0- (1,0) [-32768|32767] "n/a"  PC
 SG_ Complex2_Im_19 : 55|16@0- (1,0) [-32768|32767] "n/a"  PC
 SG_ Complex1_Re_19 : 7|16@0- (1,0) [-32768|32767] "n/a"  PC
 SG_ Complex1_Im_19 : 23|16@0- (1,0) [-32768|32767] "n/a"  PC

BO_ 331 MB79_TARGET_DETECTION_19B: 8 SODX
 SG_ StdAzimuth_19 : 63|8@0+ (0.0009766,0) [0|14.31] "°"  PC
 SG_ PowerDB_19 : 7|8@0+ (1,0) [0|255] "db"  PC
 SG_ CoGRange_19 : 15|16@0- (0.01,0) [0|96] "m"  PC
 SG_ CoGDoppler_19 : 31|16@0- (0.01,0) [-140|14] "m/s"  PC
 SG_ Azimuth_19 : 47|16@0- (0.1,0) [-180|180] "°"  PC

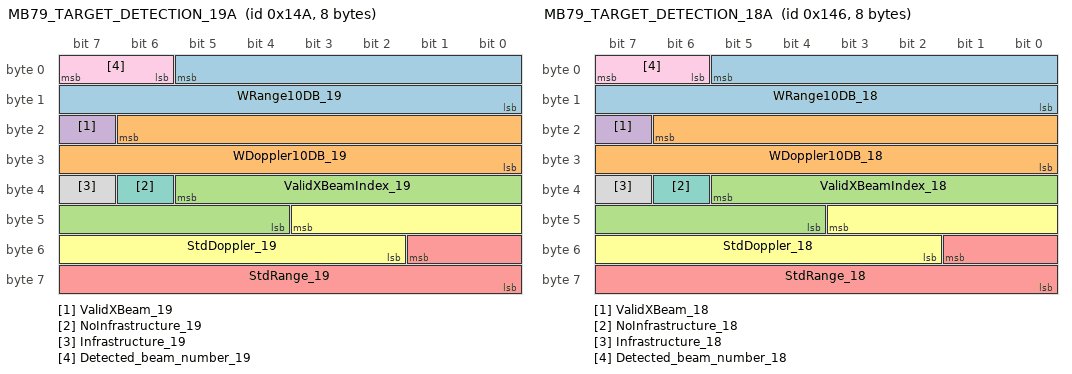
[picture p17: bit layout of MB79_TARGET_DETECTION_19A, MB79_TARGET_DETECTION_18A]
BO_ 330 MB79_TARGET_DETECTION_19A: 8 SODX
 SG_ WRange10DB_19 : 5|14@0+ (0.01,0) [0|96] "m"  PC
 SG_ WDoppler10DB_19 : 22|15@0+ (0.01,0) [0|280] "m/s"  PC
 SG_ ValidXBeamIndex_19 : 37|10@0+ (1,0) [0|0] "n/a"  PC
 SG_ ValidXBeam_19 : 23|1@0+ (1,0) [0|0] "n/a"  PC
 SG_ StdRange_19 : 49|10@0+ (0.01,0) [0|10] "m"  PC
 SG_ StdDoppler_19 : 43|10@0+ (0.01,0) [0|10] "m/s"  PC
 SG_ NoInfrastructure_19 : 38|1@0+ (1,0) [0|0] "n/a"  PC
 SG_ Infrastructure_19 : 39|1@0+ (1,0) [0|0] "n/a"  PC
 SG_ Detected_beam_number_19 : 7|2@0+ (1,0) [0|0] "n/a"  PC

BO_ 329 MB79_TARGET_DETECTION_18D: 8 SODX
 SG_ Complex4_Re_18 : 39|16@0- (1,0) [-32768|32767] "n/a"  PC
 SG_ Complex4_Im_18 : 55|16@0- (1,0) [-32768|32767] "n/a"  PC
 SG_ Complex3_Re_18 : 7|16@0- (1,0) [-32768|32767] "n/a"  PC
 SG_ Complex3_Im_18 : 23|16@0- (1,0) [-32768|32767] "n/a"  PC

BO_ 328 MB79_TARGET_DETECTION_18C: 8 SODX
 SG_ Complex2_Re_18 : 39|16@0- (1,0) [-32768|32767] "n/a"  PC
 SG_ Complex2_Im_18 : 55|16@0- (1,0) [-32768|32767] "n/a"  PC
 SG_ Complex1_Re_18 : 7|16@0- (1,0) [-32768|32767] "n/a"  PC
 SG_ Complex1_Im_18 : 23|16@0- (1,0) [-32768|32767] "n/a"  PC

BO_ 327 MB79_TARGET_DETECTION_18B: 8 SODX
 SG_ StdAzimuth_18 : 63|8@0+ (0.0009766,0) [0|14.31] "°"  PC
 SG_ PowerDB_18 : 7|8@0+ (1,0) [0|255] "db"  PC
 SG_ CoGRange_18 : 15|16@0- (0.01,0) [0|96] "m"  PC
 SG_ CoGDoppler_18 : 31|16@0- (0.01,0) [-140|14] "m/s"  PC
 SG_ Azimuth_18 : 47|16@0- (0.1,0) [-180|180] "°"  PC

BO_ 326 MB79_TARGET_DETECTION_18A: 8 SODX
 SG_ WRange10DB_18 : 5|14@0+ (0.01,0) [0|96] "m"  PC
 SG_ WDoppler10DB_18 : 22|15@0+ (0.01,0) [0|280] "m/s"  PC
 SG_ ValidXBeamIndex_18 : 37|10@0+ (1,0) [0|0] "n/a"  PC
 SG_ ValidXBeam_18 : 23|1@0+ (1,0) [0|0] "n/a"  PC
 SG_ StdRange_18 : 49|10@0+ (0.01,0) [0|10] "m"  PC
 SG_ StdDoppler_18 : 43|10@0+ (0.01,0) [0|10] "m/s"  PC
 SG_ NoInfrastructure_18 : 38|1@0+ (1,0) [0|0] "n/a"  PC
 SG_ Infrastructure_18 : 39|1@0+ (1,0) [0|0] "n/a"  PC
 SG_ Detected_beam_number_18 : 7|2@0+ (1,0) [0|0] "n/a"  PC

BO_ 325 MB79_TARGET_DETECTION_17D: 8 SODX
 SG_ Complex4_Re_17 : 39|16@0- (1,0) [-32768|32767] "n/a"  PC
 SG_ Complex4_Im_17 : 55|16@0- (1,0) [-32768|32767] "n/a"  PC
 SG_ Complex3_Re_17 : 7|16@0- (1,0) [-32768|32767] "n/a"  PC
 SG_ Complex3_Im_17 : 23|16@0- (1,0) [-32768|32767] "n/a"  PC

BO_ 324 MB79_TARGET_DETECTION_17C: 8 SODX
 SG_ Complex2_Re_17 : 39|16@0- (1,0) [-32768|32767] "n/a"  PC
 SG_ Complex2_Im_17 : 55|16@0- (1,0) [-32768|32767] "n/a"  PC
 SG_ Complex1_Re_17 : 7|16@0- (1,0) [-32768|32767] "n/a"  PC
 SG_ Complex1_Im_17 : 23|16@0- (1,0) [-32768|32767] "n/a"  PC

BO_ 323 MB79_TARGET_DETECTION_17B: 8 SODX
 SG_ StdAzimuth_17 : 63|8@0+ (0.0009766,0) [0|14.31] "°"  PC
 SG_ PowerDB_17 : 7|8@0+ (1,0) [0|255] "db"  PC
 SG_ CoGRange_17 : 15|16@0- (0.01,0) [0|96] "m"  PC
 SG_ CoGDoppler_17 : 31|16@0- (0.01,0) [-140|14] "m/s"  PC
 SG_ Azimuth_17 : 47|16@0- (0.1,0) [-180|180] "°"  PC

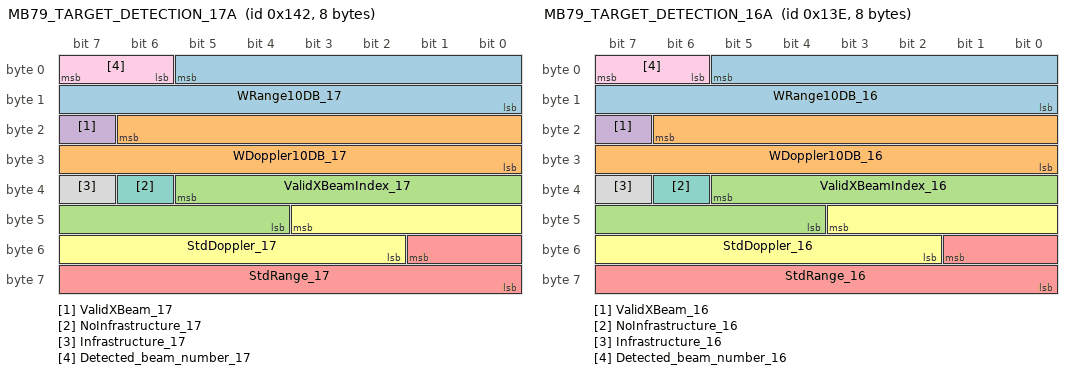
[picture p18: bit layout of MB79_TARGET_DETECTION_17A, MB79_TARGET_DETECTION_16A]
BO_ 322 MB79_TARGET_DETECTION_17A: 8 SODX
 SG_ WRange10DB_17 : 5|14@0+ (0.01,0) [0|96] "m"  PC
 SG_ WDoppler10DB_17 : 22|15@0+ (0.01,0) [0|280] "m/s"  PC
 SG_ ValidXBeamIndex_17 : 37|10@0+ (1,0) [0|0] "n/a"  PC
 SG_ ValidXBeam_17 : 23|1@0+ (1,0) [0|0] "n/a"  PC
 SG_ StdRange_17 : 49|10@0+ (0.01,0) [0|10] "m"  PC
 SG_ StdDoppler_17 : 43|10@0+ (0.01,0) [0|10] "m/s"  PC
 SG_ NoInfrastructure_17 : 38|1@0+ (1,0) [0|0] "n/a"  PC
 SG_ Infrastructure_17 : 39|1@0+ (1,0) [0|0] "n/a"  PC
 SG_ Detected_beam_number_17 : 7|2@0+ (1,0) [0|0] "n/a"  PC

BO_ 321 MB79_TARGET_DETECTION_16D: 8 SODX
 SG_ Complex4_Re_16 : 39|16@0- (1,0) [-32768|32767] "n/a"  PC
 SG_ Complex4_Im_16 : 55|16@0- (1,0) [-32768|32767] "n/a"  PC
 SG_ Complex3_Re_16 : 7|16@0- (1,0) [-32768|32767] "n/a"  PC
 SG_ Complex3_Im_16 : 23|16@0- (1,0) [-32768|32767] "n/a"  PC

BO_ 320 MB79_TARGET_DETECTION_16C: 8 SODX
 SG_ Complex2_Re_16 : 39|16@0- (1,0) [-32768|32767] "n/a"  PC
 SG_ Complex2_Im_16 : 55|16@0- (1,0) [-32768|32767] "n/a"  PC
 SG_ Complex1_Re_16 : 7|16@0- (1,0) [-32768|32767] "n/a"  PC
 SG_ Complex1_Im_16 : 23|16@0- (1,0) [-32768|32767] "n/a"  PC

BO_ 319 MB79_TARGET_DETECTION_16B: 8 SODX
 SG_ StdAzimuth_16 : 63|8@0+ (0.0009766,0) [0|14.31] "°"  PC
 SG_ PowerDB_16 : 7|8@0+ (1,0) [0|255] "db"  PC
 SG_ CoGRange_16 : 15|16@0- (0.01,0) [0|96] "m"  PC
 SG_ CoGDoppler_16 : 31|16@0- (0.01,0) [-140|14] "m/s"  PC
 SG_ Azimuth_16 : 47|16@0- (0.1,0) [-180|180] "°"  PC

BO_ 318 MB79_TARGET_DETECTION_16A: 8 SODX
 SG_ WRange10DB_16 : 5|14@0+ (0.01,0) [0|96] "m"  PC
 SG_ WDoppler10DB_16 : 22|15@0+ (0.01,0) [0|280] "m/s"  PC
 SG_ ValidXBeamIndex_16 : 37|10@0+ (1,0) [0|0] "n/a"  PC
 SG_ ValidXBeam_16 : 23|1@0+ (1,0) [0|0] "n/a"  PC
 SG_ StdRange_16 : 49|10@0+ (0.01,0) [0|10] "m"  PC
 SG_ StdDoppler_16 : 43|10@0+ (0.01,0) [0|10] "m/s"  PC
 SG_ NoInfrastructure_16 : 38|1@0+ (1,0) [0|0] "n/a"  PC
 SG_ Infrastructure_16 : 39|1@0+ (1,0) [0|0] "n/a"  PC
 SG_ Detected_beam_number_16 : 7|2@0+ (1,0) [0|0] "n/a"  PC

BO_ 317 MB79_TARGET_DETECTION_15D: 8 SODX
 SG_ Complex4_Re_15 : 39|16@0- (1,0) [-32768|32767] "n/a"  PC
 SG_ Complex4_Im_15 : 55|16@0- (1,0) [-32768|32767] "n/a"  PC
 SG_ Complex3_Re_15 : 7|16@0- (1,0) [-32768|32767] "n/a"  PC
 SG_ Complex3_Im_15 : 23|16@0- (1,0) [-32768|32767] "n/a"  PC

BO_ 316 MB79_TARGET_DETECTION_15C: 8 SODX
 SG_ Complex2_Re_15 : 39|16@0- (1,0) [-32768|32767] "n/a"  PC
 SG_ Complex2_Im_15 : 55|16@0- (1,0) [-32768|32767] "n/a"  PC
 SG_ Complex1_Re_15 : 7|16@0- (1,0) [-32768|32767] "n/a"  PC
 SG_ Complex1_Im_15 : 23|16@0- (1,0) [-32768|32767] "n/a"  PC

BO_ 315 MB79_TARGET_DETECTION_15B: 8 SODX
 SG_ StdAzimuth_15 : 63|8@0+ (0.0009766,0) [0|14.31] "°"  PC
 SG_ PowerDB_15 : 7|8@0+ (1,0) [0|255] "db"  PC
 SG_ CoGRange_15 : 15|16@0- (0.01,0) [0|96] "m"  PC
 SG_ CoGDoppler_15 : 31|16@0- (0.01,0) [-140|14] "m/s"  PC
 SG_ Azimuth_15 : 47|16@0- (0.1,0) [-180|180] "°"  PC

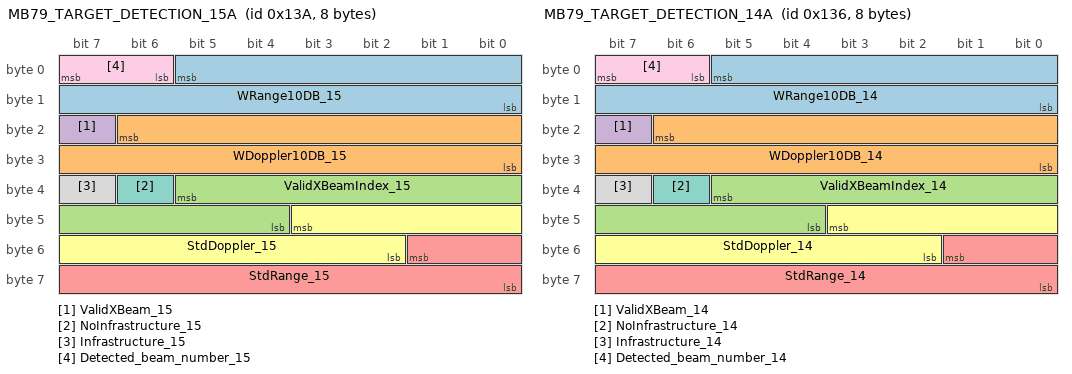
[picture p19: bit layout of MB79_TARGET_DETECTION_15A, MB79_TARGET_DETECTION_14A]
BO_ 314 MB79_TARGET_DETECTION_15A: 8 SODX
 SG_ WRange10DB_15 : 5|14@0+ (0.01,0) [0|96] "m"  PC
 SG_ WDoppler10DB_15 : 22|15@0+ (0.01,0) [0|280] "m/s"  PC
 SG_ ValidXBeamIndex_15 : 37|10@0+ (1,0) [0|0] "n/a"  PC
 SG_ ValidXBeam_15 : 23|1@0+ (1,0) [0|0] "n/a"  PC
 SG_ StdRange_15 : 49|10@0+ (0.01,0) [0|10] "m"  PC
 SG_ StdDoppler_15 : 43|10@0+ (0.01,0) [0|10] "m/s"  PC
 SG_ NoInfrastructure_15 : 38|1@0+ (1,0) [0|0] "n/a"  PC
 SG_ Infrastructure_15 : 39|1@0+ (1,0) [0|0] "n/a"  PC
 SG_ Detected_beam_number_15 : 7|2@0+ (1,0) [0|0] "n/a"  PC

BO_ 313 MB79_TARGET_DETECTION_14D: 8 SODX
 SG_ Complex4_Re_14 : 39|16@0- (1,0) [-32768|32767] "n/a"  PC
 SG_ Complex4_Im_14 : 55|16@0- (1,0) [-32768|32767] "n/a"  PC
 SG_ Complex3_Re_14 : 7|16@0- (1,0) [-32768|32767] "n/a"  PC
 SG_ Complex3_Im_14 : 23|16@0- (1,0) [-32768|32767] "n/a"  PC

BO_ 312 MB79_TARGET_DETECTION_14C: 8 SODX
 SG_ Complex2_Re_14 : 39|16@0- (1,0) [-32768|32767] "n/a"  PC
 SG_ Complex2_Im_14 : 55|16@0- (1,0) [-32768|32767] "n/a"  PC
 SG_ Complex1_Re_14 : 7|16@0- (1,0) [-32768|32767] "n/a"  PC
 SG_ Complex1_Im_14 : 23|16@0- (1,0) [-32768|32767] "n/a"  PC

BO_ 311 MB79_TARGET_DETECTION_14B: 8 SODX
 SG_ StdAzimuth_14 : 63|8@0+ (0.0009766,0) [0|14.31] "°"  PC
 SG_ PowerDB_14 : 7|8@0+ (1,0) [0|255] "db"  PC
 SG_ CoGRange_14 : 15|16@0- (0.01,0) [0|96] "m"  PC
 SG_ CoGDoppler_14 : 31|16@0- (0.01,0) [-140|14] "m/s"  PC
 SG_ Azimuth_14 : 47|16@0- (0.1,0) [-180|180] "°"  PC

BO_ 310 MB79_TARGET_DETECTION_14A: 8 SODX
 SG_ WRange10DB_14 : 5|14@0+ (0.01,0) [0|96] "m"  PC
 SG_ WDoppler10DB_14 : 22|15@0+ (0.01,0) [0|280] "m/s"  PC
 SG_ ValidXBeamIndex_14 : 37|10@0+ (1,0) [0|0] "n/a"  PC
 SG_ ValidXBeam_14 : 23|1@0+ (1,0) [0|0] "n/a"  PC
 SG_ StdRange_14 : 49|10@0+ (0.01,0) [0|10] "m"  PC
 SG_ StdDoppler_14 : 43|10@0+ (0.01,0) [0|10] "m/s"  PC
 SG_ NoInfrastructure_14 : 38|1@0+ (1,0) [0|0] "n/a"  PC
 SG_ Infrastructure_14 : 39|1@0+ (1,0) [0|0] "n/a"  PC
 SG_ Detected_beam_number_14 : 7|2@0+ (1,0) [0|0] "n/a"  PC

BO_ 309 MB79_TARGET_DETECTION_13D: 8 SODX
 SG_ Complex4_Re_13 : 39|16@0- (1,0) [-32768|32767] "n/a"  PC
 SG_ Complex4_Im_13 : 55|16@0- (1,0) [-32768|32767] "n/a"  PC
 SG_ Complex3_Re_13 : 7|16@0- (1,0) [-32768|32767] "n/a"  PC
 SG_ Complex3_Im_13 : 23|16@0- (1,0) [-32768|32767] "n/a"  PC

BO_ 308 MB79_TARGET_DETECTION_13C: 8 SODX
 SG_ Complex2_Re_13 : 39|16@0- (1,0) [-32768|32767] "n/a"  PC
 SG_ Complex2_Im_13 : 55|16@0- (1,0) [-32768|32767] "n/a"  PC
 SG_ Complex1_Re_13 : 7|16@0- (1,0) [-32768|32767] "n/a"  PC
 SG_ Complex1_Im_13 : 23|16@0- (1,0) [-32768|32767] "n/a"  PC

BO_ 307 MB79_TARGET_DETECTION_13B: 8 SODX
 SG_ StdAzimuth_13 : 63|8@0+ (0.0009766,0) [0|14.31] "°"  PC
 SG_ PowerDB_13 : 7|8@0+ (1,0) [0|255] "db"  PC
 SG_ CoGRange_13 : 15|16@0- (0.01,0) [0|96] "m"  PC
 SG_ CoGDoppler_13 : 31|16@0- (0.01,0) [-140|14] "m/s"  PC
 SG_ Azimuth_13 : 47|16@0- (0.1,0) [-180|180] "°"  PC

BO_ 306 MB79_TARGET_DETECTION_13A: 8 SODX
 SG_ WRange10DB_13 : 5|14@0+ (0.01,0) [0|96] "m"  PC
 SG_ WDoppler10DB_13 : 22|15@0+ (0.01,0) [0|280] "m/s"  PC
 SG_ ValidXBeamIndex_13 : 37|10@0+ (1,0) [0|0] "n/a"  PC
 SG_ ValidXBeam_13 : 23|1@0+ (1,0) [0|0] "n/a"  PC
 SG_ StdRange_13 : 49|10@0+ (0.01,0) [0|10] "m"  PC
 SG_ StdDoppler_13 : 43|10@0+ (0.01,0) [0|10] "m/s"  PC
 SG_ NoInfrastructure_13 : 38|1@0+ (1,0) [0|0] "n/a"  PC
 SG_ Infrastructure_13 : 39|1@0+ (1,0) [0|0] "n/a"  PC
 SG_ Detected_beam_number_13 : 7|2@0+ (1,0) [0|0] "n/a"  PC

BO_ 305 MB79_TARGET_DETECTION_12D: 8 SODX
 SG_ Complex4_Re_12 : 39|16@0- (1,0) [-32768|32767] "n/a"  PC
 SG_ Complex4_Im_12 : 55|16@0- (1,0) [-32768|32767] "n/a"  PC
 SG_ Complex3_Re_12 : 7|16@0- (1,0) [-32768|32767] "n/a"  PC
 SG_ Complex3_Im_12 : 23|16@0- (1,0) [-32768|32767] "n/a"  PC

BO_ 304 MB79_TARGET_DETECTION_12C: 8 SODX
 SG_ Complex2_Re_12 : 39|16@0- (1,0) [-32768|32767] "n/a"  PC
 SG_ Complex2_Im_12 : 55|16@0- (1,0) [-32768|32767] "n/a"  PC
 SG_ Complex1_Re_12 : 7|16@0- (1,0) [-32768|32767] "n/a"  PC
 SG_ Complex1_Im_12 : 23|16@0- (1,0) [-32768|32767] "n/a"  PC

BO_ 303 MB79_TARGET_DETECTION_12B: 8 SODX
 SG_ StdAzimuth_12 : 63|8@0+ (0.0009766,0) [0|14.31] "°"  PC
 SG_ PowerDB_12 : 7|8@0+ (1,0) [0|255] "db"  PC
 SG_ CoGRange_12 : 15|16@0- (0.01,0) [0|96] "m"  PC
 SG_ CoGDoppler_12 : 31|16@0- (0.01,0) [-140|14] "m/s"  PC
 SG_ Azimuth_12 : 47|16@0- (0.1,0) [-180|180] "°"  PC

BO_ 302 MB79_TARGET_DETECTION_12A: 8 SODX
 SG_ WRange10DB_12 : 5|14@0+ (0.01,0) [0|96] "m"  PC
 SG_ WDoppler10DB_12 : 22|15@0+ (0.01,0) [0|280] "m/s"  PC
 SG_ ValidXBeamIndex_12 : 37|10@0+ (1,0) [0|0] "n/a"  PC
 SG_ ValidXBeam_12 : 23|1@0+ (1,0) [0|0] "n/a"  PC
 SG_ StdRange_12 : 49|10@0+ (0.01,0) [0|10] "m"  PC
 SG_ StdDoppler_12 : 43|10@0+ (0.01,0) [0|10] "m/s"  PC
 SG_ NoInfrastructure_12 : 38|1@0+ (1,0) [0|0] "n/a"  PC
 SG_ Infrastructure_12 : 39|1@0+ (1,0) [0|0] "n/a"  PC
 SG_ Detected_beam_number_12 : 7|2@0+ (1,0) [0|0] "n/a"  PC

BO_ 301 MB79_TARGET_DETECTION_11D: 8 SODX
 SG_ Complex4_Re_11 : 39|16@0- (1,0) [-32768|32767] "n/a"  PC
 SG_ Complex4_Im_11 : 55|16@0- (1,0) [-32768|32767] "n/a"  PC
 SG_ Complex3_Re_11 : 7|16@0- (1,0) [-32768|32767] "n/a"  PC
 SG_ Complex3_Im_11 : 23|16@0- (1,0) [-32768|32767] "n/a"  PC

BO_ 300 MB79_TARGET_DETECTION_11C: 8 SODX
 SG_ Complex2_Re_11 : 39|16@0- (1,0) [-32768|32767] "n/a"  PC
 SG_ Complex2_Im_11 : 55|16@0- (1,0) [-32768|32767] "n/a"  PC
 SG_ Complex1_Re_11 : 7|16@0- (1,0) [-32768|32767] "n/a"  PC
 SG_ Complex1_Im_11 : 23|16@0- (1,0) [-32768|32767] "n/a"  PC

BO_ 299 MB79_TARGET_DETECTION_11B: 8 SODX
 SG_ StdAzimuth_11 : 63|8@0+ (0.0009766,0) [0|14.31] "°"  PC
 SG_ PowerDB_11 : 7|8@0+ (1,0) [0|255] "db"  PC
 SG_ CoGRange_11 : 15|16@0- (0.01,0) [0|96] "m"  PC
 SG_ CoGDoppler_11 : 31|16@0- (0.01,0) [-140|14] "m/s"  PC
 SG_ Azimuth_11 : 47|16@0- (0.1,0) [-180|180] "°"  PC

BO_ 298 MB79_TARGET_DETECTION_11A: 8 SODX
 SG_ WRange10DB_11 : 5|14@0+ (0.01,0) [0|96] "m"  PC
 SG_ WDoppler10DB_11 : 22|15@0+ (0.01,0) [0|280] "m/s"  PC
 SG_ ValidXBeamIndex_11 : 37|10@0+ (1,0) [0|0] "n/a"  PC
 SG_ ValidXBeam_11 : 23|1@0+ (1,0) [0|0] "n/a"  PC
 SG_ StdRange_11 : 49|10@0+ (0.01,0) [0|10] "m"  PC
 SG_ StdDoppler_11 : 43|10@0+ (0.01,0) [0|10] "m/s"  PC
 SG_ NoInfrastructure_11 : 38|1@0+ (1,0) [0|0] "n/a"  PC
 SG_ Infrastructure_11 : 39|1@0+ (1,0) [0|0] "n/a"  PC
 SG_ Detected_beam_number_11 : 7|2@0+ (1,0) [0|0] "n/a"  PC

BO_ 297 MB79_TARGET_DETECTION_10D: 8 SODX
 SG_ Complex4_Re_10 : 39|16@0- (1,0) [-32768|32767] "n/a"  PC
 SG_ Complex4_Im_10 : 55|16@0- (1,0) [-32768|32767] "n/a"  PC
 SG_ Complex3_Re_10 : 7|16@0- (1,0) [-32768|32767] "n/a"  PC
 SG_ Complex3_Im_10 : 23|16@0- (1,0) [-32768|32767] "n/a"  PC

BO_ 296 MB79_TARGET_DETECTION_10C: 8 SODX
 SG_ Complex2_Re_10 : 39|16@0- (1,0) [-32768|32767] "n/a"  PC
 SG_ Complex2_Im_10 : 55|16@0- (1,0) [-32768|32767] "n/a"  PC
 SG_ Complex1_Re_10 : 7|16@0- (1,0) [-32768|32767] "n/a"  PC
 SG_ Complex1_Im_10 : 23|16@0- (1,0) [-32768|32767] "n/a"  PC

BO_ 295 MB79_TARGET_DETECTION_10B: 8 SODX
 SG_ StdAzimuth_10 : 63|8@0+ (0.0009766,0) [0|14.31] "°"  PC
 SG_ PowerDB_10 : 7|8@0+ (1,0) [0|255] "db"  PC
 SG_ CoGRange_10 : 15|16@0- (0.01,0) [0|96] "m"  PC
 SG_ CoGDoppler_10 : 31|16@0- (0.01,0) [-140|14] "m/s"  PC
 SG_ Azimuth_10 : 47|16@0- (0.1,0) [-180|180] "°"  PC

BO_ 294 MB79_TARGET_DETECTION_10A: 8 SODX
 SG_ WRange10DB_10 : 5|14@0+ (0.01,0) [0|96] "m"  PC
 SG_ WDoppler10DB_10 : 22|15@0+ (0.01,0) [0|280] "m/s"  PC
 SG_ ValidXBeamIndex_10 : 37|10@0+ (1,0) [0|0] "n/a"  PC
 SG_ ValidXBeam_10 : 23|1@0+ (1,0) [0|0] "n/a"  PC
 SG_ StdRange_10 : 49|10@0+ (0.01,0) [0|10] "m"  PC
 SG_ StdDoppler_10 : 43|10@0+ (0.01,0) [0|10] "m/s"  PC
 SG_ NoInfrastructure_10 : 38|1@0+ (1,0) [0|0] "n/a"  PC
 SG_ Infrastructure_10 : 39|1@0+ (1,0) [0|0] "n/a"  PC
 SG_ Detected_beam_number_10 : 7|2@0+ (1,0) [0|0] "n/a"  PC

BO_ 1737 MB79_TARGET_DETECTION_100D: 8 SODX
 SG_ Complex4_Re_100 : 39|16@0- (1,0) [-32768|32767] "n/a"  PC
 SG_ Complex4_Im_100 : 55|16@0- (1,0) [-32768|32767] "n/a"  PC
 SG_ Complex3_Re_100 : 7|16@0- (1,0) [-32768|32767] "n/a"  PC
 SG_ Complex3_Im_100 : 23|16@0- (1,0) [-32768|32767] "n/a"  PC

BO_ 1736 MB79_TARGET_DETECTION_100C: 8 SODX
 SG_ Complex2_Re_100 : 39|16@0- (1,0) [-32768|32767] "n/a"  PC
 SG_ Complex2_Im_100 : 55|16@0- (1,0) [-32768|32767] "n/a"  PC
 SG_ Complex1_Re_100 : 7|16@0- (1,0) [-32768|32767] "n/a"  PC
 SG_ Complex1_Im_100 : 23|16@0- (1,0) [-32768|32767] "n/a"  PC

BO_ 1735 MB79_TARGET_DETECTION_100B: 8 SODX
 SG_ StdAzimuth_100 : 63|8@0+ (0.0009766,0) [0|14.31] "°"  PC
 SG_ PowerDB_100 : 7|8@0+ (1,0) [0|255] "db"  PC
 SG_ CoGRange_100 : 15|16@0- (0.01,0) [0|96] "m"  PC
 SG_ CoGDoppler_100 : 31|16@0- (0.01,0) [-140|14] "m/s"  PC
 SG_ Azimuth_100 : 47|16@0- (0.1,0) [-180|180] "°"  PC

BO_ 1734 MB79_TARGET_DETECTION_100A: 8 SODX
 SG_ WRange10DB_100 : 5|14@0+ (0.01,0) [0|96] "m"  PC
 SG_ WDoppler10DB_100 : 22|15@0+ (0.01,0) [0|280] "m/s"  PC
 SG_ ValidXBeamIndex_100 : 37|10@0+ (1,0) [0|0] "n/a"  PC
 SG_ ValidXBeam_100 : 23|1@0+ (1,0) [0|0] "n/a"  PC
 SG_ StdRange_100 : 49|10@0+ (0.01,0) [0|10] "m"  PC
 SG_ StdDoppler_100 : 43|10@0+ (0.01,0) [0|10] "m/s"  PC
 SG_ NoInfrastructure_100 : 38|1@0+ (1,0) [0|0] "n/a"  PC
 SG_ Infrastructure_100 : 39|1@0+ (1,0) [0|0] "n/a"  PC
 SG_ Detected_beam_number_100 : 7|2@0+ (1,0) [0|0] "n/a"  PC

BO_ 2047 MB79_CAN_Transfer_Compelete: 0 SODX

BO_ 1280 LLHT_Respond_Message: 8 SODX
 SG_ Testing_Mode_Options_7_0x500 : 63|8@0+ (1,0) [0|0] ""  PC
 SG_ Testing_Mode_Options_6_0x500 : 55|8@0+ (1,0) [0|0] ""  PC
 SG_ Testing_Mode_Options_5_0x500 : 47|8@0+ (1,0) [0|0] ""  PC
 SG_ Testing_Mode_Options_4_0x500 : 39|8@0+ (1,0) [0|0] ""  PC
 SG_ Testing_Mode_Options_3_0x500 : 31|8@0+ (1,0) [0|0] ""  PC
 SG_ Testing_Mode_Options_2_0x500 : 23|8@0+ (1,0) [0|0] ""  PC
 SG_ Testing_Mode_Options_1_0x500 : 15|8@0+ (1,0) [0|0] ""  PC
 SG_ Testing_Mode_ID_0x500 : 7|8@0+ (1,0) [0|0] ""  PC

BO_ 1536 LLHT_Message: 8 PC
 SG_ Testing_Mode_Options_7_0x600 : 63|8@0+ (1,0) [0|0] ""  SODX
 SG_ Testing_Mode_Options_6_0x600 : 55|8@0+ (1,0) [0|0] ""  SODX
 SG_ Testing_Mode_Options_5_0x600 : 47|8@0+ (1,0) [0|0] ""  SODX
 SG_ Testing_Mode_Options_4_0x600 : 39|8@0+ (1,0) [0|0] ""  SODX
 SG_ Testing_Mode_Options_3_0x600 : 31|8@0+ (1,0) [0|0] ""  SODX
 SG_ Testing_Mode_Options_2_0x600 : 23|8@0+ (1,0) [0|0] ""  SODX
 SG_ Testing_Mode_Options_1_0x600 : 15|8@0+ (1,0) [0|0] ""  SODX
 SG_ Testing_Mode_ID_0x600 : 7|8@0+ (1,0) [0|0] ""  SODX

BO_ 1290 DSP_SODX_LLST_HEADER: 8 SODX
 SG_ LLST_Data_Header_SubID_1 : 23|8@0+ (1,0) [0|0] ""  PC
 SG_ LLST_Data_Header_SubID_0 : 15|8@0+ (1,0) [0|0] ""  PC
 SG_ LLST_Data_Header_Mode_ID : 7|8@0+ (1,0) [0|0] ""  PC
 SG_ LLST_Data_Header_MC8 : 55|8@0+ (1,0) [0|0] ""  PC
 SG_ LLST_Data_Header_FrameCounter : 63|8@0+ (1,0) [0|0] ""  PC
 SG_ LLST_Data_Header_Blocks : 47|8@0+ (1,0) [0|0] ""  PC
 SG_ LLST_Data_Header_BlockLength : 39|8@0+ (1,0) [0|0] ""  PC
 SG_ LLST_Data_Header_BlockCounter : 31|8@0+ (1,0) [0|0] ""  PC

BO_ 1320 DSP_SODX_LLST_29: 8 SODX
 SG_ LLST_Data_29_Payload_3 : 55|16@0+ (1,0) [0|0] ""  PC
 SG_ LLST_Data_29_Payload_2 : 39|16@0+ (1,0) [0|0] ""  PC
 SG_ LLST_Data_29_Payload_1 : 23|16@0+ (1,0) [0|0] ""  PC
 SG_ LLST_Data_29_Payload_0 : 7|16@0+ (1,0) [0|0] ""  PC

BO_ 1319 DSP_SODX_LLST_28: 8 SODX
 SG_ LLST_Data_28_Payload_3 : 55|16@0+ (1,0) [0|0] ""  PC
 SG_ LLST_Data_28_Payload_2 : 39|16@0+ (1,0) [0|0] ""  PC
 SG_ LLST_Data_28_Payload_1 : 23|16@0+ (1,0) [0|0] ""  PC
 SG_ LLST_Data_28_Payload_0 : 7|16@0+ (1,0) [0|0] ""  PC

BO_ 1318 DSP_SODX_LLST_27: 8 SODX
 SG_ LLST_Data_27_Payload_3 : 55|16@0+ (1,0) [0|0] ""  PC
 SG_ LLST_Data_27_Payload_2 : 39|16@0+ (1,0) [0|0] ""  PC
 SG_ LLST_Data_27_Payload_1 : 23|16@0+ (1,0) [0|0] ""  PC
 SG_ LLST_Data_27_Payload_0 : 7|16@0+ (1,0) [0|0] ""  PC

BO_ 1317 DSP_SODX_LLST_26: 8 SODX
 SG_ LLST_Data_26_Payload_3 : 55|16@0+ (1,0) [0|0] ""  PC
 SG_ LLST_Data_26_Payload_2 : 39|16@0+ (1,0) [0|0] ""  PC
 SG_ LLST_Data_26_Payload_1 : 23|16@0+ (1,0) [0|0] ""  PC
 SG_ LLST_Data_26_Payload_0 : 7|16@0+ (1,0) [0|0] ""  PC

BO_ 1316 DSP_SODX_LLST_25: 8 SODX
 SG_ LLST_Data_25_Payload_3 : 55|16@0+ (1,0) [0|0] ""  PC
 SG_ LLST_Data_25_Payload_2 : 39|16@0+ (1,0) [0|0] ""  PC
 SG_ LLST_Data_25_Payload_1 : 23|16@0+ (1,0) [0|0] ""  PC
 SG_ LLST_Data_25_Payload_0 : 7|16@0+ (1,0) [0|0] ""  PC

BO_ 1315 DSP_SODX_LLST_24: 8 SODX
 SG_ LLST_Data_24_Payload_3 : 55|16@0+ (1,0) [0|0] ""  PC
 SG_ LLST_Data_24_Payload_2 : 39|16@0+ (1,0) [0|0] ""  PC
 SG_ LLST_Data_24_Payload_1 : 23|16@0+ (1,0) [0|0] ""  PC
 SG_ LLST_Data_24_Payload_0 : 7|16@0+ (1,0) [0|0] ""  PC

BO_ 1314 DSP_SODX_LLST_23: 8 SODX
 SG_ LLST_Data_23_Payload_3 : 55|16@0+ (1,0) [0|0] ""  PC
 SG_ LLST_Data_23_Payload_2 : 39|16@0+ (1,0) [0|0] ""  PC
 SG_ LLST_Data_23_Payload_1 : 23|16@0+ (1,0) [0|0] ""  PC
 SG_ LLST_Data_23_Payload_0 : 7|16@0+ (1,0) [0|0] ""  PC

BO_ 1313 DSP_SODX_LLST_22: 8 SODX
 SG_ LLST_Data_22_Payload_3 : 55|16@0+ (1,0) [0|0] ""  PC
 SG_ LLST_Data_22_Payload_2 : 39|16@0+ (1,0) [0|0] ""  PC
 SG_ LLST_Data_22_Payload_1 : 23|16@0+ (1,0) [0|0] ""  PC
 SG_ LLST_Data_22_Payload_0 : 7|16@0+ (1,0) [0|0] ""  PC

BO_ 1312 DSP_SODX_LLST_21: 8 SODX
 SG_ LLST_Data_21_Payload_3 : 55|16@0+ (1,0) [0|0] ""  PC
 SG_ LLST_Data_21_Payload_2 : 39|16@0+ (1,0) [0|0] ""  PC
 SG_ LLST_Data_21_Payload_1 : 23|16@0+ (1,0) [0|0] ""  PC
 SG_ LLST_Data_21_Payload_0 : 7|16@0+ (1,0) [0|0] ""  PC

BO_ 1311 DSP_SODX_LLST_20: 8 SODX
 SG_ LLST_Data_20_Payload_3 : 55|16@0+ (1,0) [0|0] ""  PC
 SG_ LLST_Data_20_Payload_2 : 39|16@0+ (1,0) [0|0] ""  PC
 SG_ LLST_Data_20_Payload_1 : 23|16@0+ (1,0) [0|0] ""  PC
 SG_ LLST_Data_20_Payload_0 : 7|16@0+ (1,0) [0|0] ""  PC

BO_ 1310 DSP_SODX_LLST_19: 8 SODX
 SG_ LLST_Data_19_Payload_3 : 55|16@0+ (1,0) [0|0] ""  PC
 SG_ LLST_Data_19_Payload_2 : 39|16@0+ (1,0) [0|0] ""  PC
 SG_ LLST_Data_19_Payload_1 : 23|16@0+ (1,0) [0|0] ""  PC
 SG_ LLST_Data_19_Payload_0 : 7|16@0+ (1,0) [0|0] ""  PC

BO_ 1309 DSP_SODX_LLST_18: 8 SODX
 SG_ LLST_Data_18_Payload_3 : 55|16@0+ (1,0) [0|0] ""  PC
 SG_ LLST_Data_18_Payload_2 : 39|16@0+ (1,0) [0|0] ""  PC
 SG_ LLST_Data_18_Payload_1 : 23|16@0+ (1,0) [0|0] ""  PC
 SG_ LLST_Data_18_Payload_0 : 7|16@0+ (1,0) [0|0] ""  PC

BO_ 1308 DSP_SODX_LLST_17: 8 SODX
 SG_ LLST_Data_17_Payload_3 : 55|16@0+ (1,0) [0|0] ""  PC
 SG_ LLST_Data_17_Payload_2 : 39|16@0+ (1,0) [0|0] ""  PC
 SG_ LLST_Data_17_Payload_1 : 23|16@0+ (1,0) [0|0] ""  PC
 SG_ LLST_Data_17_Payload_0 : 7|16@0+ (1,0) [0|0] ""  PC

BO_ 1307 DSP_SODX_LLST_16: 8 SODX
 SG_ LLST_Data_16_Payload_3 : 55|16@0+ (1,0) [0|0] ""  PC
 SG_ LLST_Data_16_Payload_2 : 39|16@0+ (1,0) [0|0] ""  PC
 SG_ LLST_Data_16_Payload_1 : 23|16@0+ (1,0) [0|0] ""  PC
 SG_ LLST_Data_16_Payload_0 : 7|16@0+ (1,0) [0|0] ""  PC

BO_ 1306 DSP_SODX_LLST_15: 8 SODX
 SG_ LLST_Data_15_Payload_3 : 55|16@0+ (1,0) [0|0] ""  PC
 SG_ LLST_Data_15_Payload_2 : 39|16@0+ (1,0) [0|0] ""  PC
 SG_ LLST_Data_15_Payload_1 : 23|16@0+ (1,0) [0|0] ""  PC
 SG_ LLST_Data_15_Payload_0 : 7|16@0+ (1,0) [0|0] ""  PC

BO_ 1305 DSP_SODX_LLST_14: 8 SODX
 SG_ LLST_Data_14_Payload_3 : 55|16@0+ (1,0) [0|0] ""  PC
 SG_ LLST_Data_14_Payload_2 : 39|16@0+ (1,0) [0|0] ""  PC
 SG_ LLST_Data_14_Payload_1 : 23|16@0+ (1,0) [0|0] ""  PC
 SG_ LLST_Data_14_Payload_0 : 7|16@0+ (1,0) [0|0] ""  PC

BO_ 1304 DSP_SODX_LLST_13: 8 SODX
 SG_ LLST_Data_13_Payload_3 : 55|16@0+ (1,0) [0|0] ""  PC
 SG_ LLST_Data_13_Payload_2 : 39|16@0+ (1,0) [0|0] ""  PC
 SG_ LLST_Data_13_Payload_1 : 23|16@0+ (1,0) [0|0] ""  PC
 SG_ LLST_Data_13_Payload_0 : 7|16@0+ (1,0) [0|0] ""  PC

BO_ 1303 DSP_SODX_LLST_12: 8 SODX
 SG_ LLST_Data_12_Payload_3 : 55|16@0+ (1,0) [0|0] ""  PC
 SG_ LLST_Data_12_Payload_2 : 39|16@0+ (1,0) [0|0] ""  PC
 SG_ LLST_Data_12_Payload_1 : 23|16@0+ (1,0) [0|0] ""  PC
 SG_ LLST_Data_12_Payload_0 : 7|16@0+ (1,0) [0|0] ""  PC

BO_ 1302 DSP_SODX_LLST_11: 8 SODX
 SG_ LLST_Data_11_Payload_3 : 55|16@0+ (1,0) [0|0] ""  PC
 SG_ LLST_Data_11_Payload_2 : 39|16@0+ (1,0) [0|0] ""  PC
 SG_ LLST_Data_11_Payload_1 : 23|16@0+ (1,0) [0|0] ""  PC
 SG_ LLST_Data_11_Payload_0 : 7|16@0+ (1,0) [0|0] ""  PC

BO_ 1301 DSP_SODX_LLST_10: 8 SODX
 SG_ LLST_Data_10_Payload_3 : 55|16@0+ (1,0) [0|0] ""  PC
 SG_ LLST_Data_10_Payload_2 : 39|16@0+ (1,0) [0|0] ""  PC
 SG_ LLST_Data_10_Payload_1 : 23|16@0+ (1,0) [0|0] ""  PC
 SG_ LLST_Data_10_Payload_0 : 7|16@0+ (1,0) [0|0] ""  PC

BO_ 1300 DSP_SODX_LLST_09: 8 SODX
 SG_ LLST_Data_9_Payload_3 : 55|16@0+ (1,0) [0|0] ""  PC
 SG_ LLST_Data_9_Payload_2 : 39|16@0+ (1,0) [0|0] ""  PC
 SG_ LLST_Data_9_Payload_1 : 23|16@0+ (1,0) [0|0] ""  PC
 SG_ LLST_Data_9_Payload_0 : 7|16@0+ (1,0) [0|0] ""  PC

BO_ 1299 DSP_SODX_LLST_08: 8 SODX
 SG_ LLST_Data_8_Payload_3 : 55|16@0+ (1,0) [0|0] ""  PC
 SG_ LLST_Data_8_Payload_2 : 39|16@0+ (1,0) [0|0] ""  PC
 SG_ LLST_Data_8_Payload_1 : 23|16@0+ (1,0) [0|0] ""  PC
 SG_ LLST_Data_8_Payload_0 : 7|16@0+ (1,0) [0|0] ""  PC

BO_ 1298 DSP_SODX_LLST_07: 8 SODX
 SG_ LLST_Data_7_Payload_3 : 55|16@0+ (1,0) [0|0] ""  PC
 SG_ LLST_Data_7_Payload_2 : 39|16@0+ (1,0) [0|0] ""  PC
 SG_ LLST_Data_7_Payload_1 : 23|16@0+ (1,0) [0|0] ""  PC
 SG_ LLST_Data_7_Payload_0 : 7|16@0+ (1,0) [0|0] ""  PC

BO_ 1297 DSP_SODX_LLST_06: 8 SODX
 SG_ LLST_Data_6_Payload_3 : 55|16@0+ (1,0) [0|0] ""  PC
 SG_ LLST_Data_6_Payload_2 : 39|16@0+ (1,0) [0|0] ""  PC
 SG_ LLST_Data_6_Payload_1 : 23|16@0+ (1,0) [0|0] ""  PC
 SG_ LLST_Data_6_Payload_0 : 7|16@0+ (1,0) [0|0] ""  PC

BO_ 1296 DSP_SODX_LLST_05: 8 SODX
 SG_ LLST_Data_5_Payload_3 : 55|16@0+ (1,0) [0|0] ""  PC
 SG_ LLST_Data_5_Payload_2 : 39|16@0+ (1,0) [0|0] ""  PC
 SG_ LLST_Data_5_Payload_1 : 23|16@0+ (1,0) [0|0] ""  PC
 SG_ LLST_Data_5_Payload_0 : 7|16@0+ (1,0) [0|0] ""  PC

BO_ 1295 DSP_SODX_LLST_04: 8 SODX
 SG_ LLST_Data_4_Payload_3 : 55|16@0+ (1,0) [0|0] ""  PC
 SG_ LLST_Data_4_Payload_2 : 39|16@0+ (1,0) [0|0] ""  PC
 SG_ LLST_Data_4_Payload_1 : 23|16@0+ (1,0) [0|0] ""  PC
 SG_ LLST_Data_4_Payload_0 : 7|16@0+ (1,0) [0|0] ""  PC

BO_ 1294 DSP_SODX_LLST_03: 8 SODX
 SG_ LLST_Data_3_Payload_3 : 55|16@0+ (1,0) [0|0] ""  PC
 SG_ LLST_Data_3_Payload_2 : 39|16@0+ (1,0) [0|0] ""  PC
 SG_ LLST_Data_3_Payload_1 : 23|16@0+ (1,0) [0|0] ""  PC
 SG_ LLST_Data_3_Payload_0 : 7|16@0+ (1,0) [0|0] ""  PC

BO_ 1293 DSP_SODX_LLST_02: 8 SODX
 SG_ LLST_Data_2_Payload_3 : 55|16@0+ (1,0) [0|0] ""  PC
 SG_ LLST_Data_2_Payload_2 : 39|16@0+ (1,0) [0|0] ""  PC
 SG_ LLST_Data_2_Payload_1 : 23|16@0+ (1,0) [0|0] ""  PC
 SG_ LLST_Data_2_Payload_0 : 7|16@0+ (1,0) [0|0] ""  PC

BO_ 1292 DSP_SODX_LLST_01: 8 SODX
 SG_ LLST_Data_1_Payload_3 : 55|16@0+ (1,0) [0|0] ""  PC
 SG_ LLST_Data_1_Payload_2 : 39|16@0+ (1,0) [0|0] ""  PC
 SG_ LLST_Data_1_Payload_1 : 23|16@0+ (1,0) [0|0] ""  PC
 SG_ LLST_Data_1_Payload_0 : 7|16@0+ (1,0) [0|0] ""  PC

BO_ 1291 DSP_SODX_LLST_0: 8 SODX
 SG_ LLST_Data_0_Payload_3 : 55|16@0+ (1,0) [0|0] ""  PC
 SG_ LLST_Data_0_Payload_2 : 39|16@0+ (1,0) [0|0] ""  PC
 SG_ LLST_Data_0_Payload_1 : 23|16@0+ (1,0) [0|0] ""  PC
 SG_ LLST_Data_0_Payload_0 : 7|16@0+ (1,0) [0|0] ""  PC

BO_ 9 CAN_ID_PTPN_SLAVE_SYNC: 8 SODX
 SG_ slave_id_0x9 : 47|8@0- (1,0) [-128|127] "cdeg"  PC
 SG_ PTPN_Timestamp_0x9 : 7|32@0+ (1,0) [0|255] ""  PC
 SG_ PTP_dummy1_0x9 : 55|16@0- (1,0) [-128|127] "cdeg"  PC
 SG_ message_type_0x9 : 39|8@0+ (1,0) [0|200] "cm"  PC

BO_ 8 CAN_ID_PTPN_MASTER_SYNC: 8 PC
 SG_ slave_id_0x8 : 47|8@0- (1,0) [-128|127] "cdeg"  SODX
 SG_ PTPN_Timestamp_0x8 : 7|32@0+ (1,0) [0|255] ""  SODX
 SG_ PTP_dummy1_0x8 : 55|16@0- (1,0) [-128|127] "cdeg"  SODX
 SG_ message_type_0x8 : 39|8@0+ (1,0) [0|200] "cm"  SODX

BO_ 17 CAN_ID_PC_VEHICLE_DATA_2: 8 PC
 SG_ YawRate : 55|16@0- (0.0009765625,0) [-2028|2048] "cm/s^2"  SODX
 SG_ Veh_Speed : 7|16@0- (1,0) [-2000|14000] "cm/s"  SODX
 SG_ LongAcc : 23|16@0- (1,0) [-2000|2000] "cm/s^2"  SODX
 SG_ LatAcc : 39|16@0- (1,0) [-2000|2000] "cm/s^2"  SODX

BO_ 16 CAN_ID_PC_VEHICLE_DATA_1: 2 PC
 SG_ HostDrivingForward : 7|8@0+ (1,0) [0|0] ""  SODX
 SG_ GearPosition : 15|8@0+ (1,0) [0|0] ""  SODX

BO_ 5 CAN_ID_PC_START_PROCESSING: 0 PC

BO_ 6 CAN_ID_PC_SENSOR_POSITION: 8 PC
 SG_ z_position : 47|8@0+ (1,0) [0|200] "cm"  PC
 SG_ y_position_MSB : 31|8@0- (1,0) [-128|127] "mm"  PC
 SG_ y_position_LSB : 39|8@0- (1,0) [-128|127] "mm"  PC
 SG_ x_position_MSB : 15|8@0- (1,0) [-128|127] "mm"  PC
 SG_ x_position_LSB : 23|8@0- (1,0) [-128|127] "mm"  PC
 SG_ Sensor_Position : 7|8@0+ (1,0) [0|255] ""  PC
 SG_ orientation_angle_MSB : 55|8@0- (1,0) [-128|127] "cdeg"  PC
 SG_ orientation_angle_LSB : 63|8@0- (1,0) [-128|127] "cdeg"  PC

BO_ 1057 CAN_ID_PC_ROL_MODE_CONTROL: 5 PC
 SG_ Rol_Mode_Status : 39|8@0+ (1,0) [0|255] ""  SODX
 SG_ dummy_not_used4 : 31|8@0+ (1,0) [0|255] ""  SODX
 SG_ dummy_not_used3 : 23|8@0+ (1,0) [0|255] ""  SODX
 SG_ dummy_not_used2 : 15|8@0+ (1,0) [0|255] ""  SODX
 SG_ dummy_not_used1 : 7|8@0+ (1,0) [0|255] ""  SODX

BO_ 1049 CAN_ID_PC_REQUEST_PARAM_DATA: 0 PC

BO_ 1051 CAN_ID_PC_REQ_CALIBRATION_DATA: 0 PC

BO_ 3 CAN_ID_PC_PREPARE_SYNC: 0 PC

BO_ 832 CAN_ID_MB79_VEHICLE_DATA: 8 SODX
 SG_ YawRate_sensor : 23|16@0+ (1,0) [0|0] ""  PC
 SG_ Veh_Speed_sensor : 7|16@0+ (1,0) [0|0] ""  PC
 SG_ LongAcc_sensor : 39|16@0+ (1,0) [0|0] ""  PC
 SG_ dummy_vd_2 : 63|8@0+ (1,0) [0|0] ""  PC
 SG_ dummy_vd_1 : 55|8@0+ (1,0) [0|0] ""  PC

BO_ 513 CAN_ID_MB79_TRACKS_XY_HEADER: 8 SODX
 SG_ uiMCC : 15|32@0+ (1,0) [0|0] ""  PC
 SG_ dummy_h_4 : 63|8@0+ (1,0) [0|0] ""  PC
 SG_ dummy_h_3 : 55|8@0+ (1,0) [0|0] ""  PC
 SG_ dummy_h_2 : 47|8@0+ (1,0) [0|0] ""  PC
 SG_ dummy_h_1 : 7|8@0+ (1,0) [0|0] ""  PC

BO_ 813 CAN_ID_MB79_SW_VERSION: 8 SODX
 SG_ SW_version_MCU_Build : 39|16@0+ (1,0) [0|0] ""  PC
 SG_ SW_version_MCU_Branch : 23|16@0+ (1,0) [0|0] ""  PC
 SG_ SW_version_MCU_Application : 7|16@0+ (1,0) [0|0] ""  PC
 SG_ eeprom_data_ee_version : 55|16@0+ (1,0) [0|0] ""  PC

BO_ 768 CAN_ID_MB79_SENSORINTERNALS1: 8 SODX
 SG_ sensor_Serial_Number : 7|32@0+ (1,0) [0|0] ""  PC
 SG_ dummy_n_4 : 63|8@0+ (1,0) [0|0] ""  PC
 SG_ dummy_n_3 : 55|8@0+ (1,0) [0|0] ""  PC
 SG_ dummy_n_2 : 47|8@0+ (1,0) [0|0] ""  PC
 SG_ dummy_n_1 : 39|8@0+ (1,0) [0|0] ""  PC

BO_ 4 CAN_ID_MB79_PROCESSING_STOPPED: 0 SODX

BO_ 7 CAN_ID_MB79_PROCESSING_ACK: 4 SODX
 SG_ chirp_gen_delay_7_0 : 31|8@0+ (1,0) [0|255] ""  PC
 SG_ chirp_gen_delay_31_24 : 7|8@0+ (1,0) [0|255] ""  PC
 SG_ chirp_gen_delay_23_16 : 15|8@0+ (1,0) [0|255] ""  PC
 SG_ chirp_gen_delay_15_8 : 23|8@0+ (1,0) [0|255] ""  PC

EV_ env_start_stop_simulation: 0 [0|1] "" 0 6 DUMMY_NODE_VECTOR0  PC;

EV_ env_OFFLINE_ObstacleType: 0 [0|4] "" 0 5 DUMMY_NODE_VECTOR0  PC;

EV_ env_Obstacle_YVelocity: 1 [-512|512] "" 0 4 DUMMY_NODE_VECTOR0  PC;

EV_ env_Obstacle_YPos: 1 [-65536|65536] "" 0 3 DUMMY_NODE_VECTOR3  PC;

EV_ env_Obstacle_XVelocity: 1 [-512|512] "" 0 2 DUMMY_NODE_VECTOR0  PC;

EV_ env_Obstacle_XPos: 1 [-524288|524288] "" 0 1 DUMMY_NODE_VECTOR3  PC;
CM_ SG_ 271 StdAzimuth_4 "Standard deviation of azimuth (in °)";
CM_ SG_ 271 PowerDB_4 "Power of detection in db";
CM_ SG_ 271 CoGRange_4 "Center of gravity range (in m)";
CM_ SG_ 271 CoGDoppler_4 "Center of gravity Doppler (in m/s)";
CM_ SG_ 271 Azimuth_4 "Azimuth angle of detection (in degree in driving direction coordinate system)";
CM_ SG_ 270 WRange10DB_4 "10 dB width of detection in range dimension (in m)";
CM_ SG_ 270 WDoppler10DB_4 "10 dB width of detection in Doppler dimension (in m/s)";
CM_ SG_ 270 ValidXBeamIndex_4 "Corresponding Index of in detection list of other beam";
CM_ SG_ 270 ValidXBeam_4 "Validated by detection in other beam/measurement";
CM_ SG_ 270 StdRange_4 "Standard deviation of range measurement (m)";
CM_ SG_ 270 StdDoppler_4 "Standard deviation of Doppler measurement (in m/s)";
CM_ SG_ 270 NoInfrastructure_4 "Target is moving (with high confidence)";
CM_ SG_ 270 Infrastructure_4 "Target is stationary (infrastructure)";
CM_ SG_ 453 Complex4_Re_49 "Complex FFT data (Re, Im) Rx channel 4";
CM_ SG_ 453 Complex4_Im_49 "Complex FFT data (Re, Im) Rx channel 4";
CM_ SG_ 453 Complex3_Re_49 "Complex FFT data (Re, Im) Rx channel 3";
CM_ SG_ 453 Complex3_Im_49 "Complex FFT data (Re, Im) Rx channel 3";
CM_ SG_ 452 Complex2_Re_49 "Complex FFT data (Re, Im) Rx channel 2";
CM_ SG_ 452 Complex2_Im_49 "Complex FFT data (Re, Im) Rx channel 2";
CM_ SG_ 452 Complex1_Re_49 "Complex FFT data (Re, Im) Rx channel 1";
CM_ SG_ 452 Complex1_Im_49 "Complex FFT data (Re, Im) Rx channel 1";
CM_ SG_ 451 StdAzimuth_49 "Standard deviation of azimuth (in °)";
CM_ SG_ 451 PowerDB_49 "Power of detection in db";
CM_ SG_ 451 CoGRange_49 "Center of gravity range (in m)";
CM_ SG_ 451 CoGDoppler_49 "Center of gravity Doppler (in m/s)";
CM_ SG_ 451 Azimuth_49 "Azimuth angle of detection (in degree in driving direction coordinate system)";
CM_ SG_ 450 WRange10DB_49 "10 dB width of detection in range dimension (in m)";
CM_ SG_ 450 WDoppler10DB_49 "10 dB width of detection in Doppler dimension (in m/s)";
CM_ SG_ 450 ValidXBeamIndex_49 "Corresponding Index of in detection list of other beam";
CM_ SG_ 450 ValidXBeam_49 "Validated by detection in other beam/measurement";
CM_ SG_ 450 StdRange_49 "Standard deviation of range measurement (m)";
CM_ SG_ 450 StdDoppler_49 "Standard deviation of Doppler measurement (in m/s)";
CM_ SG_ 450 NoInfrastructure_49 "Target is moving (with high confidence)";
CM_ SG_ 450 Infrastructure_49 "Target is stationary (infrastructure)";
CM_ SG_ 449 Complex4_Re_48 "Complex FFT data (Re, Im) Rx channel 4";
CM_ SG_ 449 Complex4_Im_48 "Complex FFT data (Re, Im) Rx channel 4";
CM_ SG_ 449 Complex3_Re_48 "Complex FFT data (Re, Im) Rx channel 3";
CM_ SG_ 449 Complex3_Im_48 "Complex FFT data (Re, Im) Rx channel 3";
CM_ SG_ 448 Complex2_Re_48 "Complex FFT data (Re, Im) Rx channel 2";
CM_ SG_ 448 Complex2_Im_48 "Complex FFT data (Re, Im) Rx channel 2";
CM_ SG_ 448 Complex1_Re_48 "Complex FFT data (Re, Im) Rx channel 1";
CM_ SG_ 448 Complex1_Im_48 "Complex FFT data (Re, Im) Rx channel 1";
CM_ SG_ 447 StdAzimuth_48 "Standard deviation of azimuth (in °)";
CM_ SG_ 447 PowerDB_48 "Power of detection in db";
CM_ SG_ 447 CoGRange_48 "Center of gravity range (in m)";
CM_ SG_ 447 CoGDoppler_48 "Center of gravity Doppler (in m/s)";
CM_ SG_ 447 Azimuth_48 "Azimuth angle of detection (in degree in driving direction coordinate system)";
CM_ SG_ 446 WRange10DB_48 "10 dB width of detection in range dimension (in m)";
CM_ SG_ 446 WDoppler10DB_48 "10 dB width of detection in Doppler dimension (in m/s)";
CM_ SG_ 446 ValidXBeamIndex_48 "Corresponding Index of in detection list of other beam";
CM_ SG_ 446 ValidXBeam_48 "Validated by detection in other beam/measurement";
CM_ SG_ 446 StdRange_48 "Standard deviation of range measurement (m)";
CM_ SG_ 446 StdDoppler_48 "Standard deviation of Doppler measurement (in m/s)";
CM_ SG_ 446 NoInfrastructure_48 "Target is moving (with high confidence)";
CM_ SG_ 446 Infrastructure_48 "Target is stationary (infrastructure)";
CM_ SG_ 445 Complex4_Re_47 "Complex FFT data (Re, Im) Rx channel 4";
CM_ SG_ 445 Complex4_Im_47 "Complex FFT data (Re, Im) Rx channel 4";
CM_ SG_ 445 Complex3_Re_47 "Complex FFT data (Re, Im) Rx channel 3";
CM_ SG_ 445 Complex3_Im_47 "Complex FFT data (Re, Im) Rx channel 3";
CM_ SG_ 444 Complex2_Re_47 "Complex FFT data (Re, Im) Rx channel 2";
CM_ SG_ 444 Complex2_Im_47 "Complex FFT data (Re, Im) Rx channel 2";
CM_ SG_ 444 Complex1_Re_47 "Complex FFT data (Re, Im) Rx channel 1";
CM_ SG_ 444 Complex1_Im_47 "Complex FFT data (Re, Im) Rx channel 1";
CM_ SG_ 443 StdAzimuth_47 "Standard deviation of azimuth (in °)";
CM_ SG_ 443 PowerDB_47 "Power of detection in db";
CM_ SG_ 443 CoGRange_47 "Center of gravity range (in m)";
CM_ SG_ 443 CoGDoppler_47 "Center of gravity Doppler (in m/s)";
CM_ SG_ 443 Azimuth_47 "Azimuth angle of detection (in degree in driving direction coordinate system)";
CM_ SG_ 442 WRange10DB_47 "10 dB width of detection in range dimension (in m)";
CM_ SG_ 442 WDoppler10DB_47 "10 dB width of detection in Doppler dimension (in m/s)";
CM_ SG_ 442 ValidXBeamIndex_47 "Corresponding Index of in detection list of other beam";
CM_ SG_ 442 ValidXBeam_47 "Validated by detection in other beam/measurement";
CM_ SG_ 442 StdRange_47 "Standard deviation of range measurement (m)";
CM_ SG_ 442 StdDoppler_47 "Standard deviation of Doppler measurement (in m/s)";
CM_ SG_ 442 NoInfrastructure_47 "Target is moving (with high confidence)";
CM_ SG_ 442 Infrastructure_47 "Target is stationary (infrastructure)";
CM_ SG_ 441 Complex4_Re_46 "Complex FFT data (Re, Im) Rx channel 4";
CM_ SG_ 441 Complex4_Im_46 "Complex FFT data (Re, Im) Rx channel 4";
CM_ SG_ 441 Complex3_Re_46 "Complex FFT data (Re, Im) Rx channel 3";
CM_ SG_ 441 Complex3_Im_46 "Complex FFT data (Re, Im) Rx channel 3";
CM_ SG_ 440 Complex2_Re_46 "Complex FFT data (Re, Im) Rx channel 2";
CM_ SG_ 440 Complex2_Im_46 "Complex FFT data (Re, Im) Rx channel 2";
CM_ SG_ 440 Complex1_Re_46 "Complex FFT data (Re, Im) Rx channel 1";
CM_ SG_ 440 Complex1_Im_46 "Complex FFT data (Re, Im) Rx channel 1";
CM_ SG_ 439 StdAzimuth_46 "Standard deviation of azimuth (in °)";
CM_ SG_ 439 PowerDB_46 "Power of detection in db";
CM_ SG_ 439 CoGRange_46 "Center of gravity range (in m)";
CM_ SG_ 439 CoGDoppler_46 "Center of gravity Doppler (in m/s)";
CM_ SG_ 439 Azimuth_46 "Azimuth angle of detection (in degree in driving direction coordinate system)";
CM_ SG_ 438 WRange10DB_46 "10 dB width of detection in range dimension (in m)";
CM_ SG_ 438 WDoppler10DB_46 "10 dB width of detection in Doppler dimension (in m/s)";
CM_ SG_ 438 ValidXBeamIndex_46 "Corresponding Index of in detection list of other beam";
CM_ SG_ 438 ValidXBeam_46 "Validated by detection in other beam/measurement";
CM_ SG_ 438 StdRange_46 "Standard deviation of range measurement (m)";
CM_ SG_ 438 StdDoppler_46 "Standard deviation of Doppler measurement (in m/s)";
CM_ SG_ 438 NoInfrastructure_46 "Target is moving (with high confidence)";
CM_ SG_ 438 Infrastructure_46 "Target is stationary (infrastructure)";
CM_ SG_ 437 Complex4_Re_45 "Complex FFT data (Re, Im) Rx channel 4";
CM_ SG_ 437 Complex4_Im_45 "Complex FFT data (Re, Im) Rx channel 4";
CM_ SG_ 437 Complex3_Re_45 "Complex FFT data (Re, Im) Rx channel 3";
CM_ SG_ 437 Complex3_Im_45 "Complex FFT data (Re, Im) Rx channel 3";
CM_ SG_ 436 Complex2_Re_45 "Complex FFT data (Re, Im) Rx channel 2";
CM_ SG_ 436 Complex2_Im_45 "Complex FFT data (Re, Im) Rx channel 2";
CM_ SG_ 436 Complex1_Re_45 "Complex FFT data (Re, Im) Rx channel 1";
CM_ SG_ 436 Complex1_Im_45 "Complex FFT data (Re, Im) Rx channel 1";
CM_ SG_ 435 StdAzimuth_45 "Standard deviation of azimuth (in °)";
CM_ SG_ 435 PowerDB_45 "Power of detection in db";
CM_ SG_ 435 CoGRange_45 "Center of gravity range (in m)";
CM_ SG_ 435 CoGDoppler_45 "Center of gravity Doppler (in m/s)";
CM_ SG_ 435 Azimuth_45 "Azimuth angle of detection (in degree in driving direction coordinate system)";
CM_ SG_ 434 WRange10DB_45 "10 dB width of detection in range dimension (in m)";
CM_ SG_ 434 WDoppler10DB_45 "10 dB width of detection in Doppler dimension (in m/s)";
CM_ SG_ 434 ValidXBeamIndex_45 "Corresponding Index of in detection list of other beam";
CM_ SG_ 434 ValidXBeam_45 "Validated by detection in other beam/measurement";
CM_ SG_ 434 StdRange_45 "Standard deviation of range measurement (m)";
CM_ SG_ 434 StdDoppler_45 "Standard deviation of Doppler measurement (in m/s)";
CM_ SG_ 434 NoInfrastructure_45 "Target is moving (with high confidence)";
CM_ SG_ 434 Infrastructure_45 "Target is stationary (infrastructure)";
CM_ SG_ 433 Complex4_Re_44 "Complex FFT data (Re, Im) Rx channel 4";
CM_ SG_ 433 Complex4_Im_44 "Complex FFT data (Re, Im) Rx channel 4";
CM_ SG_ 433 Complex3_Re_44 "Complex FFT data (Re, Im) Rx channel 3";
CM_ SG_ 433 Complex3_Im_44 "Complex FFT data (Re, Im) Rx channel 3";
CM_ SG_ 432 Complex2_Re_44 "Complex FFT data (Re, Im) Rx channel 2";
CM_ SG_ 432 Complex2_Im_44 "Complex FFT data (Re, Im) Rx channel 2";
CM_ SG_ 432 Complex1_Re_44 "Complex FFT data (Re, Im) Rx channel 1";
CM_ SG_ 432 Complex1_Im_44 "Complex FFT data (Re, Im) Rx channel 1";
CM_ SG_ 431 StdAzimuth_44 "Standard deviation of azimuth (in °)";
CM_ SG_ 431 PowerDB_44 "Power of detection in db";
CM_ SG_ 431 CoGRange_44 "Center of gravity range (in m)";
CM_ SG_ 431 CoGDoppler_44 "Center of gravity Doppler (in m/s)";
CM_ SG_ 431 Azimuth_44 "Azimuth angle of detection (in degree in driving direction coordinate system)";
CM_ SG_ 430 WRange10DB_44 "10 dB width of detection in range dimension (in m)";
CM_ SG_ 430 WDoppler10DB_44 "10 dB width of detection in Doppler dimension (in m/s)";
CM_ SG_ 430 ValidXBeamIndex_44 "Corresponding Index of in detection list of other beam";
CM_ SG_ 430 ValidXBeam_44 "Validated by detection in other beam/measurement";
CM_ SG_ 430 StdRange_44 "Standard deviation of range measurement (m)";
CM_ SG_ 430 StdDoppler_44 "Standard deviation of Doppler measurement (in m/s)";
CM_ SG_ 430 NoInfrastructure_44 "Target is moving (with high confidence)";
CM_ SG_ 430 Infrastructure_44 "Target is stationary (infrastructure)";
CM_ SG_ 429 Complex4_Re_43 "Complex FFT data (Re, Im) Rx channel 4";
CM_ SG_ 429 Complex4_Im_43 "Complex FFT data (Re, Im) Rx channel 4";
CM_ SG_ 429 Complex3_Re_43 "Complex FFT data (Re, Im) Rx channel 3";
CM_ SG_ 429 Complex3_Im_43 "Complex FFT data (Re, Im) Rx channel 3";
CM_ SG_ 428 Complex2_Re_43 "Complex FFT data (Re, Im) Rx channel 2";
CM_ SG_ 428 Complex2_Im_43 "Complex FFT data (Re, Im) Rx channel 2";
CM_ SG_ 428 Complex1_Re_43 "Complex FFT data (Re, Im) Rx channel 1";
CM_ SG_ 428 Complex1_Im_43 "Complex FFT data (Re, Im) Rx channel 1";
CM_ SG_ 427 StdAzimuth_43 "Standard deviation of azimuth (in °)";
CM_ SG_ 427 PowerDB_43 "Power of detection in db";
CM_ SG_ 427 CoGRange_43 "Center of gravity range (in m)";
CM_ SG_ 427 CoGDoppler_43 "Center of gravity Doppler (in m/s)";
CM_ SG_ 427 Azimuth_43 "Azimuth angle of detection (in degree in driving direction coordinate system)";
CM_ SG_ 426 WRange10DB_43 "10 dB width of detection in range dimension (in m)";
CM_ SG_ 426 WDoppler10DB_43 "10 dB width of detection in Doppler dimension (in m/s)";
CM_ SG_ 426 ValidXBeamIndex_43 "Corresponding Index of in detection list of other beam";
CM_ SG_ 426 ValidXBeam_43 "Validated by detection in other beam/measurement";
CM_ SG_ 426 StdRange_43 "Standard deviation of range measurement (m)";
CM_ SG_ 426 StdDoppler_43 "Standard deviation of Doppler measurement (in m/s)";
CM_ SG_ 426 NoInfrastructure_43 "Target is moving (with high confidence)";
CM_ SG_ 426 Infrastructure_43 "Target is stationary (infrastructure)";
CM_ SG_ 425 Complex4_Re_42 "Complex FFT data (Re, Im) Rx channel 4";
CM_ SG_ 425 Complex4_Im_42 "Complex FFT data (Re, Im) Rx channel 4";
CM_ SG_ 425 Complex3_Re_42 "Complex FFT data (Re, Im) Rx channel 3";
CM_ SG_ 425 Complex3_Im_42 "Complex FFT data (Re, Im) Rx channel 3";
CM_ SG_ 424 Complex2_Re_42 "Complex FFT data (Re, Im) Rx channel 2";
CM_ SG_ 424 Complex2_Im_42 "Complex FFT data (Re, Im) Rx channel 2";
CM_ SG_ 424 Complex1_Re_42 "Complex FFT data (Re, Im) Rx channel 1";
CM_ SG_ 424 Complex1_Im_42 "Complex FFT data (Re, Im) Rx channel 1";
CM_ SG_ 423 StdAzimuth_42 "Standard deviation of azimuth (in °)";
CM_ SG_ 423 PowerDB_42 "Power of detection in db";
CM_ SG_ 423 CoGRange_42 "Center of gravity range (in m)";
CM_ SG_ 423 CoGDoppler_42 "Center of gravity Doppler (in m/s)";
CM_ SG_ 423 Azimuth_42 "Azimuth angle of detection (in degree in driving direction coordinate system)";
CM_ SG_ 422 WRange10DB_42 "10 dB width of detection in range dimension (in m)";
CM_ SG_ 422 WDoppler10DB_42 "10 dB width of detection in Doppler dimension (in m/s)";
CM_ SG_ 422 ValidXBeamIndex_42 "Corresponding Index of in detection list of other beam";
CM_ SG_ 422 ValidXBeam_42 "Validated by detection in other beam/measurement";
CM_ SG_ 422 StdRange_42 "Standard deviation of range measurement (m)";
CM_ SG_ 422 StdDoppler_42 "Standard deviation of Doppler measurement (in m/s)";
CM_ SG_ 422 NoInfrastructure_42 "Target is moving (with high confidence)";
CM_ SG_ 422 Infrastructure_42 "Target is stationary (infrastructure)";
CM_ SG_ 421 Complex4_Re_41 "Complex FFT data (Re, Im) Rx channel 4";
CM_ SG_ 421 Complex4_Im_41 "Complex FFT data (Re, Im) Rx channel 4";
CM_ SG_ 421 Complex3_Re_41 "Complex FFT data (Re, Im) Rx channel 3";
CM_ SG_ 421 Complex3_Im_41 "Complex FFT data (Re, Im) Rx channel 3";
CM_ SG_ 420 Complex2_Re_41 "Complex FFT data (Re, Im) Rx channel 2";
CM_ SG_ 420 Complex2_Im_41 "Complex FFT data (Re, Im) Rx channel 2";
CM_ SG_ 420 Complex1_Re_41 "Complex FFT data (Re, Im) Rx channel 1";
CM_ SG_ 420 Complex1_Im_41 "Complex FFT data (Re, Im) Rx channel 1";
CM_ SG_ 419 StdAzimuth_41 "Standard deviation of azimuth (in °)";
CM_ SG_ 419 PowerDB_41 "Power of detection in db";
CM_ SG_ 419 CoGRange_41 "Center of gravity range (in m)";
CM_ SG_ 419 CoGDoppler_41 "Center of gravity Doppler (in m/s)";
CM_ SG_ 419 Azimuth_41 "Azimuth angle of detection (in degree in driving direction coordinate system)";
CM_ SG_ 418 WRange10DB_41 "10 dB width of detection in range dimension (in m)";
CM_ SG_ 418 WDoppler10DB_41 "10 dB width of detection in Doppler dimension (in m/s)";
CM_ SG_ 418 ValidXBeamIndex_41 "Corresponding Index of in detection list of other beam";
CM_ SG_ 418 ValidXBeam_41 "Validated by detection in other beam/measurement";
CM_ SG_ 418 StdRange_41 "Standard deviation of range measurement (m)";
CM_ SG_ 418 StdDoppler_41 "Standard deviation of Doppler measurement (in m/s)";
CM_ SG_ 418 NoInfrastructure_41 "Target is moving (with high confidence)";
CM_ SG_ 418 Infrastructure_41 "Target is stationary (infrastructure)";
CM_ SG_ 417 Complex4_Re_40 "Complex FFT data (Re, Im) Rx channel 4";
CM_ SG_ 417 Complex4_Im_40 "Complex FFT data (Re, Im) Rx channel 4";
CM_ SG_ 417 Complex3_Re_40 "Complex FFT data (Re, Im) Rx channel 3";
CM_ SG_ 417 Complex3_Im_40 "Complex FFT data (Re, Im) Rx channel 3";
CM_ SG_ 416 Complex2_Re_40 "Complex FFT data (Re, Im) Rx channel 2";
CM_ SG_ 416 Complex2_Im_40 "Complex FFT data (Re, Im) Rx channel 2";
CM_ SG_ 416 Complex1_Re_40 "Complex FFT data (Re, Im) Rx channel 1";
CM_ SG_ 416 Complex1_Im_40 "Complex FFT data (Re, Im) Rx channel 1";
CM_ SG_ 415 StdAzimuth_40 "Standard deviation of azimuth (in °)";
CM_ SG_ 415 PowerDB_40 "Power of detection in db";
CM_ SG_ 415 CoGRange_40 "Center of gravity range (in m)";
CM_ SG_ 415 CoGDoppler_40 "Center of gravity Doppler (in m/s)";
CM_ SG_ 415 Azimuth_40 "Azimuth angle of detection (in degree in driving direction coordinate system)";
CM_ SG_ 414 WRange10DB_40 "10 dB width of detection in range dimension (in m)";
CM_ SG_ 414 WDoppler10DB_40 "10 dB width of detection in Doppler dimension (in m/s)";
CM_ SG_ 414 ValidXBeamIndex_40 "Corresponding Index of in detection list of other beam";
CM_ SG_ 414 ValidXBeam_40 "Validated by detection in other beam/measurement";
CM_ SG_ 414 StdRange_40 "Standard deviation of range measurement (m)";
CM_ SG_ 414 StdDoppler_40 "Standard deviation of Doppler measurement (in m/s)";
CM_ SG_ 414 NoInfrastructure_40 "Target is moving (with high confidence)";
CM_ SG_ 414 Infrastructure_40 "Target is stationary (infrastructure)";
CM_ SG_ 269 Complex4_Re_3 "Complex FFT data (Re, Im) Rx channel 4";
CM_ SG_ 269 Complex4_Im_3 "Complex FFT data (Re, Im) Rx channel 4";
CM_ SG_ 269 Complex3_Re_3 "Complex FFT data (Re, Im) Rx channel 3";
CM_ SG_ 269 Complex3_Im_3 "Complex FFT data (Re, Im) Rx channel 3";
CM_ SG_ 268 Complex2_Re_3 "Complex FFT data (Re, Im) Rx channel 2";
CM_ SG_ 268 Complex2_Im_3 "Complex FFT data (Re, Im) Rx channel 2";
CM_ SG_ 268 Complex1_Re_3 "Complex FFT data (Re, Im) Rx channel 1";
CM_ SG_ 268 Complex1_Im_3 "Complex FFT data (Re, Im) Rx channel 1";
CM_ SG_ 267 StdAzimuth_3 "Standard deviation of azimuth (in °)";
CM_ SG_ 267 PowerDB_3 "Power of detection in db";
CM_ SG_ 267 CoGRange_3 "Center of gravity range (in m)";
CM_ SG_ 267 CoGDoppler_3 "Center of gravity Doppler (in m/s)";
CM_ SG_ 267 Azimuth_3 "Azimuth angle of detection (in degree in driving direction coordinate system)";
CM_ SG_ 266 WRange10DB_3 "10 dB width of detection in range dimension (in m)";
CM_ SG_ 266 WDoppler10DB_3 "10 dB width of detection in Doppler dimension (in m/s)";
CM_ SG_ 266 ValidXBeamIndex_3 "Corresponding Index of in detection list of other beam";
CM_ SG_ 266 ValidXBeam_3 "Validated by detection in other beam/measurement";
CM_ SG_ 266 StdRange_3 "Standard deviation of range measurement (m)";
CM_ SG_ 266 StdDoppler_3 "Standard deviation of Doppler measurement (in m/s)";
CM_ SG_ 266 NoInfrastructure_3 "Target is moving (with high confidence)";
CM_ SG_ 266 Infrastructure_3 "Target is stationary (infrastructure)";
CM_ SG_ 413 Complex4_Re_39 "Complex FFT data (Re, Im) Rx channel 4";
CM_ SG_ 413 Complex4_Im_39 "Complex FFT data (Re, Im) Rx channel 4";
CM_ SG_ 413 Complex3_Re_39 "Complex FFT data (Re, Im) Rx channel 3";
CM_ SG_ 413 Complex3_Im_39 "Complex FFT data (Re, Im) Rx channel 3";
CM_ SG_ 412 Complex2_Re_39 "Complex FFT data (Re, Im) Rx channel 2";
CM_ SG_ 412 Complex2_Im_39 "Complex FFT data (Re, Im) Rx channel 2";
CM_ SG_ 412 Complex1_Re_39 "Complex FFT data (Re, Im) Rx channel 1";
CM_ SG_ 412 Complex1_Im_39 "Complex FFT data (Re, Im) Rx channel 1";
CM_ SG_ 411 StdAzimuth_39 "Standard deviation of azimuth (in °)";
CM_ SG_ 411 PowerDB_39 "Power of detection in db";
CM_ SG_ 411 CoGRange_39 "Center of gravity range (in m)";
CM_ SG_ 411 CoGDoppler_39 "Center of gravity Doppler (in m/s)";
CM_ SG_ 411 Azimuth_39 "Azimuth angle of detection (in degree in driving direction coordinate system)";
CM_ SG_ 410 WRange10DB_39 "10 dB width of detection in range dimension (in m)";
CM_ SG_ 410 WDoppler10DB_39 "10 dB width of detection in Doppler dimension (in m/s)";
CM_ SG_ 410 ValidXBeamIndex_39 "Corresponding Index of in detection list of other beam";
CM_ SG_ 410 ValidXBeam_39 "Validated by detection in other beam/measurement";
CM_ SG_ 410 StdRange_39 "Standard deviation of range measurement (m)";
CM_ SG_ 410 StdDoppler_39 "Standard deviation of Doppler measurement (in m/s)";
CM_ SG_ 410 NoInfrastructure_39 "Target is moving (with high confidence)";
CM_ SG_ 410 Infrastructure_39 "Target is stationary (infrastructure)";
CM_ SG_ 409 Complex4_Re_38 "Complex FFT data (Re, Im) Rx channel 4";
CM_ SG_ 409 Complex4_Im_38 "Complex FFT data (Re, Im) Rx channel 4";
CM_ SG_ 409 Complex3_Re_38 "Complex FFT data (Re, Im) Rx channel 3";
CM_ SG_ 409 Complex3_Im_38 "Complex FFT data (Re, Im) Rx channel 3";
CM_ SG_ 408 Complex2_Re_38 "Complex FFT data (Re, Im) Rx channel 2";
CM_ SG_ 408 Complex2_Im_38 "Complex FFT data (Re, Im) Rx channel 2";
CM_ SG_ 408 Complex1_Re_38 "Complex FFT data (Re, Im) Rx channel 1";
CM_ SG_ 408 Complex1_Im_38 "Complex FFT data (Re, Im) Rx channel 1";
CM_ SG_ 407 StdAzimuth_38 "Standard deviation of azimuth (in °)";
CM_ SG_ 407 PowerDB_38 "Power of detection in db";
CM_ SG_ 407 CoGRange_38 "Center of gravity range (in m)";
CM_ SG_ 407 CoGDoppler_38 "Center of gravity Doppler (in m/s)";
CM_ SG_ 407 Azimuth_38 "Azimuth angle of detection (in degree in driving direction coordinate system)";
CM_ SG_ 406 WRange10DB_38 "10 dB width of detection in range dimension (in m)";
CM_ SG_ 406 WDoppler10DB_38 "10 dB width of detection in Doppler dimension (in m/s)";
CM_ SG_ 406 ValidXBeamIndex_38 "Corresponding Index of in detection list of other beam";
CM_ SG_ 406 ValidXBeam_38 "Validated by detection in other beam/measurement";
CM_ SG_ 406 StdRange_38 "Standard deviation of range measurement (m)";
CM_ SG_ 406 StdDoppler_38 "Standard deviation of Doppler measurement (in m/s)";
CM_ SG_ 406 NoInfrastructure_38 "Target is moving (with high confidence)";
CM_ SG_ 406 Infrastructure_38 "Target is stationary (infrastructure)";
CM_ SG_ 405 Complex4_Re_37 "Complex FFT data (Re, Im) Rx channel 4";
CM_ SG_ 405 Complex4_Im_37 "Complex FFT data (Re, Im) Rx channel 4";
CM_ SG_ 405 Complex3_Re_37 "Complex FFT data (Re, Im) Rx channel 3";
CM_ SG_ 405 Complex3_Im_37 "Complex FFT data (Re, Im) Rx channel 3";
CM_ SG_ 404 Complex2_Re_37 "Complex FFT data (Re, Im) Rx channel 2";
CM_ SG_ 404 Complex2_Im_37 "Complex FFT data (Re, Im) Rx channel 2";
CM_ SG_ 404 Complex1_Re_37 "Complex FFT data (Re, Im) Rx channel 1";
CM_ SG_ 404 Complex1_Im_37 "Complex FFT data (Re, Im) Rx channel 1";
CM_ SG_ 403 StdAzimuth_37 "Standard deviation of azimuth (in °)";
CM_ SG_ 403 PowerDB_37 "Power of detection in db";
CM_ SG_ 403 CoGRange_37 "Center of gravity range (in m)";
CM_ SG_ 403 CoGDoppler_37 "Center of gravity Doppler (in m/s)";
CM_ SG_ 403 Azimuth_37 "Azimuth angle of detection (in degree in driving direction coordinate system)";
CM_ SG_ 402 WRange10DB_37 "10 dB width of detection in range dimension (in m)";
CM_ SG_ 402 WDoppler10DB_37 "10 dB width of detection in Doppler dimension (in m/s)";
CM_ SG_ 402 ValidXBeamIndex_37 "Corresponding Index of in detection list of other beam";
CM_ SG_ 402 ValidXBeam_37 "Validated by detection in other beam/measurement";
CM_ SG_ 402 StdRange_37 "Standard deviation of range measurement (m)";
CM_ SG_ 402 StdDoppler_37 "Standard deviation of Doppler measurement (in m/s)";
CM_ SG_ 402 NoInfrastructure_37 "Target is moving (with high confidence)";
CM_ SG_ 402 Infrastructure_37 "Target is stationary (infrastructure)";
CM_ SG_ 401 Complex4_Re_36 "Complex FFT data (Re, Im) Rx channel 4";
CM_ SG_ 401 Complex4_Im_36 "Complex FFT data (Re, Im) Rx channel 4";
CM_ SG_ 401 Complex3_Re_36 "Complex FFT data (Re, Im) Rx channel 3";
CM_ SG_ 401 Complex3_Im_36 "Complex FFT data (Re, Im) Rx channel 3";
CM_ SG_ 400 Complex2_Re_36 "Complex FFT data (Re, Im) Rx channel 2";
CM_ SG_ 400 Complex2_Im_36 "Complex FFT data (Re, Im) Rx channel 2";
CM_ SG_ 400 Complex1_Re_36 "Complex FFT data (Re, Im) Rx channel 1";
CM_ SG_ 400 Complex1_Im_36 "Complex FFT data (Re, Im) Rx channel 1";
CM_ SG_ 399 StdAzimuth_36 "Standard deviation of azimuth (in °)";
CM_ SG_ 399 PowerDB_36 "Power of detection in db";
CM_ SG_ 399 CoGRange_36 "Center of gravity range (in m)";
CM_ SG_ 399 CoGDoppler_36 "Center of gravity Doppler (in m/s)";
CM_ SG_ 399 Azimuth_36 "Azimuth angle of detection (in degree in driving direction coordinate system)";
CM_ SG_ 398 WRange10DB_36 "10 dB width of detection in range dimension (in m)";
CM_ SG_ 398 WDoppler10DB_36 "10 dB width of detection in Doppler dimension (in m/s)";
CM_ SG_ 398 ValidXBeamIndex_36 "Corresponding Index of in detection list of other beam";
CM_ SG_ 398 ValidXBeam_36 "Validated by detection in other beam/measurement";
CM_ SG_ 398 StdRange_36 "Standard deviation of range measurement (m)";
CM_ SG_ 398 StdDoppler_36 "Standard deviation of Doppler measurement (in m/s)";
CM_ SG_ 398 NoInfrastructure_36 "Target is moving (with high confidence)";
CM_ SG_ 398 Infrastructure_36 "Target is stationary (infrastructure)";
CM_ SG_ 397 Complex4_Re_35 "Complex FFT data (Re, Im) Rx channel 4";
CM_ SG_ 397 Complex4_Im_35 "Complex FFT data (Re, Im) Rx channel 4";
CM_ SG_ 397 Complex3_Re_35 "Complex FFT data (Re, Im) Rx channel 3";
CM_ SG_ 397 Complex3_Im_35 "Complex FFT data (Re, Im) Rx channel 3";
CM_ SG_ 396 Complex2_Re_35 "Complex FFT data (Re, Im) Rx channel 2";
CM_ SG_ 396 Complex2_Im_35 "Complex FFT data (Re, Im) Rx channel 2";
CM_ SG_ 396 Complex1_Re_35 "Complex FFT data (Re, Im) Rx channel 1";
CM_ SG_ 396 Complex1_Im_35 "Complex FFT data (Re, Im) Rx channel 1";
CM_ SG_ 395 StdAzimuth_35 "Standard deviation of azimuth (in °)";
CM_ SG_ 395 PowerDB_35 "Power of detection in db";
CM_ SG_ 395 CoGRange_35 "Center of gravity range (in m)";
CM_ SG_ 395 CoGDoppler_35 "Center of gravity Doppler (in m/s)";
CM_ SG_ 395 Azimuth_35 "Azimuth angle of detection (in degree in driving direction coordinate system)";
CM_ SG_ 394 WRange10DB_35 "10 dB width of detection in range dimension (in m)";
CM_ SG_ 394 WDoppler10DB_35 "10 dB width of detection in Doppler dimension (in m/s)";
CM_ SG_ 394 ValidXBeamIndex_35 "Corresponding Index of in detection list of other beam";
CM_ SG_ 394 ValidXBeam_35 "Validated by detection in other beam/measurement";
CM_ SG_ 394 StdRange_35 "Standard deviation of range measurement (m)";
CM_ SG_ 394 StdDoppler_35 "Standard deviation of Doppler measurement (in m/s)";
CM_ SG_ 394 NoInfrastructure_35 "Target is moving (with high confidence)";
CM_ SG_ 394 Infrastructure_35 "Target is stationary (infrastructure)";
CM_ SG_ 393 Complex4_Re_34 "Complex FFT data (Re, Im) Rx channel 4";
CM_ SG_ 393 Complex4_Im_34 "Complex FFT data (Re, Im) Rx channel 4";
CM_ SG_ 393 Complex3_Re_34 "Complex FFT data (Re, Im) Rx channel 3";
CM_ SG_ 393 Complex3_Im_34 "Complex FFT data (Re, Im) Rx channel 3";
CM_ SG_ 392 Complex2_Re_34 "Complex FFT data (Re, Im) Rx channel 2";
CM_ SG_ 392 Complex2_Im_34 "Complex FFT data (Re, Im) Rx channel 2";
CM_ SG_ 392 Complex1_Re_34 "Complex FFT data (Re, Im) Rx channel 1";
CM_ SG_ 392 Complex1_Im_34 "Complex FFT data (Re, Im) Rx channel 1";
CM_ SG_ 391 StdAzimuth_34 "Standard deviation of azimuth (in °)";
CM_ SG_ 391 PowerDB_34 "Power of detection in db";
CM_ SG_ 391 CoGRange_34 "Center of gravity range (in m)";
CM_ SG_ 391 CoGDoppler_34 "Center of gravity Doppler (in m/s)";
CM_ SG_ 391 Azimuth_34 "Azimuth angle of detection (in degree in driving direction coordinate system)";
CM_ SG_ 390 WRange10DB_34 "10 dB width of detection in range dimension (in m)";
CM_ SG_ 390 WDoppler10DB_34 "10 dB width of detection in Doppler dimension (in m/s)";
CM_ SG_ 390 ValidXBeamIndex_34 "Corresponding Index of in detection list of other beam";
CM_ SG_ 390 ValidXBeam_34 "Validated by detection in other beam/measurement";
CM_ SG_ 390 StdRange_34 "Standard deviation of range measurement (m)";
CM_ SG_ 390 StdDoppler_34 "Standard deviation of Doppler measurement (in m/s)";
CM_ SG_ 390 NoInfrastructure_34 "Target is moving (with high confidence)";
CM_ SG_ 390 Infrastructure_34 "Target is stationary (infrastructure)";
CM_ SG_ 389 Complex4_Re_33 "Complex FFT data (Re, Im) Rx channel 4";
CM_ SG_ 389 Complex4_Im_33 "Complex FFT data (Re, Im) Rx channel 4";
CM_ SG_ 389 Complex3_Re_33 "Complex FFT data (Re, Im) Rx channel 3";
CM_ SG_ 389 Complex3_Im_33 "Complex FFT data (Re, Im) Rx channel 3";
CM_ SG_ 388 Complex2_Re_33 "Complex FFT data (Re, Im) Rx channel 2";
CM_ SG_ 388 Complex2_Im_33 "Complex FFT data (Re, Im) Rx channel 2";
CM_ SG_ 388 Complex1_Re_33 "Complex FFT data (Re, Im) Rx channel 1";
CM_ SG_ 388 Complex1_Im_33 "Complex FFT data (Re, Im) Rx channel 1";
CM_ SG_ 387 StdAzimuth_33 "Standard deviation of azimuth (in °)";
CM_ SG_ 387 PowerDB_33 "Power of detection in db";
CM_ SG_ 387 CoGRange_33 "Center of gravity range (in m)";
CM_ SG_ 387 CoGDoppler_33 "Center of gravity Doppler (in m/s)";
CM_ SG_ 387 Azimuth_33 "Azimuth angle of detection (in degree in driving direction coordinate system)";
CM_ SG_ 386 WRange10DB_33 "10 dB width of detection in range dimension (in m)";
CM_ SG_ 386 WDoppler10DB_33 "10 dB width of detection in Doppler dimension (in m/s)";
CM_ SG_ 386 ValidXBeamIndex_33 "Corresponding Index of in detection list of other beam";
CM_ SG_ 386 ValidXBeam_33 "Validated by detection in other beam/measurement";
CM_ SG_ 386 StdRange_33 "Standard deviation of range measurement (m)";
CM_ SG_ 386 StdDoppler_33 "Standard deviation of Doppler measurement (in m/s)";
CM_ SG_ 386 NoInfrastructure_33 "Target is moving (with high confidence)";
CM_ SG_ 386 Infrastructure_33 "Target is stationary (infrastructure)";
CM_ SG_ 385 Complex4_Re_32 "Complex FFT data (Re, Im) Rx channel 4";
CM_ SG_ 385 Complex4_Im_32 "Complex FFT data (Re, Im) Rx channel 4";
CM_ SG_ 385 Complex3_Re_32 "Complex FFT data (Re, Im) Rx channel 3";
CM_ SG_ 385 Complex3_Im_32 "Complex FFT data (Re, Im) Rx channel 3";
CM_ SG_ 384 Complex2_Re_32 "Complex FFT data (Re, Im) Rx channel 2";
CM_ SG_ 384 Complex2_Im_32 "Complex FFT data (Re, Im) Rx channel 2";
CM_ SG_ 384 Complex1_Re_32 "Complex FFT data (Re, Im) Rx channel 1";
CM_ SG_ 384 Complex1_Im_32 "Complex FFT data (Re, Im) Rx channel 1";
CM_ SG_ 383 StdAzimuth_32 "Standard deviation of azimuth (in °)";
CM_ SG_ 383 PowerDB_32 "Power of detection in db";
CM_ SG_ 383 CoGRange_32 "Center of gravity range (in m)";
CM_ SG_ 383 CoGDoppler_32 "Center of gravity Doppler (in m/s)";
CM_ SG_ 383 Azimuth_32 "Azimuth angle of detection (in degree in driving direction coordinate system)";
CM_ SG_ 382 WRange10DB_32 "10 dB width of detection in range dimension (in m)";
CM_ SG_ 382 WDoppler10DB_32 "10 dB width of detection in Doppler dimension (in m/s)";
CM_ SG_ 382 ValidXBeamIndex_32 "Corresponding Index of in detection list of other beam";
CM_ SG_ 382 ValidXBeam_32 "Validated by detection in other beam/measurement";
CM_ SG_ 382 StdRange_32 "Standard deviation of range measurement (m)";
CM_ SG_ 382 StdDoppler_32 "Standard deviation of Doppler measurement (in m/s)";
CM_ SG_ 382 NoInfrastructure_32 "Target is moving (with high confidence)";
CM_ SG_ 382 Infrastructure_32 "Target is stationary (infrastructure)";
CM_ SG_ 381 Complex4_Re_31 "Complex FFT data (Re, Im) Rx channel 4";
CM_ SG_ 381 Complex4_Im_31 "Complex FFT data (Re, Im) Rx channel 4";
CM_ SG_ 381 Complex3_Re_31 "Complex FFT data (Re, Im) Rx channel 3";
CM_ SG_ 381 Complex3_Im_31 "Complex FFT data (Re, Im) Rx channel 3";
CM_ SG_ 380 Complex2_Re_31 "Complex FFT data (Re, Im) Rx channel 2";
CM_ SG_ 380 Complex2_Im_31 "Complex FFT data (Re, Im) Rx channel 2";
CM_ SG_ 380 Complex1_Re_31 "Complex FFT data (Re, Im) Rx channel 1";
CM_ SG_ 380 Complex1_Im_31 "Complex FFT data (Re, Im) Rx channel 1";
CM_ SG_ 379 StdAzimuth_31 "Standard deviation of azimuth (in °)";
CM_ SG_ 379 PowerDB_31 "Power of detection in db";
CM_ SG_ 379 CoGRange_31 "Center of gravity range (in m)";
CM_ SG_ 379 CoGDoppler_31 "Center of gravity Doppler (in m/s)";
CM_ SG_ 379 Azimuth_31 "Azimuth angle of detection (in degree in driving direction coordinate system)";
CM_ SG_ 378 WRange10DB_31 "10 dB width of detection in range dimension (in m)";
CM_ SG_ 378 WDoppler10DB_31 "10 dB width of detection in Doppler dimension (in m/s)";
CM_ SG_ 378 ValidXBeamIndex_31 "Corresponding Index of in detection list of other beam";
CM_ SG_ 378 ValidXBeam_31 "Validated by detection in other beam/measurement";
CM_ SG_ 378 StdRange_31 "Standard deviation of range measurement (m)";
CM_ SG_ 378 StdDoppler_31 "Standard deviation of Doppler measurement (in m/s)";
CM_ SG_ 378 NoInfrastructure_31 "Target is moving (with high confidence)";
CM_ SG_ 378 Infrastructure_31 "Target is stationary (infrastructure)";
CM_ SG_ 377 Complex4_Re_30 "Complex FFT data (Re, Im) Rx channel 4";
CM_ SG_ 377 Complex4_Im_30 "Complex FFT data (Re, Im) Rx channel 4";
CM_ SG_ 377 Complex3_Re_30 "Complex FFT data (Re, Im) Rx channel 3";
CM_ SG_ 377 Complex3_Im_30 "Complex FFT data (Re, Im) Rx channel 3";
CM_ SG_ 376 Complex2_Re_30 "Complex FFT data (Re, Im) Rx channel 2";
CM_ SG_ 376 Complex2_Im_30 "Complex FFT data (Re, Im) Rx channel 2";
CM_ SG_ 376 Complex1_Re_30 "Complex FFT data (Re, Im) Rx channel 1";
CM_ SG_ 376 Complex1_Im_30 "Complex FFT data (Re, Im) Rx channel 1";
CM_ SG_ 375 StdAzimuth_30 "Standard deviation of azimuth (in °)";
CM_ SG_ 375 PowerDB_30 "Power of detection in db";
CM_ SG_ 375 CoGRange_30 "Center of gravity range (in m)";
CM_ SG_ 375 CoGDoppler_30 "Center of gravity Doppler (in m/s)";
CM_ SG_ 375 Azimuth_30 "Azimuth angle of detection (in degree in driving direction coordinate system)";
CM_ SG_ 374 WRange10DB_30 "10 dB width of detection in range dimension (in m)";
CM_ SG_ 374 WDoppler10DB_30 "10 dB width of detection in Doppler dimension (in m/s)";
CM_ SG_ 374 ValidXBeamIndex_30 "Corresponding Index of in detection list of other beam";
CM_ SG_ 374 ValidXBeam_30 "Validated by detection in other beam/measurement";
CM_ SG_ 374 StdRange_30 "Standard deviation of range measurement (m)";
CM_ SG_ 374 StdDoppler_30 "Standard deviation of Doppler measurement (in m/s)";
CM_ SG_ 374 NoInfrastructure_30 "Target is moving (with high confidence)";
CM_ SG_ 374 Infrastructure_30 "Target is stationary (infrastructure)";
CM_ SG_ 265 Complex4_Re_2 "Complex FFT data (Re, Im) Rx channel 4";
CM_ SG_ 265 Complex4_Im_2 "Complex FFT data (Re, Im) Rx channel 4";
CM_ SG_ 265 Complex3_Re_2 "Complex FFT data (Re, Im) Rx channel 3";
CM_ SG_ 265 Complex3_Im_2 "Complex FFT data (Re, Im) Rx channel 3";
CM_ SG_ 264 Complex2_Re_2 "Complex FFT data (Re, Im) Rx channel 2";
CM_ SG_ 264 Complex2_Im_2 "Complex FFT data (Re, Im) Rx channel 2";
CM_ SG_ 264 Complex1_Re_2 "Complex FFT data (Re, Im) Rx channel 1";
CM_ SG_ 264 Complex1_Im_2 "Complex FFT data (Re, Im) Rx channel 1";
CM_ SG_ 263 StdAzimuth_2 "Standard deviation of azimuth (in °)";
CM_ SG_ 263 PowerDB_2 "Power of detection in db";
CM_ SG_ 263 CoGRange_2 "Center of gravity range (in m)";
CM_ SG_ 263 CoGDoppler_2 "Center of gravity Doppler (in m/s)";
CM_ SG_ 263 Azimuth_2 "Azimuth angle of detection (in degree in driving direction coordinate system)";
CM_ SG_ 262 WRange10DB_2 "10 dB width of detection in range dimension (in m)";
CM_ SG_ 262 WDoppler10DB_2 "10 dB width of detection in Doppler dimension (in m/s)";
CM_ SG_ 262 ValidXBeamIndex_2 "Corresponding Index of in detection list of other beam";
CM_ SG_ 262 ValidXBeam_2 "Validated by detection in other beam/measurement";
CM_ SG_ 262 StdRange_2 "Standard deviation of range measurement (m)";
CM_ SG_ 262 StdDoppler_2 "Standard deviation of Doppler measurement (in m/s)";
CM_ SG_ 262 NoInfrastructure_2 "Target is moving (with high confidence)";
CM_ SG_ 262 Infrastructure_2 "Target is stationary (infrastructure)";
CM_ SG_ 373 Complex4_Re_29 "Complex FFT data (Re, Im) Rx channel 4";
CM_ SG_ 373 Complex4_Im_29 "Complex FFT data (Re, Im) Rx channel 4";
CM_ SG_ 373 Complex3_Re_29 "Complex FFT data (Re, Im) Rx channel 3";
CM_ SG_ 373 Complex3_Im_29 "Complex FFT data (Re, Im) Rx channel 3";
CM_ SG_ 372 Complex2_Re_29 "Complex FFT data (Re, Im) Rx channel 2";
CM_ SG_ 372 Complex2_Im_29 "Complex FFT data (Re, Im) Rx channel 2";
CM_ SG_ 372 Complex1_Re_29 "Complex FFT data (Re, Im) Rx channel 1";
CM_ SG_ 372 Complex1_Im_29 "Complex FFT data (Re, Im) Rx channel 1";
CM_ SG_ 371 StdAzimuth_29 "Standard deviation of azimuth (in °)";
CM_ SG_ 371 PowerDB_29 "Power of detection in db";
CM_ SG_ 371 CoGRange_29 "Center of gravity range (in m)";
CM_ SG_ 371 CoGDoppler_29 "Center of gravity Doppler (in m/s)";
CM_ SG_ 371 Azimuth_29 "Azimuth angle of detection (in degree in driving direction coordinate system)";
CM_ SG_ 370 WRange10DB_29 "10 dB width of detection in range dimension (in m)";
CM_ SG_ 370 WDoppler10DB_29 "10 dB width of detection in Doppler dimension (in m/s)";
CM_ SG_ 370 ValidXBeamIndex_29 "Corresponding Index of in detection list of other beam";
CM_ SG_ 370 ValidXBeam_29 "Validated by detection in other beam/measurement";
CM_ SG_ 370 StdRange_29 "Standard deviation of range measurement (m)";
CM_ SG_ 370 StdDoppler_29 "Standard deviation of Doppler measurement (in m/s)";
CM_ SG_ 370 NoInfrastructure_29 "Target is moving (with high confidence)";
CM_ SG_ 370 Infrastructure_29 "Target is stationary (infrastructure)";
CM_ SG_ 369 Complex4_Re_28 "Complex FFT data (Re, Im) Rx channel 4";
CM_ SG_ 369 Complex4_Im_28 "Complex FFT data (Re, Im) Rx channel 4";
CM_ SG_ 369 Complex3_Re_28 "Complex FFT data (Re, Im) Rx channel 3";
CM_ SG_ 369 Complex3_Im_28 "Complex FFT data (Re, Im) Rx channel 3";
CM_ SG_ 368 Complex2_Re_28 "Complex FFT data (Re, Im) Rx channel 2";
CM_ SG_ 368 Complex2_Im_28 "Complex FFT data (Re, Im) Rx channel 2";
CM_ SG_ 368 Complex1_Re_28 "Complex FFT data (Re, Im) Rx channel 1";
CM_ SG_ 368 Complex1_Im_28 "Complex FFT data (Re, Im) Rx channel 1";
CM_ SG_ 367 StdAzimuth_28 "Standard deviation of azimuth (in °)";
CM_ SG_ 367 PowerDB_28 "Power of detection in db";
CM_ SG_ 367 CoGRange_28 "Center of gravity range (in m)";
CM_ SG_ 367 CoGDoppler_28 "Center of gravity Doppler (in m/s)";
CM_ SG_ 367 Azimuth_28 "Azimuth angle of detection (in degree in driving direction coordinate system)";
CM_ SG_ 366 WRange10DB_28 "10 dB width of detection in range dimension (in m)";
CM_ SG_ 366 WDoppler10DB_28 "10 dB width of detection in Doppler dimension (in m/s)";
CM_ SG_ 366 ValidXBeamIndex_28 "Corresponding Index of in detection list of other beam";
CM_ SG_ 366 ValidXBeam_28 "Validated by detection in other beam/measurement";
CM_ SG_ 366 StdRange_28 "Standard deviation of range measurement (m)";
CM_ SG_ 366 StdDoppler_28 "Standard deviation of Doppler measurement (in m/s)";
CM_ SG_ 366 NoInfrastructure_28 "Target is moving (with high confidence)";
CM_ SG_ 366 Infrastructure_28 "Target is stationary (infrastructure)";
CM_ SG_ 365 Complex4_Re_27 "Complex FFT data (Re, Im) Rx channel 4";
CM_ SG_ 365 Complex4_Im_27 "Complex FFT data (Re, Im) Rx channel 4";
CM_ SG_ 365 Complex3_Re_27 "Complex FFT data (Re, Im) Rx channel 3";
CM_ SG_ 365 Complex3_Im_27 "Complex FFT data (Re, Im) Rx channel 3";
CM_ SG_ 364 Complex2_Re_27 "Complex FFT data (Re, Im) Rx channel 2";
CM_ SG_ 364 Complex2_Im_27 "Complex FFT data (Re, Im) Rx channel 2";
CM_ SG_ 364 Complex1_Re_27 "Complex FFT data (Re, Im) Rx channel 1";
CM_ SG_ 364 Complex1_Im_27 "Complex FFT data (Re, Im) Rx channel 1";
CM_ SG_ 363 StdAzimuth_27 "Standard deviation of azimuth (in °)";
CM_ SG_ 363 PowerDB_27 "Power of detection in db";
CM_ SG_ 363 CoGRange_27 "Center of gravity range (in m)";
CM_ SG_ 363 CoGDoppler_27 "Center of gravity Doppler (in m/s)";
CM_ SG_ 363 Azimuth_27 "Azimuth angle of detection (in degree in driving direction coordinate system)";
CM_ SG_ 362 WRange10DB_27 "10 dB width of detection in range dimension (in m)";
CM_ SG_ 362 WDoppler10DB_27 "10 dB width of detection in Doppler dimension (in m/s)";
CM_ SG_ 362 ValidXBeamIndex_27 "Corresponding Index of in detection list of other beam";
CM_ SG_ 362 ValidXBeam_27 "Validated by detection in other beam/measurement";
CM_ SG_ 362 StdRange_27 "Standard deviation of range measurement (m)";
CM_ SG_ 362 StdDoppler_27 "Standard deviation of Doppler measurement (in m/s)";
CM_ SG_ 362 NoInfrastructure_27 "Target is moving (with high confidence)";
CM_ SG_ 362 Infrastructure_27 "Target is stationary (infrastructure)";
CM_ SG_ 361 Complex4_Re_26 "Complex FFT data (Re, Im) Rx channel 4";
CM_ SG_ 361 Complex4_Im_26 "Complex FFT data (Re, Im) Rx channel 4";
CM_ SG_ 361 Complex3_Re_26 "Complex FFT data (Re, Im) Rx channel 3";
CM_ SG_ 361 Complex3_Im_26 "Complex FFT data (Re, Im) Rx channel 3";
CM_ SG_ 360 Complex2_Re_26 "Complex FFT data (Re, Im) Rx channel 2";
CM_ SG_ 360 Complex2_Im_26 "Complex FFT data (Re, Im) Rx channel 2";
CM_ SG_ 360 Complex1_Re_26 "Complex FFT data (Re, Im) Rx channel 1";
CM_ SG_ 360 Complex1_Im_26 "Complex FFT data (Re, Im) Rx channel 1";
CM_ SG_ 359 StdAzimuth_26 "Standard deviation of azimuth (in °)";
CM_ SG_ 359 PowerDB_26 "Power of detection in db";
CM_ SG_ 359 CoGRange_26 "Center of gravity range (in m)";
CM_ SG_ 359 CoGDoppler_26 "Center of gravity Doppler (in m/s)";
CM_ SG_ 359 Azimuth_26 "Azimuth angle of detection (in degree in driving direction coordinate system)";
CM_ SG_ 358 WRange10DB_26 "10 dB width of detection in range dimension (in m)";
CM_ SG_ 358 WDoppler10DB_26 "10 dB width of detection in Doppler dimension (in m/s)";
CM_ SG_ 358 ValidXBeamIndex_26 "Corresponding Index of in detection list of other beam";
CM_ SG_ 358 ValidXBeam_26 "Validated by detection in other beam/measurement";
CM_ SG_ 358 StdRange_26 "Standard deviation of range measurement (m)";
CM_ SG_ 358 StdDoppler_26 "Standard deviation of Doppler measurement (in m/s)";
CM_ SG_ 358 NoInfrastructure_26 "Target is moving (with high confidence)";
CM_ SG_ 358 Infrastructure_26 "Target is stationary (infrastructure)";
CM_ SG_ 357 Complex4_Re_25 "Complex FFT data (Re, Im) Rx channel 4";
CM_ SG_ 357 Complex4_Im_25 "Complex FFT data (Re, Im) Rx channel 4";
CM_ SG_ 357 Complex3_Re_25 "Complex FFT data (Re, Im) Rx channel 3";
CM_ SG_ 357 Complex3_Im_25 "Complex FFT data (Re, Im) Rx channel 3";
CM_ SG_ 356 Complex2_Re_25 "Complex FFT data (Re, Im) Rx channel 2";
CM_ SG_ 356 Complex2_Im_25 "Complex FFT data (Re, Im) Rx channel 2";
CM_ SG_ 356 Complex1_Re_25 "Complex FFT data (Re, Im) Rx channel 1";
CM_ SG_ 356 Complex1_Im_25 "Complex FFT data (Re, Im) Rx channel 1";
CM_ SG_ 355 StdAzimuth_25 "Standard deviation of azimuth (in °)";
CM_ SG_ 355 PowerDB_25 "Power of detection in db";
CM_ SG_ 355 CoGRange_25 "Center of gravity range (in m)";
CM_ SG_ 355 CoGDoppler_25 "Center of gravity Doppler (in m/s)";
CM_ SG_ 355 Azimuth_25 "Azimuth angle of detection (in degree in driving direction coordinate system)";
CM_ SG_ 354 WRange10DB_25 "10 dB width of detection in range dimension (in m)";
CM_ SG_ 354 WDoppler10DB_25 "10 dB width of detection in Doppler dimension (in m/s)";
CM_ SG_ 354 ValidXBeamIndex_25 "Corresponding Index of in detection list of other beam";
CM_ SG_ 354 ValidXBeam_25 "Validated by detection in other beam/measurement";
CM_ SG_ 354 StdRange_25 "Standard deviation of range measurement (m)";
CM_ SG_ 354 StdDoppler_25 "Standard deviation of Doppler measurement (in m/s)";
CM_ SG_ 354 NoInfrastructure_25 "Target is moving (with high confidence)";
CM_ SG_ 354 Infrastructure_25 "Target is stationary (infrastructure)";
CM_ SG_ 353 Complex4_Re_24 "Complex FFT data (Re, Im) Rx channel 4";
CM_ SG_ 353 Complex4_Im_24 "Complex FFT data (Re, Im) Rx channel 4";
CM_ SG_ 353 Complex3_Re_24 "Complex FFT data (Re, Im) Rx channel 3";
CM_ SG_ 353 Complex3_Im_24 "Complex FFT data (Re, Im) Rx channel 3";
CM_ SG_ 352 Complex2_Re_24 "Complex FFT data (Re, Im) Rx channel 2";
CM_ SG_ 352 Complex2_Im_24 "Complex FFT data (Re, Im) Rx channel 2";
CM_ SG_ 352 Complex1_Re_24 "Complex FFT data (Re, Im) Rx channel 1";
CM_ SG_ 352 Complex1_Im_24 "Complex FFT data (Re, Im) Rx channel 1";
CM_ SG_ 351 StdAzimuth_24 "Standard deviation of azimuth (in °)";
CM_ SG_ 351 PowerDB_24 "Power of detection in db";
CM_ SG_ 351 CoGRange_24 "Center of gravity range (in m)";
CM_ SG_ 351 CoGDoppler_24 "Center of gravity Doppler (in m/s)";
CM_ SG_ 351 Azimuth_24 "Azimuth angle of detection (in degree in driving direction coordinate system)";
CM_ SG_ 350 WRange10DB_24 "10 dB width of detection in range dimension (in m)";
CM_ SG_ 350 WDoppler10DB_24 "10 dB width of detection in Doppler dimension (in m/s)";
CM_ SG_ 350 ValidXBeamIndex_24 "Corresponding Index of in detection list of other beam";
CM_ SG_ 350 ValidXBeam_24 "Validated by detection in other beam/measurement";
CM_ SG_ 350 StdRange_24 "Standard deviation of range measurement (m)";
CM_ SG_ 350 StdDoppler_24 "Standard deviation of Doppler measurement (in m/s)";
CM_ SG_ 350 NoInfrastructure_24 "Target is moving (with high confidence)";
CM_ SG_ 350 Infrastructure_24 "Target is stationary (infrastructure)";
CM_ SG_ 349 Complex4_Re_23 "Complex FFT data (Re, Im) Rx channel 4";
CM_ SG_ 349 Complex4_Im_23 "Complex FFT data (Re, Im) Rx channel 4";
CM_ SG_ 349 Complex3_Re_23 "Complex FFT data (Re, Im) Rx channel 3";
CM_ SG_ 349 Complex3_Im_23 "Complex FFT data (Re, Im) Rx channel 3";
CM_ SG_ 348 Complex2_Re_23 "Complex FFT data (Re, Im) Rx channel 2";
CM_ SG_ 348 Complex2_Im_23 "Complex FFT data (Re, Im) Rx channel 2";
CM_ SG_ 348 Complex1_Re_23 "Complex FFT data (Re, Im) Rx channel 1";
CM_ SG_ 348 Complex1_Im_23 "Complex FFT data (Re, Im) Rx channel 1";
CM_ SG_ 347 StdAzimuth_23 "Standard deviation of azimuth (in °)";
CM_ SG_ 347 PowerDB_23 "Power of detection in db";
CM_ SG_ 347 CoGRange_23 "Center of gravity range (in m)";
CM_ SG_ 347 CoGDoppler_23 "Center of gravity Doppler (in m/s)";
CM_ SG_ 347 Azimuth_23 "Azimuth angle of detection (in degree in driving direction coordinate system)";
CM_ SG_ 346 WRange10DB_23 "10 dB width of detection in range dimension (in m)";
CM_ SG_ 346 WDoppler10DB_23 "10 dB width of detection in Doppler dimension (in m/s)";
CM_ SG_ 346 ValidXBeamIndex_23 "Corresponding Index of in detection list of other beam";
CM_ SG_ 346 ValidXBeam_23 "Validated by detection in other beam/measurement";
CM_ SG_ 346 StdRange_23 "Standard deviation of range measurement (m)";
CM_ SG_ 346 StdDoppler_23 "Standard deviation of Doppler measurement (in m/s)";
CM_ SG_ 346 NoInfrastructure_23 "Target is moving (with high confidence)";
CM_ SG_ 346 Infrastructure_23 "Target is stationary (infrastructure)";
CM_ SG_ 345 Complex4_Re_22 "Complex FFT data (Re, Im) Rx channel 4";
CM_ SG_ 345 Complex4_Im_22 "Complex FFT data (Re, Im) Rx channel 4";
CM_ SG_ 345 Complex3_Re_22 "Complex FFT data (Re, Im) Rx channel 3";
CM_ SG_ 345 Complex3_Im_22 "Complex FFT data (Re, Im) Rx channel 3";
CM_ SG_ 344 Complex2_Re_22 "Complex FFT data (Re, Im) Rx channel 2";
CM_ SG_ 344 Complex2_Im_22 "Complex FFT data (Re, Im) Rx channel 2";
CM_ SG_ 344 Complex1_Re_22 "Complex FFT data (Re, Im) Rx channel 1";
CM_ SG_ 344 Complex1_Im_22 "Complex FFT data (Re, Im) Rx channel 1";
CM_ SG_ 343 StdAzimuth_22 "Standard deviation of azimuth (in °)";
CM_ SG_ 343 PowerDB_22 "Power of detection in db";
CM_ SG_ 343 CoGRange_22 "Center of gravity range (in m)";
CM_ SG_ 343 CoGDoppler_22 "Center of gravity Doppler (in m/s)";
CM_ SG_ 343 Azimuth_22 "Azimuth angle of detection (in degree in driving direction coordinate system)";
CM_ SG_ 342 WRange10DB_22 "10 dB width of detection in range dimension (in m)";
CM_ SG_ 342 WDoppler10DB_22 "10 dB width of detection in Doppler dimension (in m/s)";
CM_ SG_ 342 ValidXBeamIndex_22 "Corresponding Index of in detection list of other beam";
CM_ SG_ 342 ValidXBeam_22 "Validated by detection in other beam/measurement";
CM_ SG_ 342 StdRange_22 "Standard deviation of range measurement (m)";
CM_ SG_ 342 StdDoppler_22 "Standard deviation of Doppler measurement (in m/s)";
CM_ SG_ 342 NoInfrastructure_22 "Target is moving (with high confidence)";
CM_ SG_ 342 Infrastructure_22 "Target is stationary (infrastructure)";
CM_ SG_ 341 Complex4_Re_21 "Complex FFT data (Re, Im) Rx channel 4";
CM_ SG_ 341 Complex4_Im_21 "Complex FFT data (Re, Im) Rx channel 4";
CM_ SG_ 341 Complex3_Re_21 "Complex FFT data (Re, Im) Rx channel 3";
CM_ SG_ 341 Complex3_Im_21 "Complex FFT data (Re, Im) Rx channel 3";
CM_ SG_ 340 Complex2_Re_21 "Complex FFT data (Re, Im) Rx channel 2";
CM_ SG_ 340 Complex2_Im_21 "Complex FFT data (Re, Im) Rx channel 2";
CM_ SG_ 340 Complex1_Re_21 "Complex FFT data (Re, Im) Rx channel 1";
CM_ SG_ 340 Complex1_Im_21 "Complex FFT data (Re, Im) Rx channel 1";
CM_ SG_ 339 StdAzimuth_21 "Standard deviation of azimuth (in °)";
CM_ SG_ 339 PowerDB_21 "Power of detection in db";
CM_ SG_ 339 CoGRange_21 "Center of gravity range (in m)";
CM_ SG_ 339 CoGDoppler_21 "Center of gravity Doppler (in m/s)";
CM_ SG_ 339 Azimuth_21 "Azimuth angle of detection (in degree in driving direction coordinate system)";
CM_ SG_ 338 WRange10DB_21 "10 dB width of detection in range dimension (in m)";
CM_ SG_ 338 WDoppler10DB_21 "10 dB width of detection in Doppler dimension (in m/s)";
CM_ SG_ 338 ValidXBeamIndex_21 "Corresponding Index of in detection list of other beam";
CM_ SG_ 338 ValidXBeam_21 "Validated by detection in other beam/measurement";
CM_ SG_ 338 StdRange_21 "Standard deviation of range measurement (m)";
CM_ SG_ 338 StdDoppler_21 "Standard deviation of Doppler measurement (in m/s)";
CM_ SG_ 338 NoInfrastructure_21 "Target is moving (with high confidence)";
CM_ SG_ 338 Infrastructure_21 "Target is stationary (infrastructure)";
CM_ SG_ 337 Complex4_Re_20 "Complex FFT data (Re, Im) Rx channel 4";
CM_ SG_ 337 Complex4_Im_20 "Complex FFT data (Re, Im) Rx channel 4";
CM_ SG_ 337 Complex3_Re_20 "Complex FFT data (Re, Im) Rx channel 3";
CM_ SG_ 337 Complex3_Im_20 "Complex FFT data (Re, Im) Rx channel 3";
CM_ SG_ 336 Complex2_Re_20 "Complex FFT data (Re, Im) Rx channel 2";
CM_ SG_ 336 Complex2_Im_20 "Complex FFT data (Re, Im) Rx channel 2";
CM_ SG_ 336 Complex1_Re_20 "Complex FFT data (Re, Im) Rx channel 1";
CM_ SG_ 336 Complex1_Im_20 "Complex FFT data (Re, Im) Rx channel 1";
CM_ SG_ 335 StdAzimuth_20 "Standard deviation of azimuth (in °)";
CM_ SG_ 335 PowerDB_20 "Power of detection in db";
CM_ SG_ 335 CoGRange_20 "Center of gravity range (in m)";
CM_ SG_ 335 CoGDoppler_20 "Center of gravity Doppler (in m/s)";
CM_ SG_ 335 Azimuth_20 "Azimuth angle of detection (in degree in driving direction coordinate system)";
CM_ SG_ 334 WRange10DB_20 "10 dB width of detection in range dimension (in m)";
CM_ SG_ 334 WDoppler10DB_20 "10 dB width of detection in Doppler dimension (in m/s)";
CM_ SG_ 334 ValidXBeamIndex_20 "Corresponding Index of in detection list of other beam";
CM_ SG_ 334 ValidXBeam_20 "Validated by detection in other beam/measurement";
CM_ SG_ 334 StdRange_20 "Standard deviation of range measurement (m)";
CM_ SG_ 334 StdDoppler_20 "Standard deviation of Doppler measurement (in m/s)";
CM_ SG_ 334 NoInfrastructure_20 "Target is moving (with high confidence)";
CM_ SG_ 334 Infrastructure_20 "Target is stationary (infrastructure)";
CM_ SG_ 261 Complex4_Re_1 "Complex FFT data (Re, Im) Rx channel 4";
CM_ SG_ 261 Complex4_Im_1 "Complex FFT data (Re, Im) Rx channel 4";
CM_ SG_ 261 Complex3_Re_1 "Complex FFT data (Re, Im) Rx channel 3";
CM_ SG_ 261 Complex3_Im_1 "Complex FFT data (Re, Im) Rx channel 3";
CM_ SG_ 260 Complex2_Re_1 "Complex FFT data (Re, Im) Rx channel 2";
CM_ SG_ 260 Complex2_Im_1 "Complex FFT data (Re, Im) Rx channel 2";
CM_ SG_ 260 Complex1_Re_1 "Complex FFT data (Re, Im) Rx channel 1";
CM_ SG_ 260 Complex1_Im_1 "Complex FFT data (Re, Im) Rx channel 1";
CM_ SG_ 259 StdAzimuth_1 "Standard deviation of azimuth (in °)";
CM_ SG_ 259 PowerDB_1 "Power of detection in db";
CM_ SG_ 259 CoGRange_1 "Center of gravity range (in m)";
CM_ SG_ 259 CoGDoppler_1 "Center of gravity Doppler (in m/s)";
CM_ SG_ 259 Azimuth_1 "Azimuth angle of detection (in degree in driving direction coordinate system)";
CM_ SG_ 258 WRange10DB_1 "10 dB width of detection in range dimension (in m)";
CM_ SG_ 258 WDoppler10DB_1 "10 dB width of detection in Doppler dimension (in m/s)";
CM_ SG_ 258 ValidXBeamIndex_1 "Corresponding Index of in detection list of other beam";
CM_ SG_ 258 ValidXBeam_1 "Validated by detection in other beam/measurement";
CM_ SG_ 258 StdRange_1 "Standard deviation of range measurement (m)";
CM_ SG_ 258 StdDoppler_1 "Standard deviation of Doppler measurement (in m/s)";
CM_ SG_ 258 NoInfrastructure_1 "Target is moving (with high confidence)";
CM_ SG_ 258 Infrastructure_1 "Target is stationary (infrastructure)";
CM_ SG_ 333 Complex4_Re_19 "Complex FFT data (Re, Im) Rx channel 4";
CM_ SG_ 333 Complex4_Im_19 "Complex FFT data (Re, Im) Rx channel 4";
CM_ SG_ 333 Complex3_Re_19 "Complex FFT data (Re, Im) Rx channel 3";
CM_ SG_ 333 Complex3_Im_19 "Complex FFT data (Re, Im) Rx channel 3";
CM_ SG_ 332 Complex2_Re_19 "Complex FFT data (Re, Im) Rx channel 2";
CM_ SG_ 332 Complex2_Im_19 "Complex FFT data (Re, Im) Rx channel 2";
CM_ SG_ 332 Complex1_Re_19 "Complex FFT data (Re, Im) Rx channel 1";
CM_ SG_ 332 Complex1_Im_19 "Complex FFT data (Re, Im) Rx channel 1";
CM_ SG_ 331 StdAzimuth_19 "Standard deviation of azimuth (in °)";
CM_ SG_ 331 PowerDB_19 "Power of detection in db";
CM_ SG_ 331 CoGRange_19 "Center of gravity range (in m)";
CM_ SG_ 331 CoGDoppler_19 "Center of gravity Doppler (in m/s)";
CM_ SG_ 331 Azimuth_19 "Azimuth angle of detection (in degree in driving direction coordinate system)";
CM_ SG_ 330 WRange10DB_19 "10 dB width of detection in range dimension (in m)";
CM_ SG_ 330 WDoppler10DB_19 "10 dB width of detection in Doppler dimension (in m/s)";
CM_ SG_ 330 ValidXBeamIndex_19 "Corresponding Index of in detection list of other beam";
CM_ SG_ 330 ValidXBeam_19 "Validated by detection in other beam/measurement";
CM_ SG_ 330 StdRange_19 "Standard deviation of range measurement (m)";
CM_ SG_ 330 StdDoppler_19 "Standard deviation of Doppler measurement (in m/s)";
CM_ SG_ 330 NoInfrastructure_19 "Target is moving (with high confidence)";
CM_ SG_ 330 Infrastructure_19 "Target is stationary (infrastructure)";
CM_ SG_ 329 Complex4_Re_18 "Complex FFT data (Re, Im) Rx channel 4";
CM_ SG_ 329 Complex4_Im_18 "Complex FFT data (Re, Im) Rx channel 4";
CM_ SG_ 329 Complex3_Re_18 "Complex FFT data (Re, Im) Rx channel 3";
CM_ SG_ 329 Complex3_Im_18 "Complex FFT data (Re, Im) Rx channel 3";
CM_ SG_ 328 Complex2_Re_18 "Complex FFT data (Re, Im) Rx channel 2";
CM_ SG_ 328 Complex2_Im_18 "Complex FFT data (Re, Im) Rx channel 2";
CM_ SG_ 328 Complex1_Re_18 "Complex FFT data (Re, Im) Rx channel 1";
CM_ SG_ 328 Complex1_Im_18 "Complex FFT data (Re, Im) Rx channel 1";
CM_ SG_ 327 StdAzimuth_18 "Standard deviation of azimuth (in °)";
CM_ SG_ 327 PowerDB_18 "Power of detection in db";
CM_ SG_ 327 CoGRange_18 "Center of gravity range (in m)";
CM_ SG_ 327 CoGDoppler_18 "Center of gravity Doppler (in m/s)";
CM_ SG_ 327 Azimuth_18 "Azimuth angle of detection (in degree in driving direction coordinate system)";
CM_ SG_ 326 WRange10DB_18 "10 dB width of detection in range dimension (in m)";
CM_ SG_ 326 WDoppler10DB_18 "10 dB width of detection in Doppler dimension (in m/s)";
CM_ SG_ 326 ValidXBeamIndex_18 "Corresponding Index of in detection list of other beam";
CM_ SG_ 326 ValidXBeam_18 "Validated by detection in other beam/measurement";
CM_ SG_ 326 StdRange_18 "Standard deviation of range measurement (m)";
CM_ SG_ 326 StdDoppler_18 "Standard deviation of Doppler measurement (in m/s)";
CM_ SG_ 326 NoInfrastructure_18 "Target is moving (with high confidence)";
CM_ SG_ 326 Infrastructure_18 "Target is stationary (infrastructure)";
CM_ SG_ 325 Complex4_Re_17 "Complex FFT data (Re, Im) Rx channel 4";
CM_ SG_ 325 Complex4_Im_17 "Complex FFT data (Re, Im) Rx channel 4";
CM_ SG_ 325 Complex3_Re_17 "Complex FFT data (Re, Im) Rx channel 3";
CM_ SG_ 325 Complex3_Im_17 "Complex FFT data (Re, Im) Rx channel 3";
CM_ SG_ 324 Complex2_Re_17 "Complex FFT data (Re, Im) Rx channel 2";
CM_ SG_ 324 Complex2_Im_17 "Complex FFT data (Re, Im) Rx channel 2";
CM_ SG_ 324 Complex1_Re_17 "Complex FFT data (Re, Im) Rx channel 1";
CM_ SG_ 324 Complex1_Im_17 "Complex FFT data (Re, Im) Rx channel 1";
CM_ SG_ 323 StdAzimuth_17 "Standard deviation of azimuth (in °)";
CM_ SG_ 323 PowerDB_17 "Power of detection in db";
CM_ SG_ 323 CoGRange_17 "Center of gravity range (in m)";
CM_ SG_ 323 CoGDoppler_17 "Center of gravity Doppler (in m/s)";
CM_ SG_ 323 Azimuth_17 "Azimuth angle of detection (in degree in driving direction coordinate system)";
CM_ SG_ 322 WRange10DB_17 "10 dB width of detection in range dimension (in m)";
CM_ SG_ 322 WDoppler10DB_17 "10 dB width of detection in Doppler dimension (in m/s)";
CM_ SG_ 322 ValidXBeamIndex_17 "Corresponding Index of in detection list of other beam";
CM_ SG_ 322 ValidXBeam_17 "Validated by detection in other beam/measurement";
CM_ SG_ 322 StdRange_17 "Standard deviation of range measurement (m)";
CM_ SG_ 322 StdDoppler_17 "Standard deviation of Doppler measurement (in m/s)";
CM_ SG_ 322 NoInfrastructure_17 "Target is moving (with high confidence)";
CM_ SG_ 322 Infrastructure_17 "Target is stationary (infrastructure)";
CM_ SG_ 321 Complex4_Re_16 "Complex FFT data (Re, Im) Rx channel 4";
CM_ SG_ 321 Complex4_Im_16 "Complex FFT data (Re, Im) Rx channel 4";
CM_ SG_ 321 Complex3_Re_16 "Complex FFT data (Re, Im) Rx channel 3";
CM_ SG_ 321 Complex3_Im_16 "Complex FFT data (Re, Im) Rx channel 3";
CM_ SG_ 320 Complex2_Re_16 "Complex FFT data (Re, Im) Rx channel 2";
CM_ SG_ 320 Complex2_Im_16 "Complex FFT data (Re, Im) Rx channel 2";
CM_ SG_ 320 Complex1_Re_16 "Complex FFT data (Re, Im) Rx channel 1";
CM_ SG_ 320 Complex1_Im_16 "Complex FFT data (Re, Im) Rx channel 1";
CM_ SG_ 319 StdAzimuth_16 "Standard deviation of azimuth (in °)";
CM_ SG_ 319 PowerDB_16 "Power of detection in db";
CM_ SG_ 319 CoGRange_16 "Center of gravity range (in m)";
CM_ SG_ 319 CoGDoppler_16 "Center of gravity Doppler (in m/s)";
CM_ SG_ 319 Azimuth_16 "Azimuth angle of detection (in degree in driving direction coordinate system)";
CM_ SG_ 318 WRange10DB_16 "10 dB width of detection in range dimension (in m)";
CM_ SG_ 318 WDoppler10DB_16 "10 dB width of detection in Doppler dimension (in m/s)";
CM_ SG_ 318 ValidXBeamIndex_16 "Corresponding Index of in detection list of other beam";
CM_ SG_ 318 ValidXBeam_16 "Validated by detection in other beam/measurement";
CM_ SG_ 318 StdRange_16 "Standard deviation of range measurement (m)";
CM_ SG_ 318 StdDoppler_16 "Standard deviation of Doppler measurement (in m/s)";
CM_ SG_ 318 NoInfrastructure_16 "Target is moving (with high confidence)";
CM_ SG_ 318 Infrastructure_16 "Target is stationary (infrastructure)";
CM_ SG_ 317 Complex4_Re_15 "Complex FFT data (Re, Im) Rx channel 4";
CM_ SG_ 317 Complex4_Im_15 "Complex FFT data (Re, Im) Rx channel 4";
CM_ SG_ 317 Complex3_Re_15 "Complex FFT data (Re, Im) Rx channel 3";
CM_ SG_ 317 Complex3_Im_15 "Complex FFT data (Re, Im) Rx channel 3";
CM_ SG_ 316 Complex2_Re_15 "Complex FFT data (Re, Im) Rx channel 2";
CM_ SG_ 316 Complex2_Im_15 "Complex FFT data (Re, Im) Rx channel 2";
CM_ SG_ 316 Complex1_Re_15 "Complex FFT data (Re, Im) Rx channel 1";
CM_ SG_ 316 Complex1_Im_15 "Complex FFT data (Re, Im) Rx channel 1";
CM_ SG_ 315 StdAzimuth_15 "Standard deviation of azimuth (in °)";
CM_ SG_ 315 PowerDB_15 "Power of detection in db";
CM_ SG_ 315 CoGRange_15 "Center of gravity range (in m)";
CM_ SG_ 315 CoGDoppler_15 "Center of gravity Doppler (in m/s)";
CM_ SG_ 315 Azimuth_15 "Azimuth angle of detection (in degree in driving direction coordinate system)";
CM_ SG_ 314 WRange10DB_15 "10 dB width of detection in range dimension (in m)";
CM_ SG_ 314 WDoppler10DB_15 "10 dB width of detection in Doppler dimension (in m/s)";
CM_ SG_ 314 ValidXBeamIndex_15 "Corresponding Index of in detection list of other beam";
CM_ SG_ 314 ValidXBeam_15 "Validated by detection in other beam/measurement";
CM_ SG_ 314 StdRange_15 "Standard deviation of range measurement (m)";
CM_ SG_ 314 StdDoppler_15 "Standard deviation of Doppler measurement (in m/s)";
CM_ SG_ 314 NoInfrastructure_15 "Target is moving (with high confidence)";
CM_ SG_ 314 Infrastructure_15 "Target is stationary (infrastructure)";
CM_ SG_ 313 Complex4_Re_14 "Complex FFT data (Re, Im) Rx channel 4";
CM_ SG_ 313 Complex4_Im_14 "Complex FFT data (Re, Im) Rx channel 4";
CM_ SG_ 313 Complex3_Re_14 "Complex FFT data (Re, Im) Rx channel 3";
CM_ SG_ 313 Complex3_Im_14 "Complex FFT data (Re, Im) Rx channel 3";
CM_ SG_ 312 Complex2_Re_14 "Complex FFT data (Re, Im) Rx channel 2";
CM_ SG_ 312 Complex2_Im_14 "Complex FFT data (Re, Im) Rx channel 2";
CM_ SG_ 312 Complex1_Re_14 "Complex FFT data (Re, Im) Rx channel 1";
CM_ SG_ 312 Complex1_Im_14 "Complex FFT data (Re, Im) Rx channel 1";
CM_ SG_ 311 StdAzimuth_14 "Standard deviation of azimuth (in °)";
CM_ SG_ 311 PowerDB_14 "Power of detection in db";
CM_ SG_ 311 CoGRange_14 "Center of gravity range (in m)";
CM_ SG_ 311 CoGDoppler_14 "Center of gravity Doppler (in m/s)";
CM_ SG_ 311 Azimuth_14 "Azimuth angle of detection (in degree in driving direction coordinate system)";
CM_ SG_ 310 WRange10DB_14 "10 dB width of detection in range dimension (in m)";
CM_ SG_ 310 WDoppler10DB_14 "10 dB width of detection in Doppler dimension (in m/s)";
CM_ SG_ 310 ValidXBeamIndex_14 "Corresponding Index of in detection list of other beam";
CM_ SG_ 310 ValidXBeam_14 "Validated by detection in other beam/measurement";
CM_ SG_ 310 StdRange_14 "Standard deviation of range measurement (m)";
CM_ SG_ 310 StdDoppler_14 "Standard deviation of Doppler measurement (in m/s)";
CM_ SG_ 310 NoInfrastructure_14 "Target is moving (with high confidence)";
CM_ SG_ 310 Infrastructure_14 "Target is stationary (infrastructure)";
CM_ SG_ 309 Complex4_Re_13 "Complex FFT data (Re, Im) Rx channel 4";
CM_ SG_ 309 Complex4_Im_13 "Complex FFT data (Re, Im) Rx channel 4";
CM_ SG_ 309 Complex3_Re_13 "Complex FFT data (Re, Im) Rx channel 3";
CM_ SG_ 309 Complex3_Im_13 "Complex FFT data (Re, Im) Rx channel 3";
CM_ SG_ 308 Complex2_Re_13 "Complex FFT data (Re, Im) Rx channel 2";
CM_ SG_ 308 Complex2_Im_13 "Complex FFT data (Re, Im) Rx channel 2";
CM_ SG_ 308 Complex1_Re_13 "Complex FFT data (Re, Im) Rx channel 1";
CM_ SG_ 308 Complex1_Im_13 "Complex FFT data (Re, Im) Rx channel 1";
CM_ SG_ 307 StdAzimuth_13 "Standard deviation of azimuth (in °)";
CM_ SG_ 307 PowerDB_13 "Power of detection in db";
CM_ SG_ 307 CoGRange_13 "Center of gravity range (in m)";
CM_ SG_ 307 CoGDoppler_13 "Center of gravity Doppler (in m/s)";
CM_ SG_ 307 Azimuth_13 "Azimuth angle of detection (in degree in driving direction coordinate system)";
CM_ SG_ 306 WRange10DB_13 "10 dB width of detection in range dimension (in m)";
CM_ SG_ 306 WDoppler10DB_13 "10 dB width of detection in Doppler dimension (in m/s)";
CM_ SG_ 306 ValidXBeamIndex_13 "Corresponding Index of in detection list of other beam";
CM_ SG_ 306 ValidXBeam_13 "Validated by detection in other beam/measurement";
CM_ SG_ 306 StdRange_13 "Standard deviation of range measurement (m)";
CM_ SG_ 306 StdDoppler_13 "Standard deviation of Doppler measurement (in m/s)";
CM_ SG_ 306 NoInfrastructure_13 "Target is moving (with high confidence)";
CM_ SG_ 306 Infrastructure_13 "Target is stationary (infrastructure)";
CM_ SG_ 305 Complex4_Re_12 "Complex FFT data (Re, Im) Rx channel 4";
CM_ SG_ 305 Complex4_Im_12 "Complex FFT data (Re, Im) Rx channel 4";
CM_ SG_ 305 Complex3_Re_12 "Complex FFT data (Re, Im) Rx channel 3";
CM_ SG_ 305 Complex3_Im_12 "Complex FFT data (Re, Im) Rx channel 3";
CM_ SG_ 304 Complex2_Re_12 "Complex FFT data (Re, Im) Rx channel 2";
CM_ SG_ 304 Complex2_Im_12 "Complex FFT data (Re, Im) Rx channel 2";
CM_ SG_ 304 Complex1_Re_12 "Complex FFT data (Re, Im) Rx channel 1";
CM_ SG_ 304 Complex1_Im_12 "Complex FFT data (Re, Im) Rx channel 1";
CM_ SG_ 303 StdAzimuth_12 "Standard deviation of azimuth (in °)";
CM_ SG_ 303 PowerDB_12 "Power of detection in db";
CM_ SG_ 303 CoGRange_12 "Center of gravity range (in m)";
CM_ SG_ 303 CoGDoppler_12 "Center of gravity Doppler (in m/s)";
CM_ SG_ 303 Azimuth_12 "Azimuth angle of detection (in degree in driving direction coordinate system)";
CM_ SG_ 302 WRange10DB_12 "10 dB width of detection in range dimension (in m)";
CM_ SG_ 302 WDoppler10DB_12 "10 dB width of detection in Doppler dimension (in m/s)";
CM_ SG_ 302 ValidXBeamIndex_12 "Corresponding Index of in detection list of other beam";
CM_ SG_ 302 ValidXBeam_12 "Validated by detection in other beam/measurement";
CM_ SG_ 302 StdRange_12 "Standard deviation of range measurement (m)";
CM_ SG_ 302 StdDoppler_12 "Standard deviation of Doppler measurement (in m/s)";
CM_ SG_ 302 NoInfrastructure_12 "Target is moving (with high confidence)";
CM_ SG_ 302 Infrastructure_12 "Target is stationary (infrastructure)";
CM_ SG_ 301 Complex4_Re_11 "Complex FFT data (Re, Im) Rx channel 4";
CM_ SG_ 301 Complex4_Im_11 "Complex FFT data (Re, Im) Rx channel 4";
CM_ SG_ 301 Complex3_Re_11 "Complex FFT data (Re, Im) Rx channel 3";
CM_ SG_ 301 Complex3_Im_11 "Complex FFT data (Re, Im) Rx channel 3";
CM_ SG_ 300 Complex2_Re_11 "Complex FFT data (Re, Im) Rx channel 2";
CM_ SG_ 300 Complex2_Im_11 "Complex FFT data (Re, Im) Rx channel 2";
CM_ SG_ 300 Complex1_Re_11 "Complex FFT data (Re, Im) Rx channel 1";
CM_ SG_ 300 Complex1_Im_11 "Complex FFT data (Re, Im) Rx channel 1";
CM_ SG_ 299 StdAzimuth_11 "Standard deviation of azimuth (in °)";
CM_ SG_ 299 PowerDB_11 "Power of detection in db";
CM_ SG_ 299 CoGRange_11 "Center of gravity range (in m)";
CM_ SG_ 299 CoGDoppler_11 "Center of gravity Doppler (in m/s)";
CM_ SG_ 299 Azimuth_11 "Azimuth angle of detection (in degree in driving direction coordinate system)";
CM_ SG_ 298 WRange10DB_11 "10 dB width of detection in range dimension (in m)";
CM_ SG_ 298 WDoppler10DB_11 "10 dB width of detection in Doppler dimension (in m/s)";
CM_ SG_ 298 ValidXBeamIndex_11 "Corresponding Index of in detection list of other beam";
CM_ SG_ 298 ValidXBeam_11 "Validated by detection in other beam/measurement";
CM_ SG_ 298 StdRange_11 "Standard deviation of range measurement (m)";
CM_ SG_ 298 StdDoppler_11 "Standard deviation of Doppler measurement (in m/s)";
CM_ SG_ 298 NoInfrastructure_11 "Target is moving (with high confidence)";
CM_ SG_ 298 Infrastructure_11 "Target is stationary (infrastructure)";
CM_ SG_ 297 Complex4_Re_10 "Complex FFT data (Re, Im) Rx channel 4";
CM_ SG_ 297 Complex4_Im_10 "Complex FFT data (Re, Im) Rx channel 4";
CM_ SG_ 297 Complex3_Re_10 "Complex FFT data (Re, Im) Rx channel 3";
CM_ SG_ 297 Complex3_Im_10 "Complex FFT data (Re, Im) Rx channel 3";
CM_ SG_ 296 Complex2_Re_10 "Complex FFT data (Re, Im) Rx channel 2";
CM_ SG_ 296 Complex2_Im_10 "Complex FFT data (Re, Im) Rx channel 2";
CM_ SG_ 296 Complex1_Re_10 "Complex FFT data (Re, Im) Rx channel 1";
CM_ SG_ 296 Complex1_Im_10 "Complex FFT data (Re, Im) Rx channel 1";
CM_ SG_ 295 StdAzimuth_10 "Standard deviation of azimuth (in °)";
CM_ SG_ 295 PowerDB_10 "Power of detection in db";
CM_ SG_ 295 CoGRange_10 "Center of gravity range (in m)";
CM_ SG_ 295 CoGDoppler_10 "Center of gravity Doppler (in m/s)";
CM_ SG_ 295 Azimuth_10 "Azimuth angle of detection (in degree in driving direction coordinate system)";
CM_ SG_ 294 WRange10DB_10 "10 dB width of detection in range dimension (in m)";
CM_ SG_ 294 WDoppler10DB_10 "10 dB width of detection in Doppler dimension (in m/s)";
CM_ SG_ 294 ValidXBeamIndex_10 "Corresponding Index of in detection list of other beam";
CM_ SG_ 294 ValidXBeam_10 "Validated by detection in other beam/measurement";
CM_ SG_ 294 StdRange_10 "Standard deviation of range measurement (m)";
CM_ SG_ 294 StdDoppler_10 "Standard deviation of Doppler measurement (in m/s)";
CM_ SG_ 294 NoInfrastructure_10 "Target is moving (with high confidence)";
CM_ SG_ 294 Infrastructure_10 "Target is stationary (infrastructure)";
CM_ SG_ 1737 Complex4_Re_100 "Complex FFT data (Re, Im) Rx channel 4";
CM_ SG_ 1737 Complex4_Im_100 "Complex FFT data (Re, Im) Rx channel 4";
CM_ SG_ 1737 Complex3_Re_100 "Complex FFT data (Re, Im) Rx channel 3";
CM_ SG_ 1737 Complex3_Im_100 "Complex FFT data (Re, Im) Rx channel 3";
CM_ SG_ 1736 Complex2_Re_100 "Complex FFT data (Re, Im) Rx channel 2";
CM_ SG_ 1736 Complex2_Im_100 "Complex FFT data (Re, Im) Rx channel 2";
CM_ SG_ 1736 Complex1_Re_100 "Complex FFT data (Re, Im) Rx channel 1";
CM_ SG_ 1736 Complex1_Im_100 "Complex FFT data (Re, Im) Rx channel 1";
CM_ SG_ 1735 StdAzimuth_100 "Standard deviation of azimuth (in °)";
CM_ SG_ 1735 PowerDB_100 "Power of detection in db";
CM_ SG_ 1735 CoGRange_100 "Center of gravity range (in m)";
CM_ SG_ 1735 CoGDoppler_100 "Center of gravity Doppler (in m/s)";
CM_ SG_ 1735 Azimuth_100 "Azimuth angle of detection (in degree in driving direction coordinate system)";
CM_ SG_ 1734 WRange10DB_100 "10 dB width of detection in range dimension (in m)";
CM_ SG_ 1734 WDoppler10DB_100 "10 dB width of detection in Doppler dimension (in m/s)";
CM_ SG_ 1734 ValidXBeamIndex_100 "Corresponding Index of in detection list of other beam";
CM_ SG_ 1734 ValidXBeam_100 "Validated by detection in other beam/measurement";
CM_ SG_ 1734 StdRange_100 "Standard deviation of range measurement (m)";
CM_ SG_ 1734 StdDoppler_100 "Standard deviation of Doppler measurement (in m/s)";
CM_ SG_ 1734 NoInfrastructure_100 "Target is moving (with high confidence)";
CM_ SG_ 1734 Infrastructure_100 "Target is stationary (infrastructure)";
CM_ BO_ 1280 "Data container. Please see signal description
The content of these direct CAN messages is controlled by the DSP. There is no interpretation of the data implemented inside the micro controller unit";
CM_ SG_ 1280 Testing_Mode_Options_7_0x500 "Databyte in the container. See value description.";
CM_ SG_ 1280 Testing_Mode_Options_6_0x500 "Databyte in the container. See value description.";
CM_ SG_ 1280 Testing_Mode_Options_5_0x500 "Databyte in the container. See value description.";
CM_ SG_ 1280 Testing_Mode_Options_4_0x500 "Databyte in the container. See value description.";
CM_ SG_ 1280 Testing_Mode_Options_3_0x500 "Databyte in the container. See value description.";
CM_ SG_ 1280 Testing_Mode_Options_2_0x500 "Databyte in the container. See value description.";
CM_ SG_ 1280 Testing_Mode_Options_1_0x500 "  to modify the sensor operating frequency the following data should be send in Test_Mode_ID and Options_1 accordingly 
For Short range (79 GHz) :

For 400 MHz, 0x600 with dlc 8 and data = 0x40 0x02
For 800 MHz, 0x600 with dlc 8 and data = 0x40 0x03
For 1500 MHz, 0x600 with dlc 8 and data = 0x40 0x04

For Long range (77 GHz) :
400 MHz : 0x600 with dlc 8 and data = 0x40 0x00
800 MHz : 0x600 with dlc 8 and data = 0x40 0x01";
CM_ SG_ 1280 Testing_Mode_ID_0x500 "Testing_Mode_ID: Each type of messsage gets a unique id. See value description";
CM_ BO_ 1536 "Data container. Please see signal description";
CM_ SG_ 1536 Testing_Mode_Options_7_0x600 "Databyte in the container. See value description.";
CM_ SG_ 1536 Testing_Mode_Options_6_0x600 "Databyte in the container. See value description.";
CM_ SG_ 1536 Testing_Mode_Options_5_0x600 "Databyte in the container. See value description.";
CM_ SG_ 1536 Testing_Mode_Options_4_0x600 "Databyte in the container. See value description.";
CM_ SG_ 1536 Testing_Mode_Options_3_0x600 "Databyte in the container. See value description.";
CM_ SG_ 1536 Testing_Mode_Options_2_0x600 "Databyte in the container. See value description.";
CM_ SG_ 1536 Testing_Mode_Options_1_0x600 "Databyte in the container. See value description.

";
CM_ SG_ 1536 Testing_Mode_ID_0x600 "Testing_Mode_ID: Each type of messsage gets a unique id. See value description";
CM_ BO_ 1290 "Data container header. Content description inside of the signal descriptions.
The content of these LLST messages is controlled by the DSP. There is no interpretation of the data implemented inside the micro controller unit";
CM_ SG_ 1290 LLST_Data_Header_SubID_1 "LLST_Data_Header_SubID_1: Possible sub id to identify e.g. channel/chirp";
CM_ SG_ 1290 LLST_Data_Header_SubID_0 "LLST_Data_Header_SubID_0: Possible sub id to identify e.g. channel/chirp";
CM_ SG_ 1290 LLST_Data_Header_Mode_ID "Testing_Mode_ID: Each type of messsage gets a unique id. See value description";
CM_ SG_ 1290 LLST_Data_Header_MC8 "LLST_Data_Header_MC8: Major cycle counter modulo 8";
CM_ SG_ 1290 LLST_Data_Header_FrameCounter "LLST_Data_Header_FrameCounter: Each block frame gets a incrementing number to detect any missing LLST_Data_Header_Blocks on SODX side";
CM_ SG_ 1290 LLST_Data_Header_Blocks "LLST_Data_Header_Blocks: Number of LLST_Data_Header_Blocks for the current message type";
CM_ SG_ 1290 LLST_Data_Header_BlockLength "LLST_Data_Header_BlockLength: Number of used words in the current block";
CM_ SG_ 1290 LLST_Data_Header_BlockCounter "LLST_Data_Header_BlockCounter: This counter counts from 0 up to (LLST_Data_Header_Blocks - 1)";
CM_ BO_ 17 "This Message is sent from PC to sensor holding Vehicle data (Speed, LongAccceleration, Lateral Acceleration and Yawrate).
";
CM_ BO_ 16 "This Message is sent from PC to sensor holding gear Info of the vehicle
";
CM_ BO_ 5 "This message is sent by the PC in order to request the Sensors to start the processing, taking into consideration the necessary delay for each sensor.
";
CM_ BO_ 6 "This message should be sent by the PC at initialization (each power cycle), in order to provide the sensor with it location in car.
";
CM_ SG_ 1057 Rol_Mode_Status "This message allows to activate / deactivate the ROL Mode via CAN
";
CM_ BO_ 1049 "Note: Sesnor reply with software version (Message 0x32D) and sensor serial number (Message 0x300)";
CM_ BO_ 1051 "Note: Sesnor reply with software version (Message 0x32D) and sensor serial number (Message 0x300)";
CM_ BO_ 3 "This message is sent by the PC in order to request the Sensors to prepare for syncronization.
";
CM_ BO_ 813 "The transfer occurs on demand.";
CM_ BO_ 768 "The transfer occurs on demand.";
CM_ BO_ 4 "This message is sent by the Sensor in order to inform the PC that it has stopped the processing and it's waiting for the trigger to start the syncronization.
";
CM_ BO_ 7 "This message is sent by the sensor to PC as an acknowledgement that processing has started holding the delay value for the sensor .
";
BA_DEF_ BO_  "GenMsgCycleTime" INT 0 1000000;
BA_DEF_ BO_  "GenMsgSendType" ENUM  "Zyklisch ","Ereignisgesteuert ","dummy ","ZyklischImmer";
BA_DEF_DEF_  "GenMsgCycleTime" 0;
BA_DEF_DEF_  "GenMsgSendType" "";
BA_ "GenMsgSendType" BO_ 271 1;
BA_ "GenMsgSendType" BO_ 270 1;
BA_ "GenMsgSendType" BO_ 453 1;
BA_ "GenMsgSendType" BO_ 452 1;
BA_ "GenMsgSendType" BO_ 451 1;
BA_ "GenMsgSendType" BO_ 450 1;
BA_ "GenMsgSendType" BO_ 449 1;
BA_ "GenMsgSendType" BO_ 448 1;
BA_ "GenMsgSendType" BO_ 447 1;
BA_ "GenMsgSendType" BO_ 446 1;
BA_ "GenMsgSendType" BO_ 445 1;
BA_ "GenMsgSendType" BO_ 444 1;
BA_ "GenMsgSendType" BO_ 443 1;
BA_ "GenMsgSendType" BO_ 442 1;
BA_ "GenMsgSendType" BO_ 441 1;
BA_ "GenMsgSendType" BO_ 440 1;
BA_ "GenMsgSendType" BO_ 439 1;
BA_ "GenMsgSendType" BO_ 438 1;
BA_ "GenMsgSendType" BO_ 437 1;
BA_ "GenMsgSendType" BO_ 436 1;
BA_ "GenMsgSendType" BO_ 435 1;
BA_ "GenMsgSendType" BO_ 434 1;
BA_ "GenMsgSendType" BO_ 433 1;
BA_ "GenMsgSendType" BO_ 432 1;
BA_ "GenMsgSendType" BO_ 431 1;
BA_ "GenMsgSendType" BO_ 430 1;
BA_ "GenMsgSendType" BO_ 429 1;
BA_ "GenMsgSendType" BO_ 428 1;
BA_ "GenMsgSendType" BO_ 427 1;
BA_ "GenMsgSendType" BO_ 426 1;
BA_ "GenMsgSendType" BO_ 425 1;
BA_ "GenMsgSendType" BO_ 424 1;
BA_ "GenMsgSendType" BO_ 423 1;
BA_ "GenMsgSendType" BO_ 422 1;
BA_ "GenMsgSendType" BO_ 421 1;
BA_ "GenMsgSendType" BO_ 420 1;
BA_ "GenMsgSendType" BO_ 419 1;
BA_ "GenMsgSendType" BO_ 418 1;
BA_ "GenMsgSendType" BO_ 417 1;
BA_ "GenMsgSendType" BO_ 416 1;
BA_ "GenMsgSendType" BO_ 415 1;
BA_ "GenMsgSendType" BO_ 414 1;
BA_ "GenMsgSendType" BO_ 269 1;
BA_ "GenMsgSendType" BO_ 268 1;
BA_ "GenMsgSendType" BO_ 267 1;
BA_ "GenMsgSendType" BO_ 266 1;
BA_ "GenMsgSendType" BO_ 413 1;
BA_ "GenMsgSendType" BO_ 412 1;
BA_ "GenMsgSendType" BO_ 411 1;
BA_ "GenMsgSendType" BO_ 410 1;
BA_ "GenMsgSendType" BO_ 409 1;
BA_ "GenMsgSendType" BO_ 408 1;
BA_ "GenMsgSendType" BO_ 407 1;
BA_ "GenMsgSendType" BO_ 406 1;
BA_ "GenMsgSendType" BO_ 405 1;
BA_ "GenMsgSendType" BO_ 404 1;
BA_ "GenMsgSendType" BO_ 403 1;
BA_ "GenMsgSendType" BO_ 402 1;
BA_ "GenMsgSendType" BO_ 401 1;
BA_ "GenMsgSendType" BO_ 400 1;
BA_ "GenMsgSendType" BO_ 399 1;
BA_ "GenMsgSendType" BO_ 398 1;
BA_ "GenMsgSendType" BO_ 397 1;
BA_ "GenMsgSendType" BO_ 396 1;
BA_ "GenMsgSendType" BO_ 395 1;
BA_ "GenMsgSendType" BO_ 394 1;
BA_ "GenMsgSendType" BO_ 393 1;
BA_ "GenMsgSendType" BO_ 392 1;
BA_ "GenMsgSendType" BO_ 391 1;
BA_ "GenMsgSendType" BO_ 390 1;
BA_ "GenMsgSendType" BO_ 389 1;
BA_ "GenMsgSendType" BO_ 388 1;
BA_ "GenMsgSendType" BO_ 387 1;
BA_ "GenMsgSendType" BO_ 386 1;
BA_ "GenMsgSendType" BO_ 385 1;
BA_ "GenMsgSendType" BO_ 384 1;
BA_ "GenMsgSendType" BO_ 383 1;
BA_ "GenMsgSendType" BO_ 382 1;
BA_ "GenMsgSendType" BO_ 381 1;
BA_ "GenMsgSendType" BO_ 380 1;
BA_ "GenMsgSendType" BO_ 379 1;
BA_ "GenMsgSendType" BO_ 378 1;
BA_ "GenMsgSendType" BO_ 377 1;
BA_ "GenMsgSendType" BO_ 376 1;
BA_ "GenMsgSendType" BO_ 375 1;
BA_ "GenMsgSendType" BO_ 374 1;
BA_ "GenMsgSendType" BO_ 265 1;
BA_ "GenMsgSendType" BO_ 264 1;
BA_ "GenMsgSendType" BO_ 263 1;
BA_ "GenMsgSendType" BO_ 262 1;
BA_ "GenMsgSendType" BO_ 373 1;
BA_ "GenMsgSendType" BO_ 372 1;
BA_ "GenMsgSendType" BO_ 371 1;
BA_ "GenMsgSendType" BO_ 370 1;
BA_ "GenMsgSendType" BO_ 369 1;
BA_ "GenMsgSendType" BO_ 368 1;
BA_ "GenMsgSendType" BO_ 367 1;
BA_ "GenMsgSendType" BO_ 366 1;
BA_ "GenMsgSendType" BO_ 365 1;
BA_ "GenMsgSendType" BO_ 364 1;
BA_ "GenMsgSendType" BO_ 363 1;
BA_ "GenMsgSendType" BO_ 362 1;
BA_ "GenMsgSendType" BO_ 361 1;
BA_ "GenMsgSendType" BO_ 360 1;
BA_ "GenMsgSendType" BO_ 359 1;
BA_ "GenMsgSendType" BO_ 358 1;
BA_ "GenMsgSendType" BO_ 357 1;
BA_ "GenMsgSendType" BO_ 356 1;
BA_ "GenMsgSendType" BO_ 355 1;
BA_ "GenMsgSendType" BO_ 354 1;
BA_ "GenMsgSendType" BO_ 353 1;
BA_ "GenMsgSendType" BO_ 352 1;
BA_ "GenMsgSendType" BO_ 351 1;
BA_ "GenMsgSendType" BO_ 350 1;
BA_ "GenMsgSendType" BO_ 349 1;
BA_ "GenMsgSendType" BO_ 348 1;
BA_ "GenMsgSendType" BO_ 347 1;
BA_ "GenMsgSendType" BO_ 346 1;
BA_ "GenMsgSendType" BO_ 345 1;
BA_ "GenMsgSendType" BO_ 344 1;
BA_ "GenMsgSendType" BO_ 343 1;
BA_ "GenMsgSendType" BO_ 342 1;
BA_ "GenMsgSendType" BO_ 341 1;
BA_ "GenMsgSendType" BO_ 340 1;
BA_ "GenMsgSendType" BO_ 339 1;
BA_ "GenMsgSendType" BO_ 338 1;
BA_ "GenMsgSendType" BO_ 337 1;
BA_ "GenMsgSendType" BO_ 336 1;
BA_ "GenMsgSendType" BO_ 335 1;
BA_ "GenMsgSendType" BO_ 334 1;
BA_ "GenMsgSendType" BO_ 261 1;
BA_ "GenMsgSendType" BO_ 260 1;
BA_ "GenMsgSendType" BO_ 259 1;
BA_ "GenMsgSendType" BO_ 258 1;
BA_ "GenMsgSendType" BO_ 333 1;
BA_ "GenMsgSendType" BO_ 332 1;
BA_ "GenMsgSendType" BO_ 331 1;
BA_ "GenMsgSendType" BO_ 330 1;
BA_ "GenMsgSendType" BO_ 329 1;
BA_ "GenMsgSendType" BO_ 328 1;
BA_ "GenMsgSendType" BO_ 327 1;
BA_ "GenMsgSendType" BO_ 326 1;
BA_ "GenMsgSendType" BO_ 325 1;
BA_ "GenMsgSendType" BO_ 324 1;
BA_ "GenMsgSendType" BO_ 323 1;
BA_ "GenMsgSendType" BO_ 322 1;
BA_ "GenMsgSendType" BO_ 321 1;
BA_ "GenMsgSendType" BO_ 320 1;
BA_ "GenMsgSendType" BO_ 319 1;
BA_ "GenMsgSendType" BO_ 318 1;
BA_ "GenMsgSendType" BO_ 317 1;
BA_ "GenMsgSendType" BO_ 316 1;
BA_ "GenMsgSendType" BO_ 315 1;
BA_ "GenMsgSendType" BO_ 314 1;
BA_ "GenMsgSendType" BO_ 313 1;
BA_ "GenMsgSendType" BO_ 312 1;
BA_ "GenMsgSendType" BO_ 311 1;
BA_ "GenMsgSendType" BO_ 310 1;
BA_ "GenMsgSendType" BO_ 309 1;
BA_ "GenMsgSendType" BO_ 308 1;
BA_ "GenMsgSendType" BO_ 307 1;
BA_ "GenMsgSendType" BO_ 306 1;
BA_ "GenMsgSendType" BO_ 305 1;
BA_ "GenMsgSendType" BO_ 304 1;
BA_ "GenMsgSendType" BO_ 303 1;
BA_ "GenMsgSendType" BO_ 302 1;
BA_ "GenMsgSendType" BO_ 301 1;
BA_ "GenMsgSendType" BO_ 300 1;
BA_ "GenMsgSendType" BO_ 299 1;
BA_ "GenMsgSendType" BO_ 298 1;
BA_ "GenMsgSendType" BO_ 297 1;
BA_ "GenMsgSendType" BO_ 296 1;
BA_ "GenMsgSendType" BO_ 295 1;
BA_ "GenMsgSendType" BO_ 294 1;
BA_ "GenMsgSendType" BO_ 1737 1;
BA_ "GenMsgSendType" BO_ 1736 1;
BA_ "GenMsgSendType" BO_ 1735 1;
BA_ "GenMsgSendType" BO_ 1734 1;
BA_ "GenMsgSendType" BO_ 2047 1;
BA_ "GenMsgSendType" BO_ 1280 1;
BA_ "GenMsgSendType" BO_ 1536 1;
BA_ "GenMsgSendType" BO_ 1290 1;
BA_ "GenMsgSendType" BO_ 1320 1;
BA_ "GenMsgSendType" BO_ 1319 1;
BA_ "GenMsgSendType" BO_ 1318 1;
BA_ "GenMsgSendType" BO_ 1317 1;
BA_ "GenMsgSendType" BO_ 1316 1;
BA_ "GenMsgSendType" BO_ 1315 1;
BA_ "GenMsgSendType" BO_ 1314 1;
BA_ "GenMsgSendType" BO_ 1313 1;
BA_ "GenMsgSendType" BO_ 1312 1;
BA_ "GenMsgSendType" BO_ 1311 1;
BA_ "GenMsgSendType" BO_ 1310 1;
BA_ "GenMsgSendType" BO_ 1309 1;
BA_ "GenMsgSendType" BO_ 1308 1;
BA_ "GenMsgSendType" BO_ 1307 1;
BA_ "GenMsgSendType" BO_ 1306 1;
BA_ "GenMsgSendType" BO_ 1305 1;
BA_ "GenMsgSendType" BO_ 1304 1;
BA_ "GenMsgSendType" BO_ 1303 1;
BA_ "GenMsgSendType" BO_ 1302 1;
BA_ "GenMsgSendType" BO_ 1301 1;
BA_ "GenMsgSendType" BO_ 1300 1;
BA_ "GenMsgSendType" BO_ 1299 1;
BA_ "GenMsgSendType" BO_ 1298 1;
BA_ "GenMsgSendType" BO_ 1297 1;
BA_ "GenMsgSendType" BO_ 1296 1;
BA_ "GenMsgSendType" BO_ 1295 1;
BA_ "GenMsgSendType" BO_ 1294 1;
BA_ "GenMsgSendType" BO_ 1293 1;
BA_ "GenMsgSendType" BO_ 1292 1;
BA_ "GenMsgSendType" BO_ 1291 1;
BA_ "GenMsgSendType" BO_ 9 1;
BA_ "GenMsgSendType" BO_ 8 1;
BA_ "GenMsgSendType" BO_ 17 1;
BA_ "GenMsgSendType" BO_ 16 1;
BA_ "GenMsgSendType" BO_ 5 1;
BA_ "GenMsgSendType" BO_ 6 1;
BA_ "GenMsgSendType" BO_ 1057 1;
BA_ "GenMsgSendType" BO_ 1049 1;
BA_ "GenMsgSendType" BO_ 1051 1;
BA_ "GenMsgSendType" BO_ 3 1;
BA_ "GenMsgSendType" BO_ 832 1;
BA_ "GenMsgSendType" BO_ 513 1;
BA_ "GenMsgSendType" BO_ 813 1;
BA_ "GenMsgSendType" BO_ 768 1;
BA_ "GenMsgSendType" BO_ 4 1;
BA_ "GenMsgSendType" BO_ 7 1;
VAL_ 1280 Testing_Mode_Options_7_0x500 -12 "Beschreibung für den Wert '0xFFF" -13 "Beschreibung für den Wert '0xFFF" -14 "0x21 TimerValue_HB:(u24 value) T" -15 "0x1A: FineDacHigh_LB: (u16 value" -16 "0x17: (Bit 7 to 4) PT1Width_HN  " ;
VAL_ 1280 Testing_Mode_Options_6_0x500 -13 "0x21 TimerValue_MB:(u24 value) T" -14 "0x1A: FineDacHigh_LB: (u16 value" -15 "0x18: HighFrequency_HB: (u16 val" -16 "0x17: PT1Width_LB: (u12 value) T" ;
VAL_ 1280 Testing_Mode_Options_5_0x500 -13 "0x21 TimerValue_LB:(u24 value) T" -14 "0x1A: FineDacCenter_HB (u16 valu" -15 "0x18: HighFrequency_LB: (u16 val" -16 "0x17: PT0Width_LB: (u12 value) T" ;
VAL_ 1280 Testing_Mode_Options_4_0x500 -10 "0x36: PolyAbs_HB: (float Use a c" -11 "0x35: EirpFrequency_HB: EirpFreq" -12 "0x21:MeasuredFrequency_HB (float" -13 "0x1A: FineDacCenter_LB (u16 valu" -14 "0x18: CenterFrequency_HB:(u16 va" -15 "0x17: PT1Period_LB: (u16 value) " -16 "ALL VALUES HIGHER THAN 0xFFFFFFF" ;
VAL_ 1280 Testing_Mode_Options_3_0x500 -10 "0x36: PolyAbs_MHB: (float Use a " -11 "0x35: EirpFrequency_MHB: EirpFre" -12 "0x21:MeasuredFrequency_MHB (floa" -13 "0x1A: FineDacLow_HB:(u16 value) " -14 "0x18: CenterFrequency_LB:(u16 va" -15 "0x17: PT1Period_LB: (u16 value) " -16 "ALL VALUES HIGHER THAN 0xFFFFFFF" 15 "0x10: MucFftChirp:doppler range " 14 "0x10: MucFftChirp:doppler range " 13 "0x10: MucFftChirp:doppler range " 12 "0x10: MucFftChirp:doppler range " 11 "0x10: MucFftChirp:doppler range " 10 "0x10: MucFftChirp:doppler range " 9 "0x10: MucFftChirp:doppler range " 8 "0x10: MucFftChirp:doppler range " 7 "0x10: MucFftChirp:doppler range " 6 "0x10: MucFftChirp:doppler range " 5 "0x10: MucFftChirp:doppler range " 4 "0x10: MucFftChirp:doppler range " 3 "0x10: MucFftChirp:doppler range " 2 "0x10: MucFftChirp:doppler range " 1 "0x10: MucFftChirp:doppler range " 0 "0x10: MucFftChirp:doppler range " ;
VAL_ 1280 Testing_Mode_Options_2_0x500 -10 "0x36: PolyAbs_MLB: (4Bytes float" -11 "0x35: EirpFrequency_MLB: -1: Cal" -12 "0x21: MeasuredFrequency_MLB:(flo" -13 "0x1A: FineDacLow_LB: (u16) Defin" -14 "0x18: LowFrequency_HB: (u16) Low" -15 "0x17: PT0Period_HB: (u16) Timer " -16 "ALL VALUES HIGHER THAN 0xFFFFFFF" 16 "0x14: HstMode_HB:Pilot tone" 15 "0x10: MucVideoChirp:video chirp " 14 "0x10: MucVideoChirp:video chirp " 13 "0x10: MucVideoChirp:video chirp " 12 "0x10: MucVideoChirp:video chirp " 11 "0x10: MucVideoChirp:video chirp " 10 "0x10: MucVideoChirp:video chirp " 9 "0x10: MucVideoChirp:video chirp " 8 "0x10: MucVideoChirp:video chirp " 7 "0x10: MucVideoChirp:video chirp " 6 "0x10: MucVideoChirp:video chirp " 5 "0x10: MucVideoChirp:video chirp " 4 "0x10: MucVideoChirp:video chirp " 3 "0x10: MucVideoChirp:video chirp " 2 "0x10: MucVideoChirp:video chirp " 1 "0x10: MucVideoChirp:video chirp " 0 "0x10: MucVideoChirp:video chirp " ;
VAL_ 1280 Testing_Mode_Options_1_0x500 -8 "0x21: MeasuredFrequency_LB:(floa" -9 "0x36: PolyAbs_LB: (4Bytes float " -10 "0x35: EirpFrequency_LB: -1: Cali" -11 "0x32: AdditionalCfarOffset: (u8)" -12 "0x1A: CoarseDac: (u8) Defines th" -13 "0x18: LowFrequency_LB: (u16) Low" -14 "0x17: PT0Period_LB: (u16) Timer " -15 "0x15: BpBin: (u8) Selection of f" -16 "ALL VALUES HIGHER THAN 0xFFFFFFF" 255 "0x12: SingleBeamSelector:No swti" 128 "0x14: HstMode_LB:Calibration; 0x" 64 "0x14: Tracked list xy; 0x30: Can" 32 "0x14: HstMode_LB:Not used; 0x30:" 17 "0x10: Beam:Pilote tone 1;" 16 "0x10: Beam:Pilote tone 0; 0x13: " 15 "0x10: Beam:Single beam 6;" 13 "0x10: Beam:Single beam 5;" 12 "0x10: Beam:Single beam 4;" 11 "0x10: Beam:Single beam 3;" 10 "0x10: Beam:Single beam 2; " 9 "0x10: Beam:Single beam 1;" 8 "0x10: Beam:Single beam 0; 0x14: " 7 "0x10: Beam:No beam; 0x15:" 6 "0x10: Beam:Combined beam 6;" 5 "0x10: Beam:Combined beam 5; 0x1D" 4 "0x10: Beam:Combined beam 4; 0x14" 3 "0x10: Beam:Combined beam 3; 0x1B" 2 "0x10: Beam:Combined beam 2; 0x14" 1 "0x10: Beam:Combined beam 1; 0x14" 0 "0x10: Beam:Combined beam 0; 0x12" ;
VAL_ 1280 Testing_Mode_ID_0x500 54 "definition of the quadratic valu" 53 "definition of the calibrated EIR" 50 "addition of a value to the CFAR " 49 "activation of different DSP test" 48 "activation of different CAN bloc" 33 "measured EIRP frequency" 29 "definition of the calibration mo" 27 "control of the main statemachine" 26 "settings of the coarse and fine " 24 "settings of the low, center and " 23 "settings of the pilot tone timer" 21 "selection of the fft bin for the" 20 "activation of different HST mode" 18 "selection of the beam in the sin" 16 "selection of the beam, video chi" ;
VAL_ 1536 Testing_Mode_Options_7_0x600 -12 "Beschreibung für den Wert '0xFFF" -13 "Beschreibung für den Wert '0xFFF" -14 "0x21 TimerValue_HB:(u24 value) T" -15 "0x1A: FineDacHigh_LB: (u16 value" -16 "0x17: (Bit 7 to 4) PT1Width_HN  " ;
VAL_ 1536 Testing_Mode_Options_6_0x600 -13 "0x21 TimerValue_MB:(u24 value) T" -14 "0x1A: FineDacHigh_LB: (u16 value" -15 "0x18: HighFrequency_HB: (u16 val" -16 "0x17: PT1Width_LB: (u12 value) T" ;
VAL_ 1536 Testing_Mode_Options_5_0x600 -13 "0x21 TimerValue_LB:(u24 value) T" -14 "0x1A: FineDacCenter_HB (u16 valu" -15 "0x18: HighFrequency_LB: (u16 val" -16 "0x17: PT0Width_LB: (u12 value) T" ;
VAL_ 1536 Testing_Mode_Options_4_0x600 -10 "0x36: PolyAbs_HB: (float Use a c" -11 "0x35: EirpFrequency_HB: EirpFreq" -12 "0x21:MeasuredFrequency_HB (float" -13 "0x1A: FineDacCenter_LB (u16 valu" -14 "0x18: CenterFrequency_HB:(u16 va" -15 "0x17: PT1Period_LB: (u16 value) " -16 "ALL VALUES HIGHER THAN 0xFFFFFFF" ;
VAL_ 1536 Testing_Mode_Options_3_0x600 -10 "0x36: PolyAbs_MHB: (float Use a " -11 "0x35: EirpFrequency_MHB: EirpFre" -12 "0x21:MeasuredFrequency_MHB (floa" -13 "0x1A: FineDacLow_HB:(u16 value) " -14 "0x18: CenterFrequency_LB:(u16 va" -15 "0x17: PT1Period_LB: (u16 value) " -16 "ALL VALUES HIGHER THAN 0xFFFFFFF" 15 "0x10: MucFftChirp:doppler range " 14 "0x10: MucFftChirp:doppler range " 13 "0x10: MucFftChirp:doppler range " 12 "0x10: MucFftChirp:doppler range " 11 "0x10: MucFftChirp:doppler range " 10 "0x10: MucFftChirp:doppler range " 9 "0x10: MucFftChirp:doppler range " 8 "0x10: MucFftChirp:doppler range " 7 "0x10: MucFftChirp:doppler range " 6 "0x10: MucFftChirp:doppler range " 5 "0x10: MucFftChirp:doppler range " 4 "0x10: MucFftChirp:doppler range " 3 "0x10: MucFftChirp:doppler range " 2 "0x10: MucFftChirp:doppler range " 1 "0x10: MucFftChirp:doppler range " 0 "0x10: MucFftChirp:doppler range " ;
VAL_ 1536 Testing_Mode_Options_2_0x600 -10 "0x36: PolyAbs_MLB: (4Bytes float" -11 "0x35: EirpFrequency_MLB: -1: Cal" -12 "0x21: MeasuredFrequency_MLB:(flo" -13 "0x1A: FineDacLow_LB: (u16) Defin" -14 "0x18: LowFrequency_HB: (u16) Low" -15 "0x17: PT0Period_HB: (u16) Timer " -16 "ALL VALUES HIGHER THAN 0xFFFFFFF" 16 "0x14: HstMode_HB:Pilot tone" 15 "0x10: MucVideoChirp:video chirp " 14 "0x10: MucVideoChirp:video chirp " 13 "0x10: MucVideoChirp:video chirp " 12 "0x10: MucVideoChirp:video chirp " 11 "0x10: MucVideoChirp:video chirp " 10 "0x10: MucVideoChirp:video chirp " 9 "0x10: MucVideoChirp:video chirp " 8 "0x10: MucVideoChirp:video chirp " 7 "0x10: MucVideoChirp:video chirp " 6 "0x10: MucVideoChirp:video chirp " 5 "0x10: MucVideoChirp:video chirp " 4 "0x10: MucVideoChirp:video chirp " 3 "0x10: MucVideoChirp:video chirp " 2 "0x10: MucVideoChirp:video chirp " 1 "0x10: MucVideoChirp:video chirp " 0 "0x10: MucVideoChirp:video chirp " ;
VAL_ 1536 Testing_Mode_Options_1_0x600 -8 "0x21: MeasuredFrequency_LB:(floa" -9 "0x36: PolyAbs_LB: (4Bytes float " -10 "0x35: EirpFrequency_LB: -1: Cali" -11 "0x32: AdditionalCfarOffset: (u8)" -12 "0x1A: CoarseDac: (u8) Defines th" -13 "0x18: LowFrequency_LB: (u16) Low" -14 "0x17: PT0Period_LB: (u16) Timer " -15 "0x15: BpBin: (u8) Selection of f" -16 "ALL VALUES HIGHER THAN 0xFFFFFFF" 255 "0x12: SingleBeamSelector:No swti" 128 "0x14: HstMode_LB:Calibration; 0x" 64 "0x14: Tracked list xy; 0x30: Can" 32 "0x14: HstMode_LB:Not used; 0x30:" 17 "0x10: Beam:Pilote tone 1;" 16 "0x10: Beam:Pilote tone 0; 0x13: " 15 "0x10: Beam:Single beam 6;" 13 "0x10: Beam:Single beam 5;" 12 "0x10: Beam:Single beam 4;" 11 "0x10: Beam:Single beam 3;" 10 "0x10: Beam:Single beam 2; " 9 "0x10: Beam:Single beam 1;" 8 "0x10: Beam:Single beam 0; 0x14: " 7 "0x10: Beam:No beam; 0x15:" 6 "0x10: Beam:Combined beam 6;" 5 "0x10: Beam:Combined beam 5; 0x1D" 4 "0x10: Beam:Combined beam 4; 0x14" 3 "0x10: Beam:Combined beam 3; 0x1B" 2 "0x10: Beam:Combined beam 2; 0x14" 1 "0x10: Beam:Combined beam 1; 0x14" 0 "0x10: Beam:Combined beam 0; 0x12" ;
VAL_ 1536 Testing_Mode_ID_0x600 64 "Change Operating Frequency " 54 "definition of the quadratic valu" 53 "definition of the calibrated EIR" 50 "addition of a value to the CFAR " 49 "activation of different DSP test" 48 "activation of different CAN bloc" 33 "measured EIRP frequency" 29 "definition of the calibration mo" 27 "control of the main statemachine" 26 "settings of the coarse and fine " 24 "settings of the low, center and " 23 "settings of the pilot tone timer" 21 "selection of the fft bin for the" 20 "activation of different HST mode" 18 "selection of the beam in the sin" 16 "selection of the beam, video chi" ;
VAL_ 1290 LLST_Data_Header_SubID_1 -2 "The content of the payload is:

" -3 "The content of the header is:

T" -4 "BEAM PATTERN MODE: This LLST_Dat" -5 "The content of the payload is:

" -6 "The content of the header is:

T" -7 "COMPLEX FFT MODE: This LLST_Data" -8 "float MeasuredHighFreq;

  float" -9 "struct FreqCalibBlock

{

  u16 " -10 "The content of the header is:

T" -11 "FREQUENCY CALIBRATION MODE: This" -12 "Testing_Mode_ID: 2

LLST_Data_He" -13 "FFT MODE: This LLST_Data_Header_" -14 "Testing_Mode_ID: 1

LLST_Data_He" -15 "VIDEO MODE: This LLST_Data_Heade" -16 "ALL VALUES HIGHER THAN 0xFFFFFFF" ;
VAL_ 1290 LLST_Data_Header_SubID_0 -2 "The content of the payload is:

" -3 "The content of the header is:

T" -4 "BEAM PATTERN MODE: This LLST_Dat" -5 "The content of the payload is:

" -6 "The content of the header is:

T" -7 "COMPLEX FFT MODE: This LLST_Data" -8 "float MeasuredHighFreq;

  float" -9 "struct FreqCalibBlock

{

  u16 " -10 "The content of the header is:

T" -11 "FREQUENCY CALIBRATION MODE: This" -12 "Testing_Mode_ID: 2

LLST_Data_He" -13 "FFT MODE: This LLST_Data_Header_" -14 "Testing_Mode_ID: 1

LLST_Data_He" -15 "VIDEO MODE: This LLST_Data_Heade" -16 "ALL VALUES HIGHER THAN 0xFFFFFFF" ;
VAL_ 1290 LLST_Data_Header_Mode_ID 268435454 "The content of the payload is:

" 268435453 "The content of the header is:

L" 268435452 "BEAM PATTERN MODE: This LLST_Dat" 268435451 "The content of the payload is:

" 268435450 "The content of the header is:

T" 268435449 "COMPLEX FFT MODE: This LLST_Data" 268435448 "  float MeasuredHighFreq;

  flo" 268435447 "struct FreqCalibBlock

{

  u16 " 268435446 "The content of the header is:

T" 268435445 "FREQUENCY CALIBRATION MODE: This" 268435444 "Testing_Mode_ID: 2

LLST_Data_He" 268435443 "FFT MODE: This LLST_Data_Header_" 268435442 "Testing_Mode_ID: 1

LLST_Data_He" 268435441 "VIDEO MODE: This LLST_Data_Heade" 268435440 "ALL VALUES HIGHER THAN 0xFFFFFFF" 7 "beam pattern mode (see value des" 4 "complex fft mode (see value desc" 3 "frequency calibration mode (see " 2 "fft mode (see value description " 1 "video mode (see value descriptio" ;
VAL_ 1290 LLST_Data_Header_MC8 -2 "The content of the payload is:

" -3 "The content of the header is:

T" -4 "BEAM PATTERN MODE: This LLST_Dat" -5 "The content of the payload is:

" -6 "The content of the header is:

T" -7 "COMPLEX FFT MODE: This LLST_Data" -8 "float MeasuredHighFreq;

  float" -9 "struct FreqCalibBlock

{

  u16 " -10 "The content of the header is:

T" -11 "FREQUENCY CALIBRATION MODE: This" -12 "Testing_Mode_ID: 2

LLST_Data_He" -13 "FFT MODE: This LLST_Data_Header_" -14 "Testing_Mode_ID: 1

LLST_Data_He" -15 "VIDEO MODE: This LLST_Data_Heade" -16 "ALL VALUES HIGHER THAN 0xFFFFFFF" ;
VAL_ 1290 LLST_Data_Header_FrameCounter -2 "The content of the payload is:

" -3 "The content of the header is:

T" -4 "BEAM PATTERN MODE: This LLST_Dat" -5 "The content of the payload is:

" -6 "The content of the header is:

T" -7 "COMPLEX FFT MODE: This LLST_Data" -8 "float MeasuredHighFreq;

  float" -9 "struct FreqCalibBlock

{

  u16 " -10 "The content of the header is:

T" -11 "FREQUENCY CALIBRATION MODE: This" -12 "Testing_Mode_ID: 2

LLST_Data_He" -13 "FFT MODE: This LLST_Data_Header_" -14 "Testing_Mode_ID: 1

LLST_Data_He" -15 "VIDEO MODE: This LLST_Data_Heade" -16 "ALL VALUES HIGHER THAN 0xFFFFFFF" ;
VAL_ 1290 LLST_Data_Header_Blocks -2 "The content of the payload is:

" -3 "The content of the header is:

T" -4 "BEAM PATTERN MODE: This LLST_Dat" -5 "The content of the payload is:

" -6 "The content of the header is:

T" -7 "COMPLEX FFT MODE: This LLST_Data" -8 "float MeasuredHighFreq;

  float" -9 "struct FreqCalibBlock

{

  u16 " -10 "The content of the header is:

T" -11 "FREQUENCY CALIBRATION MODE: This" -12 "Testing_Mode_ID: 2

LLST_Data_He" -13 "FFT MODE: This LLST_Data_Header_" -14 "Testing_Mode_ID: 1

LLST_Data_He" -15 "VIDEO MODE: This LLST_Data_Heade" -16 "ALL VALUES HIGHER THAN 0xFFFFFFF" ;
VAL_ 1290 LLST_Data_Header_BlockLength -2 "The content of the payload is:

" -3 "The content of the header is:

T" -4 "BEAM PATTERN MODE: This LLST_Dat" -5 "The content of the payload is:

" -6 "The content of the header is:

T" -7 "COMPLEX FFT MODE: This LLST_Data" -8 "float MeasuredHighFreq;

  float" -9 "struct FreqCalibBlock

{

  u16 " -10 "The content of the header is:

T" -11 "FREQUENCY CALIBRATION MODE: This" -12 "Testing_Mode_ID: 2

LLST_Data_He" -13 "FFT MODE: This LLST_Data_Header_" -14 "Testing_Mode_ID: 1

LLST_Data_He" -15 "VIDEO MODE: This LLST_Data_Heade" -16 "ALL VALUES HIGHER THAN 0xFFFFFFF" ;
VAL_ 1290 LLST_Data_Header_BlockCounter -2 "The content of the payload is:

" -3 "The content of the header is:

T" -4 "BEAM PATTERN MODE: This LLST_Dat" -5 "The content of the payload is:

" -6 "The content of the header is:

T" -7 "COMPLEX FFT MODE: This LLST_Data" -8 "float MeasuredHighFreq;

  float" -9 "struct FreqCalibBlock

{

  u16 " -10 "The content of the header is:

T" -11 "FREQUENCY CALIBRATION MODE: This" -12 "Testing_Mode_ID: 2

LLST_Data_He" -13 "FFT MODE: This LLST_Data_Header_" -14 "Testing_Mode_ID: 1

LLST_Data_He" -15 "VIDEO MODE: This LLST_Data_Heade" -16 "ALL VALUES HIGHER THAN 0xFFFFFFF" ;
VAL_ 16 GearPosition 15 "Error" 14 "Not Defined" 12 "Gear 9" 11 "Gear 8" 8 "Gear R" 7 "Gear 7" 6 "Gear 6" 5 "Gear 5" 4 "Gear 4" 3 "Gear 3" 2 "Gear 2" 1 "Gear 1" 0 "Gear P/N" ;
VAL_ 6 Sensor_Position 8 "REAR_RIGHT_SENSOR " 4 "REAR_LEFT_SENSOR" 2 "FRONT_RIGHT_SENSOR" 1 "FRONT_LEFT_SENSOR" 0 "unknown" ;
VAL_ env_OFFLINE_ObstacleType 0 "LCA" 1 "CTA" 2 "RCW" 3 "Unused" ;
